VERSION ""

NS_ :

BS_:

BU_: L_DHRR_FD L_UWB_BLE_MST_FD L_UWB_RR_FD L_UWB_BLE_SLV_FD L_UWB_FR_FD L_ROA_FR_FD L_ROA_FD L_DHRL_FD L_UWB_TRNK_FD L_UWB_FRNK_FD L_EDT_FD L_UWB_FL_FD GW_BDC_FD L_UWB_RL_FD L_SAL_FD L_WPC_FD L_TPMS_FD L_DHL_FD L_DHR_FD

BO_ 2348810506 TP_BDC_FD_L_DHRL_FD: 32 GW_BDC_FD
 SG_ TP_BDC_FD_L_DHRL_FD_Byte0 : 0|8@1+ (1,0) [0|0] ""  L_DHRL_FD
 SG_ TP_BDC_FD_L_DHRL_FD_Byte13 : 104|8@1+ (1,0) [0|0] ""  L_DHRL_FD
 SG_ TP_BDC_FD_L_DHRL_FD_Byte14 : 112|8@1+ (1,0) [0|0] ""  L_DHRL_FD
 SG_ TP_BDC_FD_L_DHRL_FD_Byte15 : 120|8@1+ (1,0) [0|0] ""  L_DHRL_FD
 SG_ TP_BDC_FD_L_DHRL_FD_Byte16 : 128|8@1+ (1,0) [0|0] ""  L_DHRL_FD
 SG_ TP_BDC_FD_L_DHRL_FD_Byte17 : 136|8@1+ (1,0) [0|0] ""  L_DHRL_FD
 SG_ TP_BDC_FD_L_DHRL_FD_Byte18 : 144|8@1+ (1,0) [0|0] ""  L_DHRL_FD
 SG_ TP_BDC_FD_L_DHRL_FD_Byte19 : 152|8@1+ (1,0) [0|0] ""  L_DHRL_FD
 SG_ TP_BDC_FD_L_DHRL_FD_Byte2 : 16|8@1+ (1,0) [0|0] ""  L_DHRL_FD
 SG_ TP_BDC_FD_L_DHRL_FD_Byte20 : 160|8@1+ (1,0) [0|0] ""  L_DHRL_FD
 SG_ TP_BDC_FD_L_DHRL_FD_Byte21 : 168|8@1+ (1,0) [0|0] ""  L_DHRL_FD
 SG_ TP_BDC_FD_L_DHRL_FD_Byte22 : 176|8@1+ (1,0) [0|0] ""  L_DHRL_FD
 SG_ TP_BDC_FD_L_DHRL_FD_Byte23 : 184|8@1+ (1,0) [0|0] ""  L_DHRL_FD
 SG_ TP_BDC_FD_L_DHRL_FD_Byte24 : 192|8@1+ (1,0) [0|0] ""  L_DHRL_FD
 SG_ TP_BDC_FD_L_DHRL_FD_Byte25 : 200|8@1+ (1,0) [0|0] ""  L_DHRL_FD
 SG_ TP_BDC_FD_L_DHRL_FD_Byte26 : 208|8@1+ (1,0) [0|0] ""  L_DHRL_FD
 SG_ TP_BDC_FD_L_DHRL_FD_Byte27 : 216|8@1+ (1,0) [0|0] ""  L_DHRL_FD
 SG_ TP_BDC_FD_L_DHRL_FD_Byte28 : 224|8@1+ (1,0) [0|0] ""  L_DHRL_FD
 SG_ TP_BDC_FD_L_DHRL_FD_Byte29 : 232|8@1+ (1,0) [0|0] ""  L_DHRL_FD
 SG_ TP_BDC_FD_L_DHRL_FD_Byte3 : 24|8@1+ (1,0) [0|0] ""  L_DHRL_FD
 SG_ TP_BDC_FD_L_DHRL_FD_Byte30 : 240|8@1+ (1,0) [0|0] ""  L_DHRL_FD
 SG_ TP_BDC_FD_L_DHRL_FD_Byte31 : 248|8@1+ (1,0) [0|0] ""  L_DHRL_FD
 SG_ TP_BDC_FD_L_DHRL_FD_Byte4 : 32|8@1+ (1,0) [0|0] ""  L_DHRL_FD
 SG_ TP_BDC_FD_L_DHRL_FD_Byte5 : 40|8@1+ (1,0) [0|0] ""  L_DHRL_FD
 SG_ TP_BDC_FD_L_DHRL_FD_Byte6 : 48|8@1+ (1,0) [0|0] ""  L_DHRL_FD
 SG_ TP_BDC_FD_L_DHRL_FD_Byte7 : 56|8@1+ (1,0) [0|0] ""  L_DHRL_FD
 SG_ TP_BDC_FD_L_DHRL_FD_Byte8 : 64|8@1+ (1,0) [0|0] ""  L_DHRL_FD
 SG_ TP_BDC_FD_L_DHRL_FD_Byte9 : 72|8@1+ (1,0) [0|0] ""  L_DHRL_FD
 SG_ TP_BDC_FD_L_DHRL_FD_Byte1 : 8|8@1+ (1,0) [0|0] ""  L_DHRL_FD
 SG_ TP_BDC_FD_L_DHRL_FD_Byte10 : 80|8@1+ (1,0) [0|0] ""  L_DHRL_FD
 SG_ TP_BDC_FD_L_DHRL_FD_Byte11 : 88|8@1+ (1,0) [0|0] ""  L_DHRL_FD
 SG_ TP_BDC_FD_L_DHRL_FD_Byte12 : 96|8@1+ (1,0) [0|0] ""  L_DHRL_FD

BO_ 2348810505 L_TP_L_DHR_FD_BDC_FD: 32 L_DHR_FD
 SG_ L_TP_L_DHR_FD_BDC_FD_Byte0 : 0|8@1+ (1,0) [0|0] ""  GW_BDC_FD
 SG_ L_TP_L_DHR_FD_BDC_FD_Byte13 : 104|8@1+ (1,0) [0|0] ""  GW_BDC_FD
 SG_ L_TP_L_DHR_FD_BDC_FD_Byte14 : 112|8@1+ (1,0) [0|0] ""  GW_BDC_FD
 SG_ L_TP_L_DHR_FD_BDC_FD_Byte15 : 120|8@1+ (1,0) [0|0] ""  GW_BDC_FD
 SG_ L_TP_L_DHR_FD_BDC_FD_Byte16 : 128|8@1+ (1,0) [0|0] ""  GW_BDC_FD
 SG_ L_TP_L_DHR_FD_BDC_FD_Byte17 : 136|8@1+ (1,0) [0|0] ""  GW_BDC_FD
 SG_ L_TP_L_DHR_FD_BDC_FD_Byte18 : 144|8@1+ (1,0) [0|0] ""  GW_BDC_FD
 SG_ L_TP_L_DHR_FD_BDC_FD_Byte19 : 152|8@1+ (1,0) [0|0] ""  GW_BDC_FD
 SG_ L_TP_L_DHR_FD_BDC_FD_Byte2 : 16|8@1+ (1,0) [0|0] ""  GW_BDC_FD
 SG_ L_TP_L_DHR_FD_BDC_FD_Byte20 : 160|8@1+ (1,0) [0|0] ""  GW_BDC_FD
 SG_ L_TP_L_DHR_FD_BDC_FD_Byte21 : 168|8@1+ (1,0) [0|0] ""  GW_BDC_FD
 SG_ L_TP_L_DHR_FD_BDC_FD_Byte22 : 176|8@1+ (1,0) [0|0] ""  GW_BDC_FD
 SG_ L_TP_L_DHR_FD_BDC_FD_Byte23 : 184|8@1+ (1,0) [0|0] ""  GW_BDC_FD
 SG_ L_TP_L_DHR_FD_BDC_FD_Byte24 : 192|8@1+ (1,0) [0|0] ""  GW_BDC_FD
 SG_ L_TP_L_DHR_FD_BDC_FD_Byte25 : 200|8@1+ (1,0) [0|0] ""  GW_BDC_FD
 SG_ L_TP_L_DHR_FD_BDC_FD_Byte26 : 208|8@1+ (1,0) [0|0] ""  GW_BDC_FD
 SG_ L_TP_L_DHR_FD_BDC_FD_Byte27 : 216|8@1+ (1,0) [0|0] ""  GW_BDC_FD
 SG_ L_TP_L_DHR_FD_BDC_FD_Byte28 : 224|8@1+ (1,0) [0|0] ""  GW_BDC_FD
 SG_ L_TP_L_DHR_FD_BDC_FD_Byte29 : 232|8@1+ (1,0) [0|0] ""  GW_BDC_FD
 SG_ L_TP_L_DHR_FD_BDC_FD_Byte3 : 24|8@1+ (1,0) [0|0] ""  GW_BDC_FD
 SG_ L_TP_L_DHR_FD_BDC_FD_Byte30 : 240|8@1+ (1,0) [0|0] ""  GW_BDC_FD
 SG_ L_TP_L_DHR_FD_BDC_FD_Byte31 : 248|8@1+ (1,0) [0|0] ""  GW_BDC_FD
 SG_ L_TP_L_DHR_FD_BDC_FD_Byte4 : 32|8@1+ (1,0) [0|0] ""  GW_BDC_FD
 SG_ L_TP_L_DHR_FD_BDC_FD_Byte5 : 40|8@1+ (1,0) [0|0] ""  GW_BDC_FD
 SG_ L_TP_L_DHR_FD_BDC_FD_Byte6 : 48|8@1+ (1,0) [0|0] ""  GW_BDC_FD
 SG_ L_TP_L_DHR_FD_BDC_FD_Byte7 : 56|8@1+ (1,0) [0|0] ""  GW_BDC_FD
 SG_ L_TP_L_DHR_FD_BDC_FD_Byte8 : 64|8@1+ (1,0) [0|0] ""  GW_BDC_FD
 SG_ L_TP_L_DHR_FD_BDC_FD_Byte9 : 72|8@1+ (1,0) [0|0] ""  GW_BDC_FD
 SG_ L_TP_L_DHR_FD_BDC_FD_Byte1 : 8|8@1+ (1,0) [0|0] ""  GW_BDC_FD
 SG_ L_TP_L_DHR_FD_BDC_FD_Byte10 : 80|8@1+ (1,0) [0|0] ""  GW_BDC_FD
 SG_ L_TP_L_DHR_FD_BDC_FD_Byte11 : 88|8@1+ (1,0) [0|0] ""  GW_BDC_FD
 SG_ L_TP_L_DHR_FD_BDC_FD_Byte12 : 96|8@1+ (1,0) [0|0] ""  GW_BDC_FD

BO_ 2348810504 L_TP_BDC_FD_L_DHR_FD: 32 GW_BDC_FD
 SG_ L_TP_BDC_FD_L_DHR_FD_Byte0 : 0|8@1+ (1,0) [0|0] ""  L_DHR_FD
 SG_ L_TP_BDC_FD_L_DHR_FD_Byte13 : 104|8@1+ (1,0) [0|0] ""  L_DHR_FD
 SG_ L_TP_BDC_FD_L_DHR_FD_Byte14 : 112|8@1+ (1,0) [0|0] ""  L_DHR_FD
 SG_ L_TP_BDC_FD_L_DHR_FD_Byte15 : 120|8@1+ (1,0) [0|0] ""  L_DHR_FD
 SG_ L_TP_BDC_FD_L_DHR_FD_Byte16 : 128|8@1+ (1,0) [0|0] ""  L_DHR_FD
 SG_ L_TP_BDC_FD_L_DHR_FD_Byte17 : 136|8@1+ (1,0) [0|0] ""  L_DHR_FD
 SG_ L_TP_BDC_FD_L_DHR_FD_Byte18 : 144|8@1+ (1,0) [0|0] ""  L_DHR_FD
 SG_ L_TP_BDC_FD_L_DHR_FD_Byte19 : 152|8@1+ (1,0) [0|0] ""  L_DHR_FD
 SG_ L_TP_BDC_FD_L_DHR_FD_Byte2 : 16|8@1+ (1,0) [0|0] ""  L_DHR_FD
 SG_ L_TP_BDC_FD_L_DHR_FD_Byte20 : 160|8@1+ (1,0) [0|0] ""  L_DHR_FD
 SG_ L_TP_BDC_FD_L_DHR_FD_Byte21 : 168|8@1+ (1,0) [0|0] ""  L_DHR_FD
 SG_ L_TP_BDC_FD_L_DHR_FD_Byte22 : 176|8@1+ (1,0) [0|0] ""  L_DHR_FD
 SG_ L_TP_BDC_FD_L_DHR_FD_Byte23 : 184|8@1+ (1,0) [0|0] ""  L_DHR_FD
 SG_ L_TP_BDC_FD_L_DHR_FD_Byte24 : 192|8@1+ (1,0) [0|0] ""  L_DHR_FD
 SG_ L_TP_BDC_FD_L_DHR_FD_Byte25 : 200|8@1+ (1,0) [0|0] ""  L_DHR_FD
 SG_ L_TP_BDC_FD_L_DHR_FD_Byte26 : 208|8@1+ (1,0) [0|0] ""  L_DHR_FD
 SG_ L_TP_BDC_FD_L_DHR_FD_Byte27 : 216|8@1+ (1,0) [0|0] ""  L_DHR_FD
 SG_ L_TP_BDC_FD_L_DHR_FD_Byte28 : 224|8@1+ (1,0) [0|0] ""  L_DHR_FD
 SG_ L_TP_BDC_FD_L_DHR_FD_Byte29 : 232|8@1+ (1,0) [0|0] ""  L_DHR_FD
 SG_ L_TP_BDC_FD_L_DHR_FD_Byte3 : 24|8@1+ (1,0) [0|0] ""  L_DHR_FD
 SG_ L_TP_BDC_FD_L_DHR_FD_Byte30 : 240|8@1+ (1,0) [0|0] ""  L_DHR_FD
 SG_ L_TP_BDC_FD_L_DHR_FD_Byte31 : 248|8@1+ (1,0) [0|0] ""  L_DHR_FD
 SG_ L_TP_BDC_FD_L_DHR_FD_Byte4 : 32|8@1+ (1,0) [0|0] ""  L_DHR_FD
 SG_ L_TP_BDC_FD_L_DHR_FD_Byte5 : 40|8@1+ (1,0) [0|0] ""  L_DHR_FD
 SG_ L_TP_BDC_FD_L_DHR_FD_Byte6 : 48|8@1+ (1,0) [0|0] ""  L_DHR_FD
 SG_ L_TP_BDC_FD_L_DHR_FD_Byte7 : 56|8@1+ (1,0) [0|0] ""  L_DHR_FD
 SG_ L_TP_BDC_FD_L_DHR_FD_Byte8 : 64|8@1+ (1,0) [0|0] ""  L_DHR_FD
 SG_ L_TP_BDC_FD_L_DHR_FD_Byte9 : 72|8@1+ (1,0) [0|0] ""  L_DHR_FD
 SG_ L_TP_BDC_FD_L_DHR_FD_Byte1 : 8|8@1+ (1,0) [0|0] ""  L_DHR_FD
 SG_ L_TP_BDC_FD_L_DHR_FD_Byte10 : 80|8@1+ (1,0) [0|0] ""  L_DHR_FD
 SG_ L_TP_BDC_FD_L_DHR_FD_Byte11 : 88|8@1+ (1,0) [0|0] ""  L_DHR_FD
 SG_ L_TP_BDC_FD_L_DHR_FD_Byte12 : 96|8@1+ (1,0) [0|0] ""  L_DHR_FD

BO_ 2348810503 L_TP_L_DHL_FD_BDC_FD: 32 L_DHL_FD
 SG_ L_TP_L_DHL_FD_BDC_FD_Byte0 : 0|8@1+ (1,0) [0|0] ""  GW_BDC_FD
 SG_ L_TP_L_DHL_FD_BDC_FD_Byte13 : 104|8@1+ (1,0) [0|0] ""  GW_BDC_FD
 SG_ L_TP_L_DHL_FD_BDC_FD_Byte14 : 112|8@1+ (1,0) [0|0] ""  GW_BDC_FD
 SG_ L_TP_L_DHL_FD_BDC_FD_Byte15 : 120|8@1+ (1,0) [0|0] ""  GW_BDC_FD
 SG_ L_TP_L_DHL_FD_BDC_FD_Byte16 : 128|8@1+ (1,0) [0|0] ""  GW_BDC_FD
 SG_ L_TP_L_DHL_FD_BDC_FD_Byte17 : 136|8@1+ (1,0) [0|0] ""  GW_BDC_FD
 SG_ L_TP_L_DHL_FD_BDC_FD_Byte18 : 144|8@1+ (1,0) [0|0] ""  GW_BDC_FD
 SG_ L_TP_L_DHL_FD_BDC_FD_Byte19 : 152|8@1+ (1,0) [0|0] ""  GW_BDC_FD
 SG_ L_TP_L_DHL_FD_BDC_FD_Byte2 : 16|8@1+ (1,0) [0|0] ""  GW_BDC_FD
 SG_ L_TP_L_DHL_FD_BDC_FD_Byte20 : 160|8@1+ (1,0) [0|0] ""  GW_BDC_FD
 SG_ L_TP_L_DHL_FD_BDC_FD_Byte21 : 168|8@1+ (1,0) [0|0] ""  GW_BDC_FD
 SG_ L_TP_L_DHL_FD_BDC_FD_Byte22 : 176|8@1+ (1,0) [0|0] ""  GW_BDC_FD
 SG_ L_TP_L_DHL_FD_BDC_FD_Byte23 : 184|8@1+ (1,0) [0|0] ""  GW_BDC_FD
 SG_ L_TP_L_DHL_FD_BDC_FD_Byte24 : 192|8@1+ (1,0) [0|0] ""  GW_BDC_FD
 SG_ L_TP_L_DHL_FD_BDC_FD_Byte25 : 200|8@1+ (1,0) [0|0] ""  GW_BDC_FD
 SG_ L_TP_L_DHL_FD_BDC_FD_Byte26 : 208|8@1+ (1,0) [0|0] ""  GW_BDC_FD
 SG_ L_TP_L_DHL_FD_BDC_FD_Byte27 : 216|8@1+ (1,0) [0|0] ""  GW_BDC_FD
 SG_ L_TP_L_DHL_FD_BDC_FD_Byte28 : 224|8@1+ (1,0) [0|0] ""  GW_BDC_FD
 SG_ L_TP_L_DHL_FD_BDC_FD_Byte29 : 232|8@1+ (1,0) [0|0] ""  GW_BDC_FD
 SG_ L_TP_L_DHL_FD_BDC_FD_Byte3 : 24|8@1+ (1,0) [0|0] ""  GW_BDC_FD
 SG_ L_TP_L_DHL_FD_BDC_FD_Byte30 : 240|8@1+ (1,0) [0|0] ""  GW_BDC_FD
 SG_ L_TP_L_DHL_FD_BDC_FD_Byte31 : 248|8@1+ (1,0) [0|0] ""  GW_BDC_FD
 SG_ L_TP_L_DHL_FD_BDC_FD_Byte4 : 32|8@1+ (1,0) [0|0] ""  GW_BDC_FD
 SG_ L_TP_L_DHL_FD_BDC_FD_Byte5 : 40|8@1+ (1,0) [0|0] ""  GW_BDC_FD
 SG_ L_TP_L_DHL_FD_BDC_FD_Byte6 : 48|8@1+ (1,0) [0|0] ""  GW_BDC_FD
 SG_ L_TP_L_DHL_FD_BDC_FD_Byte7 : 56|8@1+ (1,0) [0|0] ""  GW_BDC_FD
 SG_ L_TP_L_DHL_FD_BDC_FD_Byte8 : 64|8@1+ (1,0) [0|0] ""  GW_BDC_FD
 SG_ L_TP_L_DHL_FD_BDC_FD_Byte9 : 72|8@1+ (1,0) [0|0] ""  GW_BDC_FD
 SG_ L_TP_L_DHL_FD_BDC_FD_Byte1 : 8|8@1+ (1,0) [0|0] ""  GW_BDC_FD
 SG_ L_TP_L_DHL_FD_BDC_FD_Byte10 : 80|8@1+ (1,0) [0|0] ""  GW_BDC_FD
 SG_ L_TP_L_DHL_FD_BDC_FD_Byte11 : 88|8@1+ (1,0) [0|0] ""  GW_BDC_FD
 SG_ L_TP_L_DHL_FD_BDC_FD_Byte12 : 96|8@1+ (1,0) [0|0] ""  GW_BDC_FD

BO_ 2214592660 L_DHR_FD_Dvp_01_00ms: 32 L_DHR_FD
 SG_ DHR_Dvp_Msg : 0|255@1+ (1,0) [0|0] ""  L_EDT_FD

BO_ 2348810502 L_TP_BDC_FD_L_DHL_FD: 32 GW_BDC_FD
 SG_ L_TP_BDC_FD_L_DHL_FD_Byte0 : 0|8@1+ (1,0) [0|0] ""  L_DHL_FD
 SG_ L_TP_BDC_FD_L_DHL_FD_Byte13 : 104|8@1+ (1,0) [0|0] ""  L_DHL_FD
 SG_ L_TP_BDC_FD_L_DHL_FD_Byte14 : 112|8@1+ (1,0) [0|0] ""  L_DHL_FD
 SG_ L_TP_BDC_FD_L_DHL_FD_Byte15 : 120|8@1+ (1,0) [0|0] ""  L_DHL_FD
 SG_ L_TP_BDC_FD_L_DHL_FD_Byte16 : 128|8@1+ (1,0) [0|0] ""  L_DHL_FD
 SG_ L_TP_BDC_FD_L_DHL_FD_Byte17 : 136|8@1+ (1,0) [0|0] ""  L_DHL_FD
 SG_ L_TP_BDC_FD_L_DHL_FD_Byte18 : 144|8@1+ (1,0) [0|0] ""  L_DHL_FD
 SG_ L_TP_BDC_FD_L_DHL_FD_Byte19 : 152|8@1+ (1,0) [0|0] ""  L_DHL_FD
 SG_ L_TP_BDC_FD_L_DHL_FD_Byte2 : 16|8@1+ (1,0) [0|0] ""  L_DHL_FD
 SG_ L_TP_BDC_FD_L_DHL_FD_Byte20 : 160|8@1+ (1,0) [0|0] ""  L_DHL_FD
 SG_ L_TP_BDC_FD_L_DHL_FD_Byte21 : 168|8@1+ (1,0) [0|0] ""  L_DHL_FD
 SG_ L_TP_BDC_FD_L_DHL_FD_Byte22 : 176|8@1+ (1,0) [0|0] ""  L_DHL_FD
 SG_ L_TP_BDC_FD_L_DHL_FD_Byte23 : 184|8@1+ (1,0) [0|0] ""  L_DHL_FD
 SG_ L_TP_BDC_FD_L_DHL_FD_Byte24 : 192|8@1+ (1,0) [0|0] ""  L_DHL_FD
 SG_ L_TP_BDC_FD_L_DHL_FD_Byte25 : 200|8@1+ (1,0) [0|0] ""  L_DHL_FD
 SG_ L_TP_BDC_FD_L_DHL_FD_Byte26 : 208|8@1+ (1,0) [0|0] ""  L_DHL_FD
 SG_ L_TP_BDC_FD_L_DHL_FD_Byte27 : 216|8@1+ (1,0) [0|0] ""  L_DHL_FD
 SG_ L_TP_BDC_FD_L_DHL_FD_Byte28 : 224|8@1+ (1,0) [0|0] ""  L_DHL_FD
 SG_ L_TP_BDC_FD_L_DHL_FD_Byte29 : 232|8@1+ (1,0) [0|0] ""  L_DHL_FD
 SG_ L_TP_BDC_FD_L_DHL_FD_Byte3 : 24|8@1+ (1,0) [0|0] ""  L_DHL_FD
 SG_ L_TP_BDC_FD_L_DHL_FD_Byte30 : 240|8@1+ (1,0) [0|0] ""  L_DHL_FD
 SG_ L_TP_BDC_FD_L_DHL_FD_Byte31 : 248|8@1+ (1,0) [0|0] ""  L_DHL_FD
 SG_ L_TP_BDC_FD_L_DHL_FD_Byte4 : 32|8@1+ (1,0) [0|0] ""  L_DHL_FD
 SG_ L_TP_BDC_FD_L_DHL_FD_Byte5 : 40|8@1+ (1,0) [0|0] ""  L_DHL_FD
 SG_ L_TP_BDC_FD_L_DHL_FD_Byte6 : 48|8@1+ (1,0) [0|0] ""  L_DHL_FD
 SG_ L_TP_BDC_FD_L_DHL_FD_Byte7 : 56|8@1+ (1,0) [0|0] ""  L_DHL_FD
 SG_ L_TP_BDC_FD_L_DHL_FD_Byte8 : 64|8@1+ (1,0) [0|0] ""  L_DHL_FD
 SG_ L_TP_BDC_FD_L_DHL_FD_Byte9 : 72|8@1+ (1,0) [0|0] ""  L_DHL_FD
 SG_ L_TP_BDC_FD_L_DHL_FD_Byte1 : 8|8@1+ (1,0) [0|0] ""  L_DHL_FD
 SG_ L_TP_BDC_FD_L_DHL_FD_Byte10 : 80|8@1+ (1,0) [0|0] ""  L_DHL_FD
 SG_ L_TP_BDC_FD_L_DHL_FD_Byte11 : 88|8@1+ (1,0) [0|0] ""  L_DHL_FD
 SG_ L_TP_BDC_FD_L_DHL_FD_Byte12 : 96|8@1+ (1,0) [0|0] ""  L_DHL_FD

BO_ 2214592661 L_DHRR_FD_Dvp_01_00ms: 32 L_DHRR_FD
 SG_ DHRR_Dvp_Msg : 0|255@1+ (1,0) [0|0] ""  L_EDT_FD

BO_ 2348810501 L_TP_L_WPC_FD_BDC_FD: 32 L_WPC_FD
 SG_ L_TP_L_WPC_FD_BDC_FD_Byte0 : 0|8@1+ (1,0) [0|0] ""  GW_BDC_FD
 SG_ L_TP_L_WPC_FD_BDC_FD_Byte13 : 104|8@1+ (1,0) [0|0] ""  GW_BDC_FD
 SG_ L_TP_L_WPC_FD_BDC_FD_Byte14 : 112|8@1+ (1,0) [0|0] ""  GW_BDC_FD
 SG_ L_TP_L_WPC_FD_BDC_FD_Byte15 : 120|8@1+ (1,0) [0|0] ""  GW_BDC_FD
 SG_ L_TP_L_WPC_FD_BDC_FD_Byte16 : 128|8@1+ (1,0) [0|0] ""  GW_BDC_FD
 SG_ L_TP_L_WPC_FD_BDC_FD_Byte17 : 136|8@1+ (1,0) [0|0] ""  GW_BDC_FD
 SG_ L_TP_L_WPC_FD_BDC_FD_Byte18 : 144|8@1+ (1,0) [0|0] ""  GW_BDC_FD
 SG_ L_TP_L_WPC_FD_BDC_FD_Byte19 : 152|8@1+ (1,0) [0|0] ""  GW_BDC_FD
 SG_ L_TP_L_WPC_FD_BDC_FD_Byte2 : 16|8@1+ (1,0) [0|0] ""  GW_BDC_FD
 SG_ L_TP_L_WPC_FD_BDC_FD_Byte20 : 160|8@1+ (1,0) [0|0] ""  GW_BDC_FD
 SG_ L_TP_L_WPC_FD_BDC_FD_Byte21 : 168|8@1+ (1,0) [0|0] ""  GW_BDC_FD
 SG_ L_TP_L_WPC_FD_BDC_FD_Byte22 : 176|8@1+ (1,0) [0|0] ""  GW_BDC_FD
 SG_ L_TP_L_WPC_FD_BDC_FD_Byte23 : 184|8@1+ (1,0) [0|0] ""  GW_BDC_FD
 SG_ L_TP_L_WPC_FD_BDC_FD_Byte24 : 192|8@1+ (1,0) [0|0] ""  GW_BDC_FD
 SG_ L_TP_L_WPC_FD_BDC_FD_Byte25 : 200|8@1+ (1,0) [0|0] ""  GW_BDC_FD
 SG_ L_TP_L_WPC_FD_BDC_FD_Byte26 : 208|8@1+ (1,0) [0|0] ""  GW_BDC_FD
 SG_ L_TP_L_WPC_FD_BDC_FD_Byte27 : 216|8@1+ (1,0) [0|0] ""  GW_BDC_FD
 SG_ L_TP_L_WPC_FD_BDC_FD_Byte28 : 224|8@1+ (1,0) [0|0] ""  GW_BDC_FD
 SG_ L_TP_L_WPC_FD_BDC_FD_Byte29 : 232|8@1+ (1,0) [0|0] ""  GW_BDC_FD
 SG_ L_TP_L_WPC_FD_BDC_FD_Byte3 : 24|8@1+ (1,0) [0|0] ""  GW_BDC_FD
 SG_ L_TP_L_WPC_FD_BDC_FD_Byte30 : 240|8@1+ (1,0) [0|0] ""  GW_BDC_FD
 SG_ L_TP_L_WPC_FD_BDC_FD_Byte31 : 248|8@1+ (1,0) [0|0] ""  GW_BDC_FD
 SG_ L_TP_L_WPC_FD_BDC_FD_Byte4 : 32|8@1+ (1,0) [0|0] ""  GW_BDC_FD
 SG_ L_TP_L_WPC_FD_BDC_FD_Byte5 : 40|8@1+ (1,0) [0|0] ""  GW_BDC_FD
 SG_ L_TP_L_WPC_FD_BDC_FD_Byte6 : 48|8@1+ (1,0) [0|0] ""  GW_BDC_FD
 SG_ L_TP_L_WPC_FD_BDC_FD_Byte7 : 56|8@1+ (1,0) [0|0] ""  GW_BDC_FD
 SG_ L_TP_L_WPC_FD_BDC_FD_Byte8 : 64|8@1+ (1,0) [0|0] ""  GW_BDC_FD
 SG_ L_TP_L_WPC_FD_BDC_FD_Byte9 : 72|8@1+ (1,0) [0|0] ""  GW_BDC_FD
 SG_ L_TP_L_WPC_FD_BDC_FD_Byte1 : 8|8@1+ (1,0) [0|0] ""  GW_BDC_FD
 SG_ L_TP_L_WPC_FD_BDC_FD_Byte10 : 80|8@1+ (1,0) [0|0] ""  GW_BDC_FD
 SG_ L_TP_L_WPC_FD_BDC_FD_Byte11 : 88|8@1+ (1,0) [0|0] ""  GW_BDC_FD
 SG_ L_TP_L_WPC_FD_BDC_FD_Byte12 : 96|8@1+ (1,0) [0|0] ""  GW_BDC_FD

BO_ 2348810500 L_TP_BDC_FD_L_WPC_FD: 32 GW_BDC_FD
 SG_ L_TP_BDC_FD_L_WPC_FD_Byte0 : 0|8@1+ (1,0) [0|0] ""  L_WPC_FD
 SG_ L_TP_BDC_FD_L_WPC_FD_Byte13 : 104|8@1+ (1,0) [0|0] ""  L_WPC_FD
 SG_ L_TP_BDC_FD_L_WPC_FD_Byte14 : 112|8@1+ (1,0) [0|0] ""  L_WPC_FD
 SG_ L_TP_BDC_FD_L_WPC_FD_Byte15 : 120|8@1+ (1,0) [0|0] ""  L_WPC_FD
 SG_ L_TP_BDC_FD_L_WPC_FD_Byte16 : 128|8@1+ (1,0) [0|0] ""  L_WPC_FD
 SG_ L_TP_BDC_FD_L_WPC_FD_Byte17 : 136|8@1+ (1,0) [0|0] ""  L_WPC_FD
 SG_ L_TP_BDC_FD_L_WPC_FD_Byte18 : 144|8@1+ (1,0) [0|0] ""  L_WPC_FD
 SG_ L_TP_BDC_FD_L_WPC_FD_Byte19 : 152|8@1+ (1,0) [0|0] ""  L_WPC_FD
 SG_ L_TP_BDC_FD_L_WPC_FD_Byte2 : 16|8@1+ (1,0) [0|0] ""  L_WPC_FD
 SG_ L_TP_BDC_FD_L_WPC_FD_Byte20 : 160|8@1+ (1,0) [0|0] ""  L_WPC_FD
 SG_ L_TP_BDC_FD_L_WPC_FD_Byte21 : 168|8@1+ (1,0) [0|0] ""  L_WPC_FD
 SG_ L_TP_BDC_FD_L_WPC_FD_Byte22 : 176|8@1+ (1,0) [0|0] ""  L_WPC_FD
 SG_ L_TP_BDC_FD_L_WPC_FD_Byte23 : 184|8@1+ (1,0) [0|0] ""  L_WPC_FD
 SG_ L_TP_BDC_FD_L_WPC_FD_Byte24 : 192|8@1+ (1,0) [0|0] ""  L_WPC_FD
 SG_ L_TP_BDC_FD_L_WPC_FD_Byte25 : 200|8@1+ (1,0) [0|0] ""  L_WPC_FD
 SG_ L_TP_BDC_FD_L_WPC_FD_Byte26 : 208|8@1+ (1,0) [0|0] ""  L_WPC_FD
 SG_ L_TP_BDC_FD_L_WPC_FD_Byte27 : 216|8@1+ (1,0) [0|0] ""  L_WPC_FD
 SG_ L_TP_BDC_FD_L_WPC_FD_Byte28 : 224|8@1+ (1,0) [0|0] ""  L_WPC_FD
 SG_ L_TP_BDC_FD_L_WPC_FD_Byte29 : 232|8@1+ (1,0) [0|0] ""  L_WPC_FD
 SG_ L_TP_BDC_FD_L_WPC_FD_Byte3 : 24|8@1+ (1,0) [0|0] ""  L_WPC_FD
 SG_ L_TP_BDC_FD_L_WPC_FD_Byte30 : 240|8@1+ (1,0) [0|0] ""  L_WPC_FD
 SG_ L_TP_BDC_FD_L_WPC_FD_Byte31 : 248|8@1+ (1,0) [0|0] ""  L_WPC_FD
 SG_ L_TP_BDC_FD_L_WPC_FD_Byte4 : 32|8@1+ (1,0) [0|0] ""  L_WPC_FD
 SG_ L_TP_BDC_FD_L_WPC_FD_Byte5 : 40|8@1+ (1,0) [0|0] ""  L_WPC_FD
 SG_ L_TP_BDC_FD_L_WPC_FD_Byte6 : 48|8@1+ (1,0) [0|0] ""  L_WPC_FD
 SG_ L_TP_BDC_FD_L_WPC_FD_Byte7 : 56|8@1+ (1,0) [0|0] ""  L_WPC_FD
 SG_ L_TP_BDC_FD_L_WPC_FD_Byte8 : 64|8@1+ (1,0) [0|0] ""  L_WPC_FD
 SG_ L_TP_BDC_FD_L_WPC_FD_Byte9 : 72|8@1+ (1,0) [0|0] ""  L_WPC_FD
 SG_ L_TP_BDC_FD_L_WPC_FD_Byte1 : 8|8@1+ (1,0) [0|0] ""  L_WPC_FD
 SG_ L_TP_BDC_FD_L_WPC_FD_Byte10 : 80|8@1+ (1,0) [0|0] ""  L_WPC_FD
 SG_ L_TP_BDC_FD_L_WPC_FD_Byte11 : 88|8@1+ (1,0) [0|0] ""  L_WPC_FD
 SG_ L_TP_BDC_FD_L_WPC_FD_Byte12 : 96|8@1+ (1,0) [0|0] ""  L_WPC_FD

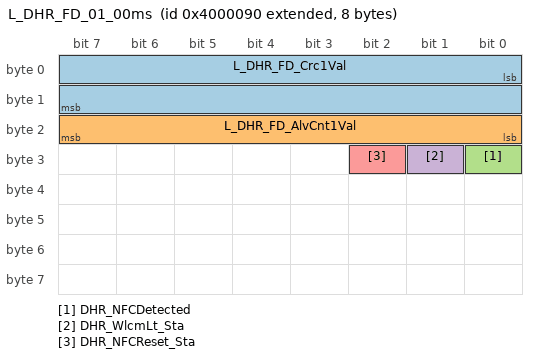
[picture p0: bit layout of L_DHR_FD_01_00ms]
BO_ 2214592656 L_DHR_FD_01_00ms: 8 L_DHR_FD
 SG_ L_DHR_FD_Crc1Val : 0|16@1+ (1,0) [0|0] "0" Vector__XXX
 SG_ L_DHR_FD_AlvCnt1Val : 16|8@1+ (1,0) [0|0] "0" Vector__XXX
 SG_ DHR_NFCDetected : 24|1@1+ (1,0) [0|0] ""  GW_BDC_FD
 SG_ DHR_WlcmLt_Sta : 25|1@1+ (1,0) [0|0] ""  GW_BDC_FD
 SG_ DHR_NFCReset_Sta : 26|1@1+ (1,0) [0|0] ""  GW_BDC_FD

BO_ 2348810499 L_TP_L_UWB_BLE_SLV_FD_BDC_FD: 32 L_UWB_BLE_SLV_FD
 SG_ L_TP_L_UWB_BLE_SLV_FD_BDC_FD_Byt : 0|8@1+ (1,0) [0|0] ""  GW_BDC_FD
 SG_ L_TP_L_UWB_BLE_SLV_FD_BDC_F_0000 : 104|8@1+ (1,0) [0|0] ""  GW_BDC_FD
 SG_ L_TP_L_UWB_BLE_SLV_FD_BDC_F_0001 : 112|8@1+ (1,0) [0|0] ""  GW_BDC_FD
 SG_ L_TP_L_UWB_BLE_SLV_FD_BDC_F_0002 : 120|8@1+ (1,0) [0|0] ""  GW_BDC_FD
 SG_ L_TP_L_UWB_BLE_SLV_FD_BDC_F_0003 : 128|8@1+ (1,0) [0|0] ""  GW_BDC_FD
 SG_ L_TP_L_UWB_BLE_SLV_FD_BDC_F_0004 : 136|8@1+ (1,0) [0|0] ""  GW_BDC_FD
 SG_ L_TP_L_UWB_BLE_SLV_FD_BDC_F_0005 : 144|8@1+ (1,0) [0|0] ""  GW_BDC_FD
 SG_ L_TP_L_UWB_BLE_SLV_FD_BDC_F_0006 : 152|8@1+ (1,0) [0|0] ""  GW_BDC_FD
 SG_ L_TP_L_UWB_BLE_SLV_FD_BDC_F_0007 : 16|8@1+ (1,0) [0|0] ""  GW_BDC_FD
 SG_ L_TP_L_UWB_BLE_SLV_FD_BDC_F_0008 : 160|8@1+ (1,0) [0|0] ""  GW_BDC_FD
 SG_ L_TP_L_UWB_BLE_SLV_FD_BDC_F_0009 : 168|8@1+ (1,0) [0|0] ""  GW_BDC_FD
 SG_ L_TP_L_UWB_BLE_SLV_FD_BDC_F_0010 : 176|8@1+ (1,0) [0|0] ""  GW_BDC_FD
 SG_ L_TP_L_UWB_BLE_SLV_FD_BDC_F_0011 : 184|8@1+ (1,0) [0|0] ""  GW_BDC_FD
 SG_ L_TP_L_UWB_BLE_SLV_FD_BDC_F_0012 : 192|8@1+ (1,0) [0|0] ""  GW_BDC_FD
 SG_ L_TP_L_UWB_BLE_SLV_FD_BDC_F_0013 : 200|8@1+ (1,0) [0|0] ""  GW_BDC_FD
 SG_ L_TP_L_UWB_BLE_SLV_FD_BDC_F_0014 : 208|8@1+ (1,0) [0|0] ""  GW_BDC_FD
 SG_ L_TP_L_UWB_BLE_SLV_FD_BDC_F_0015 : 216|8@1+ (1,0) [0|0] ""  GW_BDC_FD
 SG_ L_TP_L_UWB_BLE_SLV_FD_BDC_F_0016 : 224|8@1+ (1,0) [0|0] ""  GW_BDC_FD
 SG_ L_TP_L_UWB_BLE_SLV_FD_BDC_F_0017 : 232|8@1+ (1,0) [0|0] ""  GW_BDC_FD
 SG_ L_TP_L_UWB_BLE_SLV_FD_BDC_F_0018 : 24|8@1+ (1,0) [0|0] ""  GW_BDC_FD
 SG_ L_TP_L_UWB_BLE_SLV_FD_BDC_F_0019 : 240|8@1+ (1,0) [0|0] ""  GW_BDC_FD
 SG_ L_TP_L_UWB_BLE_SLV_FD_BDC_F_0020 : 248|8@1+ (1,0) [0|0] ""  GW_BDC_FD
 SG_ L_TP_L_UWB_BLE_SLV_FD_BDC_F_0021 : 32|8@1+ (1,0) [0|0] ""  GW_BDC_FD
 SG_ L_TP_L_UWB_BLE_SLV_FD_BDC_F_0022 : 40|8@1+ (1,0) [0|0] ""  GW_BDC_FD
 SG_ L_TP_L_UWB_BLE_SLV_FD_BDC_F_0023 : 48|8@1+ (1,0) [0|0] ""  GW_BDC_FD
 SG_ L_TP_L_UWB_BLE_SLV_FD_BDC_F_0024 : 56|8@1+ (1,0) [0|0] ""  GW_BDC_FD
 SG_ L_TP_L_UWB_BLE_SLV_FD_BDC_F_0025 : 64|8@1+ (1,0) [0|0] ""  GW_BDC_FD
 SG_ L_TP_L_UWB_BLE_SLV_FD_BDC_F_0026 : 72|8@1+ (1,0) [0|0] ""  GW_BDC_FD
 SG_ L_TP_L_UWB_BLE_SLV_FD_BDC_F_0027 : 8|8@1+ (1,0) [0|0] ""  GW_BDC_FD
 SG_ L_TP_L_UWB_BLE_SLV_FD_BDC_F_0028 : 80|8@1+ (1,0) [0|0] ""  GW_BDC_FD
 SG_ L_TP_L_UWB_BLE_SLV_FD_BDC_F_0029 : 88|8@1+ (1,0) [0|0] ""  GW_BDC_FD
 SG_ L_TP_L_UWB_BLE_SLV_FD_BDC_F_0030 : 96|8@1+ (1,0) [0|0] ""  GW_BDC_FD

CM_ BO_ 2348810506 "[TP] Transport Protocol";
CM_ BO_ 2348810505 "[TP] Transport Protocol";
CM_ BO_ 2348810504 "[TP] Transport Protocol";
CM_ BO_ 2348810503 "[TP] Transport Protocol";
CM_ BO_ 2214592660 "[EW] On Event and On Write";
CM_ SG_ 2214592660 DHR_Dvp_Msg "Development Message";
CM_ BO_ 2348810502 "[TP] Transport Protocol";
CM_ BO_ 2214592661 "[EW] On Event and On Write";
CM_ SG_ 2214592661 DHRR_Dvp_Msg "Rear RH Door Development Message";
CM_ BO_ 2348810501 "[TP] Transport Protocol";
CM_ BO_ 2348810500 "[TP] Transport Protocol";
CM_ BO_ 2214592656 "[EC] On Event and On Change";
CM_ SG_ 2214592656 L_DHR_FD_Crc1Val "L_DHR_FD_CyclicRedundancyCheck1Value";
CM_ SG_ 2214592656 L_DHR_FD_AlvCnt1Val "L_DHR_FD_AliveCounter1Value";
CM_ SG_ 2214592656 DHR_NFCDetected "RH Door NFC Sensor Input";
CM_ SG_ 2214592656 DHR_WlcmLt_Sta "RH Door Welcome Light Status";
CM_ SG_ 2214592656 DHR_NFCReset_Sta "RH Door NFC DeSelect Result";
CM_ BO_ 2348810499 "[TP] Transport Protocol";
BA_DEF_ BO_  "CANFD_BRS" ENUM  "0","1";
BA_DEF_ BO_  "GenMsgEVName" STRING ;
BA_DEF_ BO_  "NmAsrMessage" ENUM  "No","Yes";
BA_DEF_ BO_  "DiagState" ENUM  "No","Yes";
BA_DEF_ BO_  "DiagResponse" ENUM  "No","Yes";
BA_DEF_ BO_  "DiagRequest" ENUM  "No","Yes";
BA_DEF_ BO_  "TpMessage" ENUM  "No","Yes";
BA_DEF_ BO_  "UsrMsgIDSforwardDeviation" INT 0 100;
BA_DEF_ BO_  "UsrMsgIDSbackwardDeviation" INT 50 1000;
BA_DEF_ BO_  "GenMsgCycleTime" INT 0 2000;
BA_DEF_ BO_  "GenMsgStartDelayTime" INT 0 2000;
BA_DEF_ BO_  "GenMsgSendType" ENUM  "Cyclic","NoMsgSendType";
BA_DEF_ BO_  "GenMsgCycleTimeFast" INT 0 500;
BA_DEF_ BO_  "GenMsgDelayTime" INT 0 20;
BA_DEF_ BO_  "GenMsgILSupport" ENUM  "No","Yes";
BA_DEF_ BO_  "GenMsgNrOfRepetition" INT 0 3;
BA_DEF_ BO_  "TpTxIndex" INT 0 65535;
BA_DEF_ BO_  "VFrameFormat" ENUM  "StandardCAN","ExtendedCAN","reserved","reserved","reserved","reserved","reserved","reserved","reserved","reserved","reserved","reserved","reserved","reserved","StandardCAN_FD","ExtendedCAN_FD";
BA_DEF_ SG_  "UserSigValidity" ENUM  "B+","ACC","IG","IG1","IG2","IG3","IG1 or IG2","IG1 or IG3","Undef";
BA_DEF_ SG_  "TimeoutValue" STRING ;
BA_DEF_ SG_  "UsrSigPurpose" ENUM  "Undef","FN","DIAG","DIAG(Req)","DIAG(Res)","DIAG(Func)","DEV","CCP","NM","TP";
BA_DEF_ SG_  "GenSigStartValue" INT 0 1215752192;
BA_DEF_ SG_  "NetworkRequest" ENUM  "Yes","No";
BA_DEF_ SG_  "NetworkRequestHoldingTime" INT 0 65535;
BA_DEF_ SG_  "Description" STRING ;
BA_DEF_ SG_  "Version" STRING ;
BA_DEF_ SG_  "GenSigEnvVarType" ENUM  "Int","Float","Undef";
BA_DEF_ SG_  "GenSigSendType" ENUM  "Cyclic","OnWrite","OnWriteWithRepetition","OnChange","OnChangeWithRepetition","IfActive","IfActiveWithRepetition","NoSigSendType","OnChangeAndIfActive","OnChangeAndIfActiveWithRepetition";
BA_DEF_ SG_  "GwSigLatencyTime" INT 0 65536;
BA_DEF_ SG_  "GwSigMissingSourceType" ENUM  "Undef","OldValue","DefaultValue","InitialValue";
BA_DEF_ SG_  "NWM-WakeupAllowed" ENUM  "<n.a.>";
BA_DEF_ SG_  "RoutingFactor" INT 1 1215752192;
BA_DEF_ SG_  "SystemSignalLongSymbol" STRING ;
BA_DEF_REL_ BU_SG_REL_  "GenSigTimeoutTime" INT 0 7000;
BA_DEF_DEF_  "CANFD_BRS" "1";
BA_DEF_DEF_  "GenMsgEVName" "@Signame";
BA_DEF_DEF_  "NmAsrMessage" "No";
BA_DEF_DEF_  "DiagState" "No";
BA_DEF_DEF_  "DiagResponse" "No";
BA_DEF_DEF_  "DiagRequest" "No";
BA_DEF_DEF_  "TpMessage" "No";
BA_DEF_DEF_  "UsrMsgIDSforwardDeviation" 10;
BA_DEF_DEF_  "UsrMsgIDSbackwardDeviation" 100;
BA_DEF_DEF_  "GenMsgCycleTime" 200;
BA_DEF_DEF_  "GenMsgStartDelayTime" 0;
BA_DEF_DEF_  "GenMsgSendType" "NoMsgSendType";
BA_DEF_DEF_  "GenMsgCycleTimeFast" 40;
BA_DEF_DEF_  "GenMsgDelayTime" 20;
BA_DEF_DEF_  "GenMsgILSupport" "Yes";
BA_DEF_DEF_  "GenMsgNrOfRepetition" 3;
BA_DEF_DEF_  "TpTxIndex" 0;
BA_DEF_DEF_  "VFrameFormat" "StandardCAN";
BA_DEF_DEF_  "UserSigValidity" "IG";
BA_DEF_DEF_  "TimeoutValue" "";
BA_DEF_DEF_  "UsrSigPurpose" "FN";
BA_DEF_DEF_  "GenSigStartValue" 0;
BA_DEF_DEF_  "NetworkRequest" "No";
BA_DEF_DEF_  "NetworkRequestHoldingTime" 0;
BA_DEF_DEF_  "Description" "";
BA_DEF_DEF_  "Version" "";
BA_DEF_DEF_  "GenSigEnvVarType" "Undef";
BA_DEF_DEF_  "GenSigSendType" "NoSigSendType";
BA_DEF_DEF_  "GwSigLatencyTime" 40;
BA_DEF_DEF_  "GwSigMissingSourceType" "Undef";
BA_DEF_DEF_  "NWM-WakeupAllowed" "<n.a.>";
BA_DEF_DEF_  "RoutingFactor" 1;
BA_DEF_DEF_REL_ "GenSigTimeoutTime" 500;
BA_DEF_DEF_  "SystemSignalLongSymbol" "";
BA_ "TpTxIndex" BO_ 2348810506 275;
BA_ "TpMessage" BO_ 2348810506 1;
BA_ "GenMsgILSupport" BO_ 2348810506 0;
BA_ "GenMsgNrOfRepetition" BO_ 2348810506 0;
BA_ "GenMsgCycleTimeFast" BO_ 2348810506 0;
BA_ "GenMsgCycleTime" BO_ 2348810506 0;
BA_ "VFrameFormat" BO_ 2348810506 15;
BA_ "TpTxIndex" BO_ 2348810505 274;
BA_ "TpMessage" BO_ 2348810505 1;
BA_ "GenMsgILSupport" BO_ 2348810505 0;
BA_ "GenMsgNrOfRepetition" BO_ 2348810505 0;
BA_ "GenMsgCycleTimeFast" BO_ 2348810505 0;
BA_ "GenMsgCycleTime" BO_ 2348810505 0;
BA_ "VFrameFormat" BO_ 2348810505 15;
BA_ "TpTxIndex" BO_ 2348810504 274;
BA_ "TpMessage" BO_ 2348810504 1;
BA_ "GenMsgILSupport" BO_ 2348810504 0;
BA_ "GenMsgNrOfRepetition" BO_ 2348810504 0;
BA_ "GenMsgCycleTimeFast" BO_ 2348810504 0;
BA_ "GenMsgCycleTime" BO_ 2348810504 0;
BA_ "VFrameFormat" BO_ 2348810504 15;
BA_ "TpTxIndex" BO_ 2348810503 273;
BA_ "TpMessage" BO_ 2348810503 1;
BA_ "GenMsgILSupport" BO_ 2348810503 0;
BA_ "GenMsgNrOfRepetition" BO_ 2348810503 0;
BA_ "GenMsgCycleTimeFast" BO_ 2348810503 0;
BA_ "GenMsgCycleTime" BO_ 2348810503 0;
BA_ "VFrameFormat" BO_ 2348810503 15;
BA_ "GenMsgDelayTime" BO_ 2214592660 10;
BA_ "GenMsgCycleTime" BO_ 2214592660 0;
BA_ "VFrameFormat" BO_ 2214592660 15;
BA_ "TpTxIndex" BO_ 2348810502 273;
BA_ "TpMessage" BO_ 2348810502 1;
BA_ "GenMsgILSupport" BO_ 2348810502 0;
BA_ "GenMsgNrOfRepetition" BO_ 2348810502 0;
BA_ "GenMsgCycleTimeFast" BO_ 2348810502 0;
BA_ "GenMsgCycleTime" BO_ 2348810502 0;
BA_ "VFrameFormat" BO_ 2348810502 15;
BA_ "GenMsgDelayTime" BO_ 2214592661 10;
BA_ "GenMsgCycleTime" BO_ 2214592661 0;
BA_ "VFrameFormat" BO_ 2214592661 15;
BA_ "TpTxIndex" BO_ 2348810501 272;
BA_ "TpMessage" BO_ 2348810501 1;
BA_ "GenMsgILSupport" BO_ 2348810501 0;
BA_ "GenMsgNrOfRepetition" BO_ 2348810501 0;
BA_ "GenMsgCycleTimeFast" BO_ 2348810501 0;
BA_ "GenMsgCycleTime" BO_ 2348810501 0;
BA_ "VFrameFormat" BO_ 2348810501 15;
BA_ "TpTxIndex" BO_ 2348810500 272;
BA_ "TpMessage" BO_ 2348810500 1;
BA_ "GenMsgILSupport" BO_ 2348810500 0;
BA_ "GenMsgNrOfRepetition" BO_ 2348810500 0;
BA_ "GenMsgCycleTimeFast" BO_ 2348810500 0;
BA_ "GenMsgCycleTime" BO_ 2348810500 0;
BA_ "VFrameFormat" BO_ 2348810500 15;
BA_ "GenMsgCycleTime" BO_ 2214592656 0;
BA_ "VFrameFormat" BO_ 2214592656 15;
BA_ "TpTxIndex" BO_ 2348810499 271;
BA_ "TpMessage" BO_ 2348810499 1;
BA_ "GenMsgILSupport" BO_ 2348810499 0;
BA_ "GenMsgNrOfRepetition" BO_ 2348810499 0;
BA_ "GenMsgCycleTimeFast" BO_ 2348810499 0;
BA_ "GenMsgCycleTime" BO_ 2348810499 0;
BA_ "VFrameFormat" BO_ 2348810499 15;
BA_ "Version" SG_ 2348810506 TP_BDC_FD_L_DHRL_FD_Byte0 "23.06.01";
BA_ "NetworkRequestHoldingTime" SG_ 2348810506 TP_BDC_FD_L_DHRL_FD_Byte0 5000;
BA_ "NetworkRequest" SG_ 2348810506 TP_BDC_FD_L_DHRL_FD_Byte0 0;
BA_ "UserSigValidity" SG_ 2348810506 TP_BDC_FD_L_DHRL_FD_Byte0 0;
BA_ "UsrSigPurpose" SG_ 2348810506 TP_BDC_FD_L_DHRL_FD_Byte0 9;
BA_ "Description" SG_ 2348810506 TP_BDC_FD_L_DHRL_FD_Byte0 "TP Index : 275";
BA_ "Version" SG_ 2348810506 TP_BDC_FD_L_DHRL_FD_Byte13 "23.06.01";
BA_ "NetworkRequestHoldingTime" SG_ 2348810506 TP_BDC_FD_L_DHRL_FD_Byte13 5000;
BA_ "NetworkRequest" SG_ 2348810506 TP_BDC_FD_L_DHRL_FD_Byte13 0;
BA_ "UserSigValidity" SG_ 2348810506 TP_BDC_FD_L_DHRL_FD_Byte13 0;
BA_ "UsrSigPurpose" SG_ 2348810506 TP_BDC_FD_L_DHRL_FD_Byte13 9;
BA_ "Description" SG_ 2348810506 TP_BDC_FD_L_DHRL_FD_Byte13 "TP Index : 275";
BA_ "Version" SG_ 2348810506 TP_BDC_FD_L_DHRL_FD_Byte14 "23.06.01";
BA_ "NetworkRequestHoldingTime" SG_ 2348810506 TP_BDC_FD_L_DHRL_FD_Byte14 5000;
BA_ "NetworkRequest" SG_ 2348810506 TP_BDC_FD_L_DHRL_FD_Byte14 0;
BA_ "UserSigValidity" SG_ 2348810506 TP_BDC_FD_L_DHRL_FD_Byte14 0;
BA_ "UsrSigPurpose" SG_ 2348810506 TP_BDC_FD_L_DHRL_FD_Byte14 9;
BA_ "Description" SG_ 2348810506 TP_BDC_FD_L_DHRL_FD_Byte14 "TP Index : 275";
BA_ "Version" SG_ 2348810506 TP_BDC_FD_L_DHRL_FD_Byte15 "23.06.01";
BA_ "NetworkRequestHoldingTime" SG_ 2348810506 TP_BDC_FD_L_DHRL_FD_Byte15 5000;
BA_ "NetworkRequest" SG_ 2348810506 TP_BDC_FD_L_DHRL_FD_Byte15 0;
BA_ "UserSigValidity" SG_ 2348810506 TP_BDC_FD_L_DHRL_FD_Byte15 0;
BA_ "UsrSigPurpose" SG_ 2348810506 TP_BDC_FD_L_DHRL_FD_Byte15 9;
BA_ "Description" SG_ 2348810506 TP_BDC_FD_L_DHRL_FD_Byte15 "TP Index : 275";
BA_ "Version" SG_ 2348810506 TP_BDC_FD_L_DHRL_FD_Byte16 "23.06.01";
BA_ "NetworkRequestHoldingTime" SG_ 2348810506 TP_BDC_FD_L_DHRL_FD_Byte16 5000;
BA_ "NetworkRequest" SG_ 2348810506 TP_BDC_FD_L_DHRL_FD_Byte16 0;
BA_ "UserSigValidity" SG_ 2348810506 TP_BDC_FD_L_DHRL_FD_Byte16 0;
BA_ "UsrSigPurpose" SG_ 2348810506 TP_BDC_FD_L_DHRL_FD_Byte16 9;
BA_ "Description" SG_ 2348810506 TP_BDC_FD_L_DHRL_FD_Byte16 "TP Index : 275";
BA_ "Version" SG_ 2348810506 TP_BDC_FD_L_DHRL_FD_Byte17 "23.06.01";
BA_ "NetworkRequestHoldingTime" SG_ 2348810506 TP_BDC_FD_L_DHRL_FD_Byte17 5000;
BA_ "NetworkRequest" SG_ 2348810506 TP_BDC_FD_L_DHRL_FD_Byte17 0;
BA_ "UserSigValidity" SG_ 2348810506 TP_BDC_FD_L_DHRL_FD_Byte17 0;
BA_ "UsrSigPurpose" SG_ 2348810506 TP_BDC_FD_L_DHRL_FD_Byte17 9;
BA_ "Description" SG_ 2348810506 TP_BDC_FD_L_DHRL_FD_Byte17 "TP Index : 275";
BA_ "Version" SG_ 2348810506 TP_BDC_FD_L_DHRL_FD_Byte18 "23.06.01";
BA_ "NetworkRequestHoldingTime" SG_ 2348810506 TP_BDC_FD_L_DHRL_FD_Byte18 5000;
BA_ "NetworkRequest" SG_ 2348810506 TP_BDC_FD_L_DHRL_FD_Byte18 0;
BA_ "UserSigValidity" SG_ 2348810506 TP_BDC_FD_L_DHRL_FD_Byte18 0;
BA_ "UsrSigPurpose" SG_ 2348810506 TP_BDC_FD_L_DHRL_FD_Byte18 9;
BA_ "Description" SG_ 2348810506 TP_BDC_FD_L_DHRL_FD_Byte18 "TP Index : 275";
BA_ "Version" SG_ 2348810506 TP_BDC_FD_L_DHRL_FD_Byte19 "23.06.01";
BA_ "NetworkRequestHoldingTime" SG_ 2348810506 TP_BDC_FD_L_DHRL_FD_Byte19 5000;
BA_ "NetworkRequest" SG_ 2348810506 TP_BDC_FD_L_DHRL_FD_Byte19 0;
BA_ "UserSigValidity" SG_ 2348810506 TP_BDC_FD_L_DHRL_FD_Byte19 0;
BA_ "UsrSigPurpose" SG_ 2348810506 TP_BDC_FD_L_DHRL_FD_Byte19 9;
BA_ "Description" SG_ 2348810506 TP_BDC_FD_L_DHRL_FD_Byte19 "TP Index : 275";
BA_ "Version" SG_ 2348810506 TP_BDC_FD_L_DHRL_FD_Byte2 "23.06.01";
BA_ "NetworkRequestHoldingTime" SG_ 2348810506 TP_BDC_FD_L_DHRL_FD_Byte2 5000;
BA_ "NetworkRequest" SG_ 2348810506 TP_BDC_FD_L_DHRL_FD_Byte2 0;
BA_ "UserSigValidity" SG_ 2348810506 TP_BDC_FD_L_DHRL_FD_Byte2 0;
BA_ "UsrSigPurpose" SG_ 2348810506 TP_BDC_FD_L_DHRL_FD_Byte2 9;
BA_ "Description" SG_ 2348810506 TP_BDC_FD_L_DHRL_FD_Byte2 "TP Index : 275";
BA_ "Version" SG_ 2348810506 TP_BDC_FD_L_DHRL_FD_Byte20 "23.06.01";
BA_ "NetworkRequestHoldingTime" SG_ 2348810506 TP_BDC_FD_L_DHRL_FD_Byte20 5000;
BA_ "NetworkRequest" SG_ 2348810506 TP_BDC_FD_L_DHRL_FD_Byte20 0;
BA_ "UserSigValidity" SG_ 2348810506 TP_BDC_FD_L_DHRL_FD_Byte20 0;
BA_ "UsrSigPurpose" SG_ 2348810506 TP_BDC_FD_L_DHRL_FD_Byte20 9;
BA_ "Description" SG_ 2348810506 TP_BDC_FD_L_DHRL_FD_Byte20 "TP Index : 275";
BA_ "Version" SG_ 2348810506 TP_BDC_FD_L_DHRL_FD_Byte21 "23.06.01";
BA_ "NetworkRequestHoldingTime" SG_ 2348810506 TP_BDC_FD_L_DHRL_FD_Byte21 5000;
BA_ "NetworkRequest" SG_ 2348810506 TP_BDC_FD_L_DHRL_FD_Byte21 0;
BA_ "UserSigValidity" SG_ 2348810506 TP_BDC_FD_L_DHRL_FD_Byte21 0;
BA_ "UsrSigPurpose" SG_ 2348810506 TP_BDC_FD_L_DHRL_FD_Byte21 9;
BA_ "Description" SG_ 2348810506 TP_BDC_FD_L_DHRL_FD_Byte21 "TP Index : 275";
BA_ "Version" SG_ 2348810506 TP_BDC_FD_L_DHRL_FD_Byte22 "23.06.01";
BA_ "NetworkRequestHoldingTime" SG_ 2348810506 TP_BDC_FD_L_DHRL_FD_Byte22 5000;
BA_ "NetworkRequest" SG_ 2348810506 TP_BDC_FD_L_DHRL_FD_Byte22 0;
BA_ "UserSigValidity" SG_ 2348810506 TP_BDC_FD_L_DHRL_FD_Byte22 0;
BA_ "UsrSigPurpose" SG_ 2348810506 TP_BDC_FD_L_DHRL_FD_Byte22 9;
BA_ "Description" SG_ 2348810506 TP_BDC_FD_L_DHRL_FD_Byte22 "TP Index : 275";
BA_ "Version" SG_ 2348810506 TP_BDC_FD_L_DHRL_FD_Byte23 "23.06.01";
BA_ "NetworkRequestHoldingTime" SG_ 2348810506 TP_BDC_FD_L_DHRL_FD_Byte23 5000;
BA_ "NetworkRequest" SG_ 2348810506 TP_BDC_FD_L_DHRL_FD_Byte23 0;
BA_ "UserSigValidity" SG_ 2348810506 TP_BDC_FD_L_DHRL_FD_Byte23 0;
BA_ "UsrSigPurpose" SG_ 2348810506 TP_BDC_FD_L_DHRL_FD_Byte23 9;
BA_ "Description" SG_ 2348810506 TP_BDC_FD_L_DHRL_FD_Byte23 "TP Index : 275";
BA_ "Version" SG_ 2348810506 TP_BDC_FD_L_DHRL_FD_Byte24 "23.06.01";
BA_ "NetworkRequestHoldingTime" SG_ 2348810506 TP_BDC_FD_L_DHRL_FD_Byte24 5000;
BA_ "NetworkRequest" SG_ 2348810506 TP_BDC_FD_L_DHRL_FD_Byte24 0;
BA_ "UserSigValidity" SG_ 2348810506 TP_BDC_FD_L_DHRL_FD_Byte24 0;
BA_ "UsrSigPurpose" SG_ 2348810506 TP_BDC_FD_L_DHRL_FD_Byte24 9;
BA_ "Description" SG_ 2348810506 TP_BDC_FD_L_DHRL_FD_Byte24 "TP Index : 275";
BA_ "Version" SG_ 2348810506 TP_BDC_FD_L_DHRL_FD_Byte25 "23.06.01";
BA_ "NetworkRequestHoldingTime" SG_ 2348810506 TP_BDC_FD_L_DHRL_FD_Byte25 5000;
BA_ "NetworkRequest" SG_ 2348810506 TP_BDC_FD_L_DHRL_FD_Byte25 0;
BA_ "UserSigValidity" SG_ 2348810506 TP_BDC_FD_L_DHRL_FD_Byte25 0;
BA_ "UsrSigPurpose" SG_ 2348810506 TP_BDC_FD_L_DHRL_FD_Byte25 9;
BA_ "Description" SG_ 2348810506 TP_BDC_FD_L_DHRL_FD_Byte25 "TP Index : 275";
BA_ "Version" SG_ 2348810506 TP_BDC_FD_L_DHRL_FD_Byte26 "23.06.01";
BA_ "NetworkRequestHoldingTime" SG_ 2348810506 TP_BDC_FD_L_DHRL_FD_Byte26 5000;
BA_ "NetworkRequest" SG_ 2348810506 TP_BDC_FD_L_DHRL_FD_Byte26 0;
BA_ "UserSigValidity" SG_ 2348810506 TP_BDC_FD_L_DHRL_FD_Byte26 0;
BA_ "UsrSigPurpose" SG_ 2348810506 TP_BDC_FD_L_DHRL_FD_Byte26 9;
BA_ "Description" SG_ 2348810506 TP_BDC_FD_L_DHRL_FD_Byte26 "TP Index : 275";
BA_ "Version" SG_ 2348810506 TP_BDC_FD_L_DHRL_FD_Byte27 "23.06.01";
BA_ "NetworkRequestHoldingTime" SG_ 2348810506 TP_BDC_FD_L_DHRL_FD_Byte27 5000;
BA_ "NetworkRequest" SG_ 2348810506 TP_BDC_FD_L_DHRL_FD_Byte27 0;
BA_ "UserSigValidity" SG_ 2348810506 TP_BDC_FD_L_DHRL_FD_Byte27 0;
BA_ "UsrSigPurpose" SG_ 2348810506 TP_BDC_FD_L_DHRL_FD_Byte27 9;
BA_ "Description" SG_ 2348810506 TP_BDC_FD_L_DHRL_FD_Byte27 "TP Index : 275";
BA_ "Version" SG_ 2348810506 TP_BDC_FD_L_DHRL_FD_Byte28 "23.06.01";
BA_ "NetworkRequestHoldingTime" SG_ 2348810506 TP_BDC_FD_L_DHRL_FD_Byte28 5000;
BA_ "NetworkRequest" SG_ 2348810506 TP_BDC_FD_L_DHRL_FD_Byte28 0;
BA_ "UserSigValidity" SG_ 2348810506 TP_BDC_FD_L_DHRL_FD_Byte28 0;
BA_ "UsrSigPurpose" SG_ 2348810506 TP_BDC_FD_L_DHRL_FD_Byte28 9;
BA_ "Description" SG_ 2348810506 TP_BDC_FD_L_DHRL_FD_Byte28 "TP Index : 275";
BA_ "Version" SG_ 2348810506 TP_BDC_FD_L_DHRL_FD_Byte29 "23.06.01";
BA_ "NetworkRequestHoldingTime" SG_ 2348810506 TP_BDC_FD_L_DHRL_FD_Byte29 5000;
BA_ "NetworkRequest" SG_ 2348810506 TP_BDC_FD_L_DHRL_FD_Byte29 0;
BA_ "UserSigValidity" SG_ 2348810506 TP_BDC_FD_L_DHRL_FD_Byte29 0;
BA_ "UsrSigPurpose" SG_ 2348810506 TP_BDC_FD_L_DHRL_FD_Byte29 9;
BA_ "Description" SG_ 2348810506 TP_BDC_FD_L_DHRL_FD_Byte29 "TP Index : 275";
BA_ "Version" SG_ 2348810506 TP_BDC_FD_L_DHRL_FD_Byte3 "23.06.01";
BA_ "NetworkRequestHoldingTime" SG_ 2348810506 TP_BDC_FD_L_DHRL_FD_Byte3 5000;
BA_ "NetworkRequest" SG_ 2348810506 TP_BDC_FD_L_DHRL_FD_Byte3 0;
BA_ "UserSigValidity" SG_ 2348810506 TP_BDC_FD_L_DHRL_FD_Byte3 0;
BA_ "UsrSigPurpose" SG_ 2348810506 TP_BDC_FD_L_DHRL_FD_Byte3 9;
BA_ "Description" SG_ 2348810506 TP_BDC_FD_L_DHRL_FD_Byte3 "TP Index : 275";
BA_ "Version" SG_ 2348810506 TP_BDC_FD_L_DHRL_FD_Byte30 "23.06.01";
BA_ "NetworkRequestHoldingTime" SG_ 2348810506 TP_BDC_FD_L_DHRL_FD_Byte30 5000;
BA_ "NetworkRequest" SG_ 2348810506 TP_BDC_FD_L_DHRL_FD_Byte30 0;
BA_ "UserSigValidity" SG_ 2348810506 TP_BDC_FD_L_DHRL_FD_Byte30 0;
BA_ "UsrSigPurpose" SG_ 2348810506 TP_BDC_FD_L_DHRL_FD_Byte30 9;
BA_ "Description" SG_ 2348810506 TP_BDC_FD_L_DHRL_FD_Byte30 "TP Index : 275";
BA_ "Version" SG_ 2348810506 TP_BDC_FD_L_DHRL_FD_Byte31 "23.06.01";
BA_ "NetworkRequestHoldingTime" SG_ 2348810506 TP_BDC_FD_L_DHRL_FD_Byte31 5000;
BA_ "NetworkRequest" SG_ 2348810506 TP_BDC_FD_L_DHRL_FD_Byte31 0;
BA_ "UserSigValidity" SG_ 2348810506 TP_BDC_FD_L_DHRL_FD_Byte31 0;
BA_ "UsrSigPurpose" SG_ 2348810506 TP_BDC_FD_L_DHRL_FD_Byte31 9;
BA_ "Description" SG_ 2348810506 TP_BDC_FD_L_DHRL_FD_Byte31 "TP Index : 275";
BA_ "Version" SG_ 2348810506 TP_BDC_FD_L_DHRL_FD_Byte4 "23.06.01";
BA_ "NetworkRequestHoldingTime" SG_ 2348810506 TP_BDC_FD_L_DHRL_FD_Byte4 5000;
BA_ "NetworkRequest" SG_ 2348810506 TP_BDC_FD_L_DHRL_FD_Byte4 0;
BA_ "UserSigValidity" SG_ 2348810506 TP_BDC_FD_L_DHRL_FD_Byte4 0;
BA_ "UsrSigPurpose" SG_ 2348810506 TP_BDC_FD_L_DHRL_FD_Byte4 9;
BA_ "Description" SG_ 2348810506 TP_BDC_FD_L_DHRL_FD_Byte4 "TP Index : 275";
BA_ "Version" SG_ 2348810506 TP_BDC_FD_L_DHRL_FD_Byte5 "23.06.01";
BA_ "NetworkRequestHoldingTime" SG_ 2348810506 TP_BDC_FD_L_DHRL_FD_Byte5 5000;
BA_ "NetworkRequest" SG_ 2348810506 TP_BDC_FD_L_DHRL_FD_Byte5 0;
BA_ "UserSigValidity" SG_ 2348810506 TP_BDC_FD_L_DHRL_FD_Byte5 0;
BA_ "UsrSigPurpose" SG_ 2348810506 TP_BDC_FD_L_DHRL_FD_Byte5 9;
BA_ "Description" SG_ 2348810506 TP_BDC_FD_L_DHRL_FD_Byte5 "TP Index : 275";
BA_ "Version" SG_ 2348810506 TP_BDC_FD_L_DHRL_FD_Byte6 "23.06.01";
BA_ "NetworkRequestHoldingTime" SG_ 2348810506 TP_BDC_FD_L_DHRL_FD_Byte6 5000;
BA_ "NetworkRequest" SG_ 2348810506 TP_BDC_FD_L_DHRL_FD_Byte6 0;
BA_ "UserSigValidity" SG_ 2348810506 TP_BDC_FD_L_DHRL_FD_Byte6 0;
BA_ "UsrSigPurpose" SG_ 2348810506 TP_BDC_FD_L_DHRL_FD_Byte6 9;
BA_ "Description" SG_ 2348810506 TP_BDC_FD_L_DHRL_FD_Byte6 "TP Index : 275";
BA_ "Version" SG_ 2348810506 TP_BDC_FD_L_DHRL_FD_Byte7 "23.06.01";
BA_ "NetworkRequestHoldingTime" SG_ 2348810506 TP_BDC_FD_L_DHRL_FD_Byte7 5000;
BA_ "NetworkRequest" SG_ 2348810506 TP_BDC_FD_L_DHRL_FD_Byte7 0;
BA_ "UserSigValidity" SG_ 2348810506 TP_BDC_FD_L_DHRL_FD_Byte7 0;
BA_ "UsrSigPurpose" SG_ 2348810506 TP_BDC_FD_L_DHRL_FD_Byte7 9;
BA_ "Description" SG_ 2348810506 TP_BDC_FD_L_DHRL_FD_Byte7 "TP Index : 275";
BA_ "Version" SG_ 2348810506 TP_BDC_FD_L_DHRL_FD_Byte8 "23.06.01";
BA_ "NetworkRequestHoldingTime" SG_ 2348810506 TP_BDC_FD_L_DHRL_FD_Byte8 5000;
BA_ "NetworkRequest" SG_ 2348810506 TP_BDC_FD_L_DHRL_FD_Byte8 0;
BA_ "UserSigValidity" SG_ 2348810506 TP_BDC_FD_L_DHRL_FD_Byte8 0;
BA_ "UsrSigPurpose" SG_ 2348810506 TP_BDC_FD_L_DHRL_FD_Byte8 9;
BA_ "Description" SG_ 2348810506 TP_BDC_FD_L_DHRL_FD_Byte8 "TP Index : 275";
BA_ "Version" SG_ 2348810506 TP_BDC_FD_L_DHRL_FD_Byte9 "23.06.01";
BA_ "NetworkRequestHoldingTime" SG_ 2348810506 TP_BDC_FD_L_DHRL_FD_Byte9 5000;
BA_ "NetworkRequest" SG_ 2348810506 TP_BDC_FD_L_DHRL_FD_Byte9 0;
BA_ "UserSigValidity" SG_ 2348810506 TP_BDC_FD_L_DHRL_FD_Byte9 0;
BA_ "UsrSigPurpose" SG_ 2348810506 TP_BDC_FD_L_DHRL_FD_Byte9 9;
BA_ "Description" SG_ 2348810506 TP_BDC_FD_L_DHRL_FD_Byte9 "TP Index : 275";
BA_ "Version" SG_ 2348810506 TP_BDC_FD_L_DHRL_FD_Byte1 "23.06.01";
BA_ "NetworkRequestHoldingTime" SG_ 2348810506 TP_BDC_FD_L_DHRL_FD_Byte1 5000;
BA_ "NetworkRequest" SG_ 2348810506 TP_BDC_FD_L_DHRL_FD_Byte1 0;
BA_ "UserSigValidity" SG_ 2348810506 TP_BDC_FD_L_DHRL_FD_Byte1 0;
BA_ "UsrSigPurpose" SG_ 2348810506 TP_BDC_FD_L_DHRL_FD_Byte1 9;
BA_ "Description" SG_ 2348810506 TP_BDC_FD_L_DHRL_FD_Byte1 "TP Index : 275";
BA_ "Version" SG_ 2348810506 TP_BDC_FD_L_DHRL_FD_Byte10 "23.06.01";
BA_ "NetworkRequestHoldingTime" SG_ 2348810506 TP_BDC_FD_L_DHRL_FD_Byte10 5000;
BA_ "NetworkRequest" SG_ 2348810506 TP_BDC_FD_L_DHRL_FD_Byte10 0;
BA_ "UserSigValidity" SG_ 2348810506 TP_BDC_FD_L_DHRL_FD_Byte10 0;
BA_ "UsrSigPurpose" SG_ 2348810506 TP_BDC_FD_L_DHRL_FD_Byte10 9;
BA_ "Description" SG_ 2348810506 TP_BDC_FD_L_DHRL_FD_Byte10 "TP Index : 275";
BA_ "Version" SG_ 2348810506 TP_BDC_FD_L_DHRL_FD_Byte11 "23.06.01";
BA_ "NetworkRequestHoldingTime" SG_ 2348810506 TP_BDC_FD_L_DHRL_FD_Byte11 5000;
BA_ "NetworkRequest" SG_ 2348810506 TP_BDC_FD_L_DHRL_FD_Byte11 0;
BA_ "UserSigValidity" SG_ 2348810506 TP_BDC_FD_L_DHRL_FD_Byte11 0;
BA_ "UsrSigPurpose" SG_ 2348810506 TP_BDC_FD_L_DHRL_FD_Byte11 9;
BA_ "Description" SG_ 2348810506 TP_BDC_FD_L_DHRL_FD_Byte11 "TP Index : 275";
BA_ "Version" SG_ 2348810506 TP_BDC_FD_L_DHRL_FD_Byte12 "23.06.01";
BA_ "NetworkRequestHoldingTime" SG_ 2348810506 TP_BDC_FD_L_DHRL_FD_Byte12 5000;
BA_ "NetworkRequest" SG_ 2348810506 TP_BDC_FD_L_DHRL_FD_Byte12 0;
BA_ "UserSigValidity" SG_ 2348810506 TP_BDC_FD_L_DHRL_FD_Byte12 0;
BA_ "UsrSigPurpose" SG_ 2348810506 TP_BDC_FD_L_DHRL_FD_Byte12 9;
BA_ "Description" SG_ 2348810506 TP_BDC_FD_L_DHRL_FD_Byte12 "TP Index : 275";
BA_ "Version" SG_ 2348810505 L_TP_L_DHR_FD_BDC_FD_Byte0 "23.01.02";
BA_ "NetworkRequestHoldingTime" SG_ 2348810505 L_TP_L_DHR_FD_BDC_FD_Byte0 5000;
BA_ "NetworkRequest" SG_ 2348810505 L_TP_L_DHR_FD_BDC_FD_Byte0 0;
BA_ "UserSigValidity" SG_ 2348810505 L_TP_L_DHR_FD_BDC_FD_Byte0 0;
BA_ "UsrSigPurpose" SG_ 2348810505 L_TP_L_DHR_FD_BDC_FD_Byte0 9;
BA_ "Description" SG_ 2348810505 L_TP_L_DHR_FD_BDC_FD_Byte0 "TP Index : 274";
BA_ "Version" SG_ 2348810505 L_TP_L_DHR_FD_BDC_FD_Byte13 "23.01.02";
BA_ "NetworkRequestHoldingTime" SG_ 2348810505 L_TP_L_DHR_FD_BDC_FD_Byte13 5000;
BA_ "NetworkRequest" SG_ 2348810505 L_TP_L_DHR_FD_BDC_FD_Byte13 0;
BA_ "UserSigValidity" SG_ 2348810505 L_TP_L_DHR_FD_BDC_FD_Byte13 0;
BA_ "UsrSigPurpose" SG_ 2348810505 L_TP_L_DHR_FD_BDC_FD_Byte13 9;
BA_ "Description" SG_ 2348810505 L_TP_L_DHR_FD_BDC_FD_Byte13 "TP Index : 274";
BA_ "Version" SG_ 2348810505 L_TP_L_DHR_FD_BDC_FD_Byte14 "23.01.02";
BA_ "NetworkRequestHoldingTime" SG_ 2348810505 L_TP_L_DHR_FD_BDC_FD_Byte14 5000;
BA_ "NetworkRequest" SG_ 2348810505 L_TP_L_DHR_FD_BDC_FD_Byte14 0;
BA_ "UserSigValidity" SG_ 2348810505 L_TP_L_DHR_FD_BDC_FD_Byte14 0;
BA_ "UsrSigPurpose" SG_ 2348810505 L_TP_L_DHR_FD_BDC_FD_Byte14 9;
BA_ "Description" SG_ 2348810505 L_TP_L_DHR_FD_BDC_FD_Byte14 "TP Index : 274";
BA_ "Version" SG_ 2348810505 L_TP_L_DHR_FD_BDC_FD_Byte15 "23.01.02";
BA_ "NetworkRequestHoldingTime" SG_ 2348810505 L_TP_L_DHR_FD_BDC_FD_Byte15 5000;
BA_ "NetworkRequest" SG_ 2348810505 L_TP_L_DHR_FD_BDC_FD_Byte15 0;
BA_ "UserSigValidity" SG_ 2348810505 L_TP_L_DHR_FD_BDC_FD_Byte15 0;
BA_ "UsrSigPurpose" SG_ 2348810505 L_TP_L_DHR_FD_BDC_FD_Byte15 9;
BA_ "Description" SG_ 2348810505 L_TP_L_DHR_FD_BDC_FD_Byte15 "TP Index : 274";
BA_ "Version" SG_ 2348810505 L_TP_L_DHR_FD_BDC_FD_Byte16 "23.01.02";
BA_ "NetworkRequestHoldingTime" SG_ 2348810505 L_TP_L_DHR_FD_BDC_FD_Byte16 5000;
BA_ "NetworkRequest" SG_ 2348810505 L_TP_L_DHR_FD_BDC_FD_Byte16 0;
BA_ "UserSigValidity" SG_ 2348810505 L_TP_L_DHR_FD_BDC_FD_Byte16 0;
BA_ "UsrSigPurpose" SG_ 2348810505 L_TP_L_DHR_FD_BDC_FD_Byte16 9;
BA_ "Description" SG_ 2348810505 L_TP_L_DHR_FD_BDC_FD_Byte16 "TP Index : 274";
BA_ "Version" SG_ 2348810505 L_TP_L_DHR_FD_BDC_FD_Byte17 "23.01.02";
BA_ "NetworkRequestHoldingTime" SG_ 2348810505 L_TP_L_DHR_FD_BDC_FD_Byte17 5000;
BA_ "NetworkRequest" SG_ 2348810505 L_TP_L_DHR_FD_BDC_FD_Byte17 0;
BA_ "UserSigValidity" SG_ 2348810505 L_TP_L_DHR_FD_BDC_FD_Byte17 0;
BA_ "UsrSigPurpose" SG_ 2348810505 L_TP_L_DHR_FD_BDC_FD_Byte17 9;
BA_ "Description" SG_ 2348810505 L_TP_L_DHR_FD_BDC_FD_Byte17 "TP Index : 274";
BA_ "Version" SG_ 2348810505 L_TP_L_DHR_FD_BDC_FD_Byte18 "23.01.02";
BA_ "NetworkRequestHoldingTime" SG_ 2348810505 L_TP_L_DHR_FD_BDC_FD_Byte18 5000;
BA_ "NetworkRequest" SG_ 2348810505 L_TP_L_DHR_FD_BDC_FD_Byte18 0;
BA_ "UserSigValidity" SG_ 2348810505 L_TP_L_DHR_FD_BDC_FD_Byte18 0;
BA_ "UsrSigPurpose" SG_ 2348810505 L_TP_L_DHR_FD_BDC_FD_Byte18 9;
BA_ "Description" SG_ 2348810505 L_TP_L_DHR_FD_BDC_FD_Byte18 "TP Index : 274";
BA_ "Version" SG_ 2348810505 L_TP_L_DHR_FD_BDC_FD_Byte19 "23.01.02";
BA_ "NetworkRequestHoldingTime" SG_ 2348810505 L_TP_L_DHR_FD_BDC_FD_Byte19 5000;
BA_ "NetworkRequest" SG_ 2348810505 L_TP_L_DHR_FD_BDC_FD_Byte19 0;
BA_ "UserSigValidity" SG_ 2348810505 L_TP_L_DHR_FD_BDC_FD_Byte19 0;
BA_ "UsrSigPurpose" SG_ 2348810505 L_TP_L_DHR_FD_BDC_FD_Byte19 9;
BA_ "Description" SG_ 2348810505 L_TP_L_DHR_FD_BDC_FD_Byte19 "TP Index : 274";
BA_ "Version" SG_ 2348810505 L_TP_L_DHR_FD_BDC_FD_Byte2 "23.01.02";
BA_ "NetworkRequestHoldingTime" SG_ 2348810505 L_TP_L_DHR_FD_BDC_FD_Byte2 5000;
BA_ "NetworkRequest" SG_ 2348810505 L_TP_L_DHR_FD_BDC_FD_Byte2 0;
BA_ "UserSigValidity" SG_ 2348810505 L_TP_L_DHR_FD_BDC_FD_Byte2 0;
BA_ "UsrSigPurpose" SG_ 2348810505 L_TP_L_DHR_FD_BDC_FD_Byte2 9;
BA_ "Description" SG_ 2348810505 L_TP_L_DHR_FD_BDC_FD_Byte2 "TP Index : 274";
BA_ "Version" SG_ 2348810505 L_TP_L_DHR_FD_BDC_FD_Byte20 "23.01.02";
BA_ "NetworkRequestHoldingTime" SG_ 2348810505 L_TP_L_DHR_FD_BDC_FD_Byte20 5000;
BA_ "NetworkRequest" SG_ 2348810505 L_TP_L_DHR_FD_BDC_FD_Byte20 0;
BA_ "UserSigValidity" SG_ 2348810505 L_TP_L_DHR_FD_BDC_FD_Byte20 0;
BA_ "UsrSigPurpose" SG_ 2348810505 L_TP_L_DHR_FD_BDC_FD_Byte20 9;
BA_ "Description" SG_ 2348810505 L_TP_L_DHR_FD_BDC_FD_Byte20 "TP Index : 274";
BA_ "Version" SG_ 2348810505 L_TP_L_DHR_FD_BDC_FD_Byte21 "23.01.02";
BA_ "NetworkRequestHoldingTime" SG_ 2348810505 L_TP_L_DHR_FD_BDC_FD_Byte21 5000;
BA_ "NetworkRequest" SG_ 2348810505 L_TP_L_DHR_FD_BDC_FD_Byte21 0;
BA_ "UserSigValidity" SG_ 2348810505 L_TP_L_DHR_FD_BDC_FD_Byte21 0;
BA_ "UsrSigPurpose" SG_ 2348810505 L_TP_L_DHR_FD_BDC_FD_Byte21 9;
BA_ "Description" SG_ 2348810505 L_TP_L_DHR_FD_BDC_FD_Byte21 "TP Index : 274";
BA_ "Version" SG_ 2348810505 L_TP_L_DHR_FD_BDC_FD_Byte22 "23.01.02";
BA_ "NetworkRequestHoldingTime" SG_ 2348810505 L_TP_L_DHR_FD_BDC_FD_Byte22 5000;
BA_ "NetworkRequest" SG_ 2348810505 L_TP_L_DHR_FD_BDC_FD_Byte22 0;
BA_ "UserSigValidity" SG_ 2348810505 L_TP_L_DHR_FD_BDC_FD_Byte22 0;
BA_ "UsrSigPurpose" SG_ 2348810505 L_TP_L_DHR_FD_BDC_FD_Byte22 9;
BA_ "Description" SG_ 2348810505 L_TP_L_DHR_FD_BDC_FD_Byte22 "TP Index : 274";
BA_ "Version" SG_ 2348810505 L_TP_L_DHR_FD_BDC_FD_Byte23 "23.01.02";
BA_ "NetworkRequestHoldingTime" SG_ 2348810505 L_TP_L_DHR_FD_BDC_FD_Byte23 5000;
BA_ "NetworkRequest" SG_ 2348810505 L_TP_L_DHR_FD_BDC_FD_Byte23 0;
BA_ "UserSigValidity" SG_ 2348810505 L_TP_L_DHR_FD_BDC_FD_Byte23 0;
BA_ "UsrSigPurpose" SG_ 2348810505 L_TP_L_DHR_FD_BDC_FD_Byte23 9;
BA_ "Description" SG_ 2348810505 L_TP_L_DHR_FD_BDC_FD_Byte23 "TP Index : 274";
BA_ "Version" SG_ 2348810505 L_TP_L_DHR_FD_BDC_FD_Byte24 "23.01.02";
BA_ "NetworkRequestHoldingTime" SG_ 2348810505 L_TP_L_DHR_FD_BDC_FD_Byte24 5000;
BA_ "NetworkRequest" SG_ 2348810505 L_TP_L_DHR_FD_BDC_FD_Byte24 0;
BA_ "UserSigValidity" SG_ 2348810505 L_TP_L_DHR_FD_BDC_FD_Byte24 0;
BA_ "UsrSigPurpose" SG_ 2348810505 L_TP_L_DHR_FD_BDC_FD_Byte24 9;
BA_ "Description" SG_ 2348810505 L_TP_L_DHR_FD_BDC_FD_Byte24 "TP Index : 274";
BA_ "Version" SG_ 2348810505 L_TP_L_DHR_FD_BDC_FD_Byte25 "23.01.02";
BA_ "NetworkRequestHoldingTime" SG_ 2348810505 L_TP_L_DHR_FD_BDC_FD_Byte25 5000;
BA_ "NetworkRequest" SG_ 2348810505 L_TP_L_DHR_FD_BDC_FD_Byte25 0;
BA_ "UserSigValidity" SG_ 2348810505 L_TP_L_DHR_FD_BDC_FD_Byte25 0;
BA_ "UsrSigPurpose" SG_ 2348810505 L_TP_L_DHR_FD_BDC_FD_Byte25 9;
BA_ "Description" SG_ 2348810505 L_TP_L_DHR_FD_BDC_FD_Byte25 "TP Index : 274";
BA_ "Version" SG_ 2348810505 L_TP_L_DHR_FD_BDC_FD_Byte26 "23.01.02";
BA_ "NetworkRequestHoldingTime" SG_ 2348810505 L_TP_L_DHR_FD_BDC_FD_Byte26 5000;
BA_ "NetworkRequest" SG_ 2348810505 L_TP_L_DHR_FD_BDC_FD_Byte26 0;
BA_ "UserSigValidity" SG_ 2348810505 L_TP_L_DHR_FD_BDC_FD_Byte26 0;
BA_ "UsrSigPurpose" SG_ 2348810505 L_TP_L_DHR_FD_BDC_FD_Byte26 9;
BA_ "Description" SG_ 2348810505 L_TP_L_DHR_FD_BDC_FD_Byte26 "TP Index : 274";
BA_ "Version" SG_ 2348810505 L_TP_L_DHR_FD_BDC_FD_Byte27 "23.01.02";
BA_ "NetworkRequestHoldingTime" SG_ 2348810505 L_TP_L_DHR_FD_BDC_FD_Byte27 5000;
BA_ "NetworkRequest" SG_ 2348810505 L_TP_L_DHR_FD_BDC_FD_Byte27 0;
BA_ "UserSigValidity" SG_ 2348810505 L_TP_L_DHR_FD_BDC_FD_Byte27 0;
BA_ "UsrSigPurpose" SG_ 2348810505 L_TP_L_DHR_FD_BDC_FD_Byte27 9;
BA_ "Description" SG_ 2348810505 L_TP_L_DHR_FD_BDC_FD_Byte27 "TP Index : 274";
BA_ "Version" SG_ 2348810505 L_TP_L_DHR_FD_BDC_FD_Byte28 "23.01.02";
BA_ "NetworkRequestHoldingTime" SG_ 2348810505 L_TP_L_DHR_FD_BDC_FD_Byte28 5000;
BA_ "NetworkRequest" SG_ 2348810505 L_TP_L_DHR_FD_BDC_FD_Byte28 0;
BA_ "UserSigValidity" SG_ 2348810505 L_TP_L_DHR_FD_BDC_FD_Byte28 0;
BA_ "UsrSigPurpose" SG_ 2348810505 L_TP_L_DHR_FD_BDC_FD_Byte28 9;
BA_ "Description" SG_ 2348810505 L_TP_L_DHR_FD_BDC_FD_Byte28 "TP Index : 274";
BA_ "Version" SG_ 2348810505 L_TP_L_DHR_FD_BDC_FD_Byte29 "23.01.02";
BA_ "NetworkRequestHoldingTime" SG_ 2348810505 L_TP_L_DHR_FD_BDC_FD_Byte29 5000;
BA_ "NetworkRequest" SG_ 2348810505 L_TP_L_DHR_FD_BDC_FD_Byte29 0;
BA_ "UserSigValidity" SG_ 2348810505 L_TP_L_DHR_FD_BDC_FD_Byte29 0;
BA_ "UsrSigPurpose" SG_ 2348810505 L_TP_L_DHR_FD_BDC_FD_Byte29 9;
BA_ "Description" SG_ 2348810505 L_TP_L_DHR_FD_BDC_FD_Byte29 "TP Index : 274";
BA_ "Version" SG_ 2348810505 L_TP_L_DHR_FD_BDC_FD_Byte3 "23.01.02";
BA_ "NetworkRequestHoldingTime" SG_ 2348810505 L_TP_L_DHR_FD_BDC_FD_Byte3 5000;
BA_ "NetworkRequest" SG_ 2348810505 L_TP_L_DHR_FD_BDC_FD_Byte3 0;
BA_ "UserSigValidity" SG_ 2348810505 L_TP_L_DHR_FD_BDC_FD_Byte3 0;
BA_ "UsrSigPurpose" SG_ 2348810505 L_TP_L_DHR_FD_BDC_FD_Byte3 9;
BA_ "Description" SG_ 2348810505 L_TP_L_DHR_FD_BDC_FD_Byte3 "TP Index : 274";
BA_ "Version" SG_ 2348810505 L_TP_L_DHR_FD_BDC_FD_Byte30 "23.01.02";
BA_ "NetworkRequestHoldingTime" SG_ 2348810505 L_TP_L_DHR_FD_BDC_FD_Byte30 5000;
BA_ "NetworkRequest" SG_ 2348810505 L_TP_L_DHR_FD_BDC_FD_Byte30 0;
BA_ "UserSigValidity" SG_ 2348810505 L_TP_L_DHR_FD_BDC_FD_Byte30 0;
BA_ "UsrSigPurpose" SG_ 2348810505 L_TP_L_DHR_FD_BDC_FD_Byte30 9;
BA_ "Description" SG_ 2348810505 L_TP_L_DHR_FD_BDC_FD_Byte30 "TP Index : 274";
BA_ "Version" SG_ 2348810505 L_TP_L_DHR_FD_BDC_FD_Byte31 "23.01.02";
BA_ "NetworkRequestHoldingTime" SG_ 2348810505 L_TP_L_DHR_FD_BDC_FD_Byte31 5000;
BA_ "NetworkRequest" SG_ 2348810505 L_TP_L_DHR_FD_BDC_FD_Byte31 0;
BA_ "UserSigValidity" SG_ 2348810505 L_TP_L_DHR_FD_BDC_FD_Byte31 0;
BA_ "UsrSigPurpose" SG_ 2348810505 L_TP_L_DHR_FD_BDC_FD_Byte31 9;
BA_ "Description" SG_ 2348810505 L_TP_L_DHR_FD_BDC_FD_Byte31 "TP Index : 274";
BA_ "Version" SG_ 2348810505 L_TP_L_DHR_FD_BDC_FD_Byte4 "23.01.02";
BA_ "NetworkRequestHoldingTime" SG_ 2348810505 L_TP_L_DHR_FD_BDC_FD_Byte4 5000;
BA_ "NetworkRequest" SG_ 2348810505 L_TP_L_DHR_FD_BDC_FD_Byte4 0;
BA_ "UserSigValidity" SG_ 2348810505 L_TP_L_DHR_FD_BDC_FD_Byte4 0;
BA_ "UsrSigPurpose" SG_ 2348810505 L_TP_L_DHR_FD_BDC_FD_Byte4 9;
BA_ "Description" SG_ 2348810505 L_TP_L_DHR_FD_BDC_FD_Byte4 "TP Index : 274";
BA_ "Version" SG_ 2348810505 L_TP_L_DHR_FD_BDC_FD_Byte5 "23.01.02";
BA_ "NetworkRequestHoldingTime" SG_ 2348810505 L_TP_L_DHR_FD_BDC_FD_Byte5 5000;
BA_ "NetworkRequest" SG_ 2348810505 L_TP_L_DHR_FD_BDC_FD_Byte5 0;
BA_ "UserSigValidity" SG_ 2348810505 L_TP_L_DHR_FD_BDC_FD_Byte5 0;
BA_ "UsrSigPurpose" SG_ 2348810505 L_TP_L_DHR_FD_BDC_FD_Byte5 9;
BA_ "Description" SG_ 2348810505 L_TP_L_DHR_FD_BDC_FD_Byte5 "TP Index : 274";
BA_ "Version" SG_ 2348810505 L_TP_L_DHR_FD_BDC_FD_Byte6 "23.01.02";
BA_ "NetworkRequestHoldingTime" SG_ 2348810505 L_TP_L_DHR_FD_BDC_FD_Byte6 5000;
BA_ "NetworkRequest" SG_ 2348810505 L_TP_L_DHR_FD_BDC_FD_Byte6 0;
BA_ "UserSigValidity" SG_ 2348810505 L_TP_L_DHR_FD_BDC_FD_Byte6 0;
BA_ "UsrSigPurpose" SG_ 2348810505 L_TP_L_DHR_FD_BDC_FD_Byte6 9;
BA_ "Description" SG_ 2348810505 L_TP_L_DHR_FD_BDC_FD_Byte6 "TP Index : 274";
BA_ "Version" SG_ 2348810505 L_TP_L_DHR_FD_BDC_FD_Byte7 "23.01.02";
BA_ "NetworkRequestHoldingTime" SG_ 2348810505 L_TP_L_DHR_FD_BDC_FD_Byte7 5000;
BA_ "NetworkRequest" SG_ 2348810505 L_TP_L_DHR_FD_BDC_FD_Byte7 0;
BA_ "UserSigValidity" SG_ 2348810505 L_TP_L_DHR_FD_BDC_FD_Byte7 0;
BA_ "UsrSigPurpose" SG_ 2348810505 L_TP_L_DHR_FD_BDC_FD_Byte7 9;
BA_ "Description" SG_ 2348810505 L_TP_L_DHR_FD_BDC_FD_Byte7 "TP Index : 274";
BA_ "Version" SG_ 2348810505 L_TP_L_DHR_FD_BDC_FD_Byte8 "23.01.02";
BA_ "NetworkRequestHoldingTime" SG_ 2348810505 L_TP_L_DHR_FD_BDC_FD_Byte8 5000;
BA_ "NetworkRequest" SG_ 2348810505 L_TP_L_DHR_FD_BDC_FD_Byte8 0;
BA_ "UserSigValidity" SG_ 2348810505 L_TP_L_DHR_FD_BDC_FD_Byte8 0;
BA_ "UsrSigPurpose" SG_ 2348810505 L_TP_L_DHR_FD_BDC_FD_Byte8 9;
BA_ "Description" SG_ 2348810505 L_TP_L_DHR_FD_BDC_FD_Byte8 "TP Index : 274";
BA_ "Version" SG_ 2348810505 L_TP_L_DHR_FD_BDC_FD_Byte9 "23.01.02";
BA_ "NetworkRequestHoldingTime" SG_ 2348810505 L_TP_L_DHR_FD_BDC_FD_Byte9 5000;
BA_ "NetworkRequest" SG_ 2348810505 L_TP_L_DHR_FD_BDC_FD_Byte9 0;
BA_ "UserSigValidity" SG_ 2348810505 L_TP_L_DHR_FD_BDC_FD_Byte9 0;
BA_ "UsrSigPurpose" SG_ 2348810505 L_TP_L_DHR_FD_BDC_FD_Byte9 9;
BA_ "Description" SG_ 2348810505 L_TP_L_DHR_FD_BDC_FD_Byte9 "TP Index : 274";
BA_ "Version" SG_ 2348810505 L_TP_L_DHR_FD_BDC_FD_Byte1 "23.01.02";
BA_ "NetworkRequestHoldingTime" SG_ 2348810505 L_TP_L_DHR_FD_BDC_FD_Byte1 5000;
BA_ "NetworkRequest" SG_ 2348810505 L_TP_L_DHR_FD_BDC_FD_Byte1 0;
BA_ "UserSigValidity" SG_ 2348810505 L_TP_L_DHR_FD_BDC_FD_Byte1 0;
BA_ "UsrSigPurpose" SG_ 2348810505 L_TP_L_DHR_FD_BDC_FD_Byte1 9;
BA_ "Description" SG_ 2348810505 L_TP_L_DHR_FD_BDC_FD_Byte1 "TP Index : 274";
BA_ "Version" SG_ 2348810505 L_TP_L_DHR_FD_BDC_FD_Byte10 "23.01.02";
BA_ "NetworkRequestHoldingTime" SG_ 2348810505 L_TP_L_DHR_FD_BDC_FD_Byte10 5000;
BA_ "NetworkRequest" SG_ 2348810505 L_TP_L_DHR_FD_BDC_FD_Byte10 0;
BA_ "UserSigValidity" SG_ 2348810505 L_TP_L_DHR_FD_BDC_FD_Byte10 0;
BA_ "UsrSigPurpose" SG_ 2348810505 L_TP_L_DHR_FD_BDC_FD_Byte10 9;
BA_ "Description" SG_ 2348810505 L_TP_L_DHR_FD_BDC_FD_Byte10 "TP Index : 274";
BA_ "Version" SG_ 2348810505 L_TP_L_DHR_FD_BDC_FD_Byte11 "23.01.02";
BA_ "NetworkRequestHoldingTime" SG_ 2348810505 L_TP_L_DHR_FD_BDC_FD_Byte11 5000;
BA_ "NetworkRequest" SG_ 2348810505 L_TP_L_DHR_FD_BDC_FD_Byte11 0;
BA_ "UserSigValidity" SG_ 2348810505 L_TP_L_DHR_FD_BDC_FD_Byte11 0;
BA_ "UsrSigPurpose" SG_ 2348810505 L_TP_L_DHR_FD_BDC_FD_Byte11 9;
BA_ "Description" SG_ 2348810505 L_TP_L_DHR_FD_BDC_FD_Byte11 "TP Index : 274";
BA_ "Version" SG_ 2348810505 L_TP_L_DHR_FD_BDC_FD_Byte12 "23.01.02";
BA_ "NetworkRequestHoldingTime" SG_ 2348810505 L_TP_L_DHR_FD_BDC_FD_Byte12 5000;
BA_ "NetworkRequest" SG_ 2348810505 L_TP_L_DHR_FD_BDC_FD_Byte12 0;
BA_ "UserSigValidity" SG_ 2348810505 L_TP_L_DHR_FD_BDC_FD_Byte12 0;
BA_ "UsrSigPurpose" SG_ 2348810505 L_TP_L_DHR_FD_BDC_FD_Byte12 9;
BA_ "Description" SG_ 2348810505 L_TP_L_DHR_FD_BDC_FD_Byte12 "TP Index : 274";
BA_ "Version" SG_ 2348810504 L_TP_BDC_FD_L_DHR_FD_Byte0 "23.01.02";
BA_ "NetworkRequestHoldingTime" SG_ 2348810504 L_TP_BDC_FD_L_DHR_FD_Byte0 5000;
BA_ "NetworkRequest" SG_ 2348810504 L_TP_BDC_FD_L_DHR_FD_Byte0 0;
BA_ "UserSigValidity" SG_ 2348810504 L_TP_BDC_FD_L_DHR_FD_Byte0 0;
BA_ "UsrSigPurpose" SG_ 2348810504 L_TP_BDC_FD_L_DHR_FD_Byte0 9;
BA_ "Description" SG_ 2348810504 L_TP_BDC_FD_L_DHR_FD_Byte0 "TP Index : 274";
BA_ "Version" SG_ 2348810504 L_TP_BDC_FD_L_DHR_FD_Byte13 "23.01.02";
BA_ "NetworkRequestHoldingTime" SG_ 2348810504 L_TP_BDC_FD_L_DHR_FD_Byte13 5000;
BA_ "NetworkRequest" SG_ 2348810504 L_TP_BDC_FD_L_DHR_FD_Byte13 0;
BA_ "UserSigValidity" SG_ 2348810504 L_TP_BDC_FD_L_DHR_FD_Byte13 0;
BA_ "UsrSigPurpose" SG_ 2348810504 L_TP_BDC_FD_L_DHR_FD_Byte13 9;
BA_ "Description" SG_ 2348810504 L_TP_BDC_FD_L_DHR_FD_Byte13 "TP Index : 274";
BA_ "Version" SG_ 2348810504 L_TP_BDC_FD_L_DHR_FD_Byte14 "23.01.02";
BA_ "NetworkRequestHoldingTime" SG_ 2348810504 L_TP_BDC_FD_L_DHR_FD_Byte14 5000;
BA_ "NetworkRequest" SG_ 2348810504 L_TP_BDC_FD_L_DHR_FD_Byte14 0;
BA_ "UserSigValidity" SG_ 2348810504 L_TP_BDC_FD_L_DHR_FD_Byte14 0;
BA_ "UsrSigPurpose" SG_ 2348810504 L_TP_BDC_FD_L_DHR_FD_Byte14 9;
BA_ "Description" SG_ 2348810504 L_TP_BDC_FD_L_DHR_FD_Byte14 "TP Index : 274";
BA_ "Version" SG_ 2348810504 L_TP_BDC_FD_L_DHR_FD_Byte15 "23.01.02";
BA_ "NetworkRequestHoldingTime" SG_ 2348810504 L_TP_BDC_FD_L_DHR_FD_Byte15 5000;
BA_ "NetworkRequest" SG_ 2348810504 L_TP_BDC_FD_L_DHR_FD_Byte15 0;
BA_ "UserSigValidity" SG_ 2348810504 L_TP_BDC_FD_L_DHR_FD_Byte15 0;
BA_ "UsrSigPurpose" SG_ 2348810504 L_TP_BDC_FD_L_DHR_FD_Byte15 9;
BA_ "Description" SG_ 2348810504 L_TP_BDC_FD_L_DHR_FD_Byte15 "TP Index : 274";
BA_ "Version" SG_ 2348810504 L_TP_BDC_FD_L_DHR_FD_Byte16 "23.01.02";
BA_ "NetworkRequestHoldingTime" SG_ 2348810504 L_TP_BDC_FD_L_DHR_FD_Byte16 5000;
BA_ "NetworkRequest" SG_ 2348810504 L_TP_BDC_FD_L_DHR_FD_Byte16 0;
BA_ "UserSigValidity" SG_ 2348810504 L_TP_BDC_FD_L_DHR_FD_Byte16 0;
BA_ "UsrSigPurpose" SG_ 2348810504 L_TP_BDC_FD_L_DHR_FD_Byte16 9;
BA_ "Description" SG_ 2348810504 L_TP_BDC_FD_L_DHR_FD_Byte16 "TP Index : 274";
BA_ "Version" SG_ 2348810504 L_TP_BDC_FD_L_DHR_FD_Byte17 "23.01.02";
BA_ "NetworkRequestHoldingTime" SG_ 2348810504 L_TP_BDC_FD_L_DHR_FD_Byte17 5000;
BA_ "NetworkRequest" SG_ 2348810504 L_TP_BDC_FD_L_DHR_FD_Byte17 0;
BA_ "UserSigValidity" SG_ 2348810504 L_TP_BDC_FD_L_DHR_FD_Byte17 0;
BA_ "UsrSigPurpose" SG_ 2348810504 L_TP_BDC_FD_L_DHR_FD_Byte17 9;
BA_ "Description" SG_ 2348810504 L_TP_BDC_FD_L_DHR_FD_Byte17 "TP Index : 274";
BA_ "Version" SG_ 2348810504 L_TP_BDC_FD_L_DHR_FD_Byte18 "23.01.02";
BA_ "NetworkRequestHoldingTime" SG_ 2348810504 L_TP_BDC_FD_L_DHR_FD_Byte18 5000;
BA_ "NetworkRequest" SG_ 2348810504 L_TP_BDC_FD_L_DHR_FD_Byte18 0;
BA_ "UserSigValidity" SG_ 2348810504 L_TP_BDC_FD_L_DHR_FD_Byte18 0;
BA_ "UsrSigPurpose" SG_ 2348810504 L_TP_BDC_FD_L_DHR_FD_Byte18 9;
BA_ "Description" SG_ 2348810504 L_TP_BDC_FD_L_DHR_FD_Byte18 "TP Index : 274";
BA_ "Version" SG_ 2348810504 L_TP_BDC_FD_L_DHR_FD_Byte19 "23.01.02";
BA_ "NetworkRequestHoldingTime" SG_ 2348810504 L_TP_BDC_FD_L_DHR_FD_Byte19 5000;
BA_ "NetworkRequest" SG_ 2348810504 L_TP_BDC_FD_L_DHR_FD_Byte19 0;
BA_ "UserSigValidity" SG_ 2348810504 L_TP_BDC_FD_L_DHR_FD_Byte19 0;
BA_ "UsrSigPurpose" SG_ 2348810504 L_TP_BDC_FD_L_DHR_FD_Byte19 9;
BA_ "Description" SG_ 2348810504 L_TP_BDC_FD_L_DHR_FD_Byte19 "TP Index : 274";
BA_ "Version" SG_ 2348810504 L_TP_BDC_FD_L_DHR_FD_Byte2 "23.01.02";
BA_ "NetworkRequestHoldingTime" SG_ 2348810504 L_TP_BDC_FD_L_DHR_FD_Byte2 5000;
BA_ "NetworkRequest" SG_ 2348810504 L_TP_BDC_FD_L_DHR_FD_Byte2 0;
BA_ "UserSigValidity" SG_ 2348810504 L_TP_BDC_FD_L_DHR_FD_Byte2 0;
BA_ "UsrSigPurpose" SG_ 2348810504 L_TP_BDC_FD_L_DHR_FD_Byte2 9;
BA_ "Description" SG_ 2348810504 L_TP_BDC_FD_L_DHR_FD_Byte2 "TP Index : 274";
BA_ "Version" SG_ 2348810504 L_TP_BDC_FD_L_DHR_FD_Byte20 "23.01.02";
BA_ "NetworkRequestHoldingTime" SG_ 2348810504 L_TP_BDC_FD_L_DHR_FD_Byte20 5000;
BA_ "NetworkRequest" SG_ 2348810504 L_TP_BDC_FD_L_DHR_FD_Byte20 0;
BA_ "UserSigValidity" SG_ 2348810504 L_TP_BDC_FD_L_DHR_FD_Byte20 0;
BA_ "UsrSigPurpose" SG_ 2348810504 L_TP_BDC_FD_L_DHR_FD_Byte20 9;
BA_ "Description" SG_ 2348810504 L_TP_BDC_FD_L_DHR_FD_Byte20 "TP Index : 274";
BA_ "Version" SG_ 2348810504 L_TP_BDC_FD_L_DHR_FD_Byte21 "23.01.02";
BA_ "NetworkRequestHoldingTime" SG_ 2348810504 L_TP_BDC_FD_L_DHR_FD_Byte21 5000;
BA_ "NetworkRequest" SG_ 2348810504 L_TP_BDC_FD_L_DHR_FD_Byte21 0;
BA_ "UserSigValidity" SG_ 2348810504 L_TP_BDC_FD_L_DHR_FD_Byte21 0;
BA_ "UsrSigPurpose" SG_ 2348810504 L_TP_BDC_FD_L_DHR_FD_Byte21 9;
BA_ "Description" SG_ 2348810504 L_TP_BDC_FD_L_DHR_FD_Byte21 "TP Index : 274";
BA_ "Version" SG_ 2348810504 L_TP_BDC_FD_L_DHR_FD_Byte22 "23.01.02";
BA_ "NetworkRequestHoldingTime" SG_ 2348810504 L_TP_BDC_FD_L_DHR_FD_Byte22 5000;
BA_ "NetworkRequest" SG_ 2348810504 L_TP_BDC_FD_L_DHR_FD_Byte22 0;
BA_ "UserSigValidity" SG_ 2348810504 L_TP_BDC_FD_L_DHR_FD_Byte22 0;
BA_ "UsrSigPurpose" SG_ 2348810504 L_TP_BDC_FD_L_DHR_FD_Byte22 9;
BA_ "Description" SG_ 2348810504 L_TP_BDC_FD_L_DHR_FD_Byte22 "TP Index : 274";
BA_ "Version" SG_ 2348810504 L_TP_BDC_FD_L_DHR_FD_Byte23 "23.01.02";
BA_ "NetworkRequestHoldingTime" SG_ 2348810504 L_TP_BDC_FD_L_DHR_FD_Byte23 5000;
BA_ "NetworkRequest" SG_ 2348810504 L_TP_BDC_FD_L_DHR_FD_Byte23 0;
BA_ "UserSigValidity" SG_ 2348810504 L_TP_BDC_FD_L_DHR_FD_Byte23 0;
BA_ "UsrSigPurpose" SG_ 2348810504 L_TP_BDC_FD_L_DHR_FD_Byte23 9;
BA_ "Description" SG_ 2348810504 L_TP_BDC_FD_L_DHR_FD_Byte23 "TP Index : 274";
BA_ "Version" SG_ 2348810504 L_TP_BDC_FD_L_DHR_FD_Byte24 "23.01.02";
BA_ "NetworkRequestHoldingTime" SG_ 2348810504 L_TP_BDC_FD_L_DHR_FD_Byte24 5000;
BA_ "NetworkRequest" SG_ 2348810504 L_TP_BDC_FD_L_DHR_FD_Byte24 0;
BA_ "UserSigValidity" SG_ 2348810504 L_TP_BDC_FD_L_DHR_FD_Byte24 0;
BA_ "UsrSigPurpose" SG_ 2348810504 L_TP_BDC_FD_L_DHR_FD_Byte24 9;
BA_ "Description" SG_ 2348810504 L_TP_BDC_FD_L_DHR_FD_Byte24 "TP Index : 274";
BA_ "Version" SG_ 2348810504 L_TP_BDC_FD_L_DHR_FD_Byte25 "23.01.02";
BA_ "NetworkRequestHoldingTime" SG_ 2348810504 L_TP_BDC_FD_L_DHR_FD_Byte25 5000;
BA_ "NetworkRequest" SG_ 2348810504 L_TP_BDC_FD_L_DHR_FD_Byte25 0;
BA_ "UserSigValidity" SG_ 2348810504 L_TP_BDC_FD_L_DHR_FD_Byte25 0;
BA_ "UsrSigPurpose" SG_ 2348810504 L_TP_BDC_FD_L_DHR_FD_Byte25 9;
BA_ "Description" SG_ 2348810504 L_TP_BDC_FD_L_DHR_FD_Byte25 "TP Index : 274";
BA_ "Version" SG_ 2348810504 L_TP_BDC_FD_L_DHR_FD_Byte26 "23.01.02";
BA_ "NetworkRequestHoldingTime" SG_ 2348810504 L_TP_BDC_FD_L_DHR_FD_Byte26 5000;
BA_ "NetworkRequest" SG_ 2348810504 L_TP_BDC_FD_L_DHR_FD_Byte26 0;
BA_ "UserSigValidity" SG_ 2348810504 L_TP_BDC_FD_L_DHR_FD_Byte26 0;
BA_ "UsrSigPurpose" SG_ 2348810504 L_TP_BDC_FD_L_DHR_FD_Byte26 9;
BA_ "Description" SG_ 2348810504 L_TP_BDC_FD_L_DHR_FD_Byte26 "TP Index : 274";
BA_ "Version" SG_ 2348810504 L_TP_BDC_FD_L_DHR_FD_Byte27 "23.01.02";
BA_ "NetworkRequestHoldingTime" SG_ 2348810504 L_TP_BDC_FD_L_DHR_FD_Byte27 5000;
BA_ "NetworkRequest" SG_ 2348810504 L_TP_BDC_FD_L_DHR_FD_Byte27 0;
BA_ "UserSigValidity" SG_ 2348810504 L_TP_BDC_FD_L_DHR_FD_Byte27 0;
BA_ "UsrSigPurpose" SG_ 2348810504 L_TP_BDC_FD_L_DHR_FD_Byte27 9;
BA_ "Description" SG_ 2348810504 L_TP_BDC_FD_L_DHR_FD_Byte27 "TP Index : 274";
BA_ "Version" SG_ 2348810504 L_TP_BDC_FD_L_DHR_FD_Byte28 "23.01.02";
BA_ "NetworkRequestHoldingTime" SG_ 2348810504 L_TP_BDC_FD_L_DHR_FD_Byte28 5000;
BA_ "NetworkRequest" SG_ 2348810504 L_TP_BDC_FD_L_DHR_FD_Byte28 0;
BA_ "UserSigValidity" SG_ 2348810504 L_TP_BDC_FD_L_DHR_FD_Byte28 0;
BA_ "UsrSigPurpose" SG_ 2348810504 L_TP_BDC_FD_L_DHR_FD_Byte28 9;
BA_ "Description" SG_ 2348810504 L_TP_BDC_FD_L_DHR_FD_Byte28 "TP Index : 274";
BA_ "Version" SG_ 2348810504 L_TP_BDC_FD_L_DHR_FD_Byte29 "23.01.02";
BA_ "NetworkRequestHoldingTime" SG_ 2348810504 L_TP_BDC_FD_L_DHR_FD_Byte29 5000;
BA_ "NetworkRequest" SG_ 2348810504 L_TP_BDC_FD_L_DHR_FD_Byte29 0;
BA_ "UserSigValidity" SG_ 2348810504 L_TP_BDC_FD_L_DHR_FD_Byte29 0;
BA_ "UsrSigPurpose" SG_ 2348810504 L_TP_BDC_FD_L_DHR_FD_Byte29 9;
BA_ "Description" SG_ 2348810504 L_TP_BDC_FD_L_DHR_FD_Byte29 "TP Index : 274";
BA_ "Version" SG_ 2348810504 L_TP_BDC_FD_L_DHR_FD_Byte3 "23.01.02";
BA_ "NetworkRequestHoldingTime" SG_ 2348810504 L_TP_BDC_FD_L_DHR_FD_Byte3 5000;
BA_ "NetworkRequest" SG_ 2348810504 L_TP_BDC_FD_L_DHR_FD_Byte3 0;
BA_ "UserSigValidity" SG_ 2348810504 L_TP_BDC_FD_L_DHR_FD_Byte3 0;
BA_ "UsrSigPurpose" SG_ 2348810504 L_TP_BDC_FD_L_DHR_FD_Byte3 9;
BA_ "Description" SG_ 2348810504 L_TP_BDC_FD_L_DHR_FD_Byte3 "TP Index : 274";
BA_ "Version" SG_ 2348810504 L_TP_BDC_FD_L_DHR_FD_Byte30 "23.01.02";
BA_ "NetworkRequestHoldingTime" SG_ 2348810504 L_TP_BDC_FD_L_DHR_FD_Byte30 5000;
BA_ "NetworkRequest" SG_ 2348810504 L_TP_BDC_FD_L_DHR_FD_Byte30 0;
BA_ "UserSigValidity" SG_ 2348810504 L_TP_BDC_FD_L_DHR_FD_Byte30 0;
BA_ "UsrSigPurpose" SG_ 2348810504 L_TP_BDC_FD_L_DHR_FD_Byte30 9;
BA_ "Description" SG_ 2348810504 L_TP_BDC_FD_L_DHR_FD_Byte30 "TP Index : 274";
BA_ "Version" SG_ 2348810504 L_TP_BDC_FD_L_DHR_FD_Byte31 "23.01.02";
BA_ "NetworkRequestHoldingTime" SG_ 2348810504 L_TP_BDC_FD_L_DHR_FD_Byte31 5000;
BA_ "NetworkRequest" SG_ 2348810504 L_TP_BDC_FD_L_DHR_FD_Byte31 0;
BA_ "UserSigValidity" SG_ 2348810504 L_TP_BDC_FD_L_DHR_FD_Byte31 0;
BA_ "UsrSigPurpose" SG_ 2348810504 L_TP_BDC_FD_L_DHR_FD_Byte31 9;
BA_ "Description" SG_ 2348810504 L_TP_BDC_FD_L_DHR_FD_Byte31 "TP Index : 274";
BA_ "Version" SG_ 2348810504 L_TP_BDC_FD_L_DHR_FD_Byte4 "23.01.02";
BA_ "NetworkRequestHoldingTime" SG_ 2348810504 L_TP_BDC_FD_L_DHR_FD_Byte4 5000;
BA_ "NetworkRequest" SG_ 2348810504 L_TP_BDC_FD_L_DHR_FD_Byte4 0;
BA_ "UserSigValidity" SG_ 2348810504 L_TP_BDC_FD_L_DHR_FD_Byte4 0;
BA_ "UsrSigPurpose" SG_ 2348810504 L_TP_BDC_FD_L_DHR_FD_Byte4 9;
BA_ "Description" SG_ 2348810504 L_TP_BDC_FD_L_DHR_FD_Byte4 "TP Index : 274";
BA_ "Version" SG_ 2348810504 L_TP_BDC_FD_L_DHR_FD_Byte5 "23.01.02";
BA_ "NetworkRequestHoldingTime" SG_ 2348810504 L_TP_BDC_FD_L_DHR_FD_Byte5 5000;
BA_ "NetworkRequest" SG_ 2348810504 L_TP_BDC_FD_L_DHR_FD_Byte5 0;
BA_ "UserSigValidity" SG_ 2348810504 L_TP_BDC_FD_L_DHR_FD_Byte5 0;
BA_ "UsrSigPurpose" SG_ 2348810504 L_TP_BDC_FD_L_DHR_FD_Byte5 9;
BA_ "Description" SG_ 2348810504 L_TP_BDC_FD_L_DHR_FD_Byte5 "TP Index : 274";
BA_ "Version" SG_ 2348810504 L_TP_BDC_FD_L_DHR_FD_Byte6 "23.01.02";
BA_ "NetworkRequestHoldingTime" SG_ 2348810504 L_TP_BDC_FD_L_DHR_FD_Byte6 5000;
BA_ "NetworkRequest" SG_ 2348810504 L_TP_BDC_FD_L_DHR_FD_Byte6 0;
BA_ "UserSigValidity" SG_ 2348810504 L_TP_BDC_FD_L_DHR_FD_Byte6 0;
BA_ "UsrSigPurpose" SG_ 2348810504 L_TP_BDC_FD_L_DHR_FD_Byte6 9;
BA_ "Description" SG_ 2348810504 L_TP_BDC_FD_L_DHR_FD_Byte6 "TP Index : 274";
BA_ "Version" SG_ 2348810504 L_TP_BDC_FD_L_DHR_FD_Byte7 "23.01.02";
BA_ "NetworkRequestHoldingTime" SG_ 2348810504 L_TP_BDC_FD_L_DHR_FD_Byte7 5000;
BA_ "NetworkRequest" SG_ 2348810504 L_TP_BDC_FD_L_DHR_FD_Byte7 0;
BA_ "UserSigValidity" SG_ 2348810504 L_TP_BDC_FD_L_DHR_FD_Byte7 0;
BA_ "UsrSigPurpose" SG_ 2348810504 L_TP_BDC_FD_L_DHR_FD_Byte7 9;
BA_ "Description" SG_ 2348810504 L_TP_BDC_FD_L_DHR_FD_Byte7 "TP Index : 274";
BA_ "Version" SG_ 2348810504 L_TP_BDC_FD_L_DHR_FD_Byte8 "23.01.02";
BA_ "NetworkRequestHoldingTime" SG_ 2348810504 L_TP_BDC_FD_L_DHR_FD_Byte8 5000;
BA_ "NetworkRequest" SG_ 2348810504 L_TP_BDC_FD_L_DHR_FD_Byte8 0;
BA_ "UserSigValidity" SG_ 2348810504 L_TP_BDC_FD_L_DHR_FD_Byte8 0;
BA_ "UsrSigPurpose" SG_ 2348810504 L_TP_BDC_FD_L_DHR_FD_Byte8 9;
BA_ "Description" SG_ 2348810504 L_TP_BDC_FD_L_DHR_FD_Byte8 "TP Index : 274";
BA_ "Version" SG_ 2348810504 L_TP_BDC_FD_L_DHR_FD_Byte9 "23.01.02";
BA_ "NetworkRequestHoldingTime" SG_ 2348810504 L_TP_BDC_FD_L_DHR_FD_Byte9 5000;
BA_ "NetworkRequest" SG_ 2348810504 L_TP_BDC_FD_L_DHR_FD_Byte9 0;
BA_ "UserSigValidity" SG_ 2348810504 L_TP_BDC_FD_L_DHR_FD_Byte9 0;
BA_ "UsrSigPurpose" SG_ 2348810504 L_TP_BDC_FD_L_DHR_FD_Byte9 9;
BA_ "Description" SG_ 2348810504 L_TP_BDC_FD_L_DHR_FD_Byte9 "TP Index : 274";
BA_ "Version" SG_ 2348810504 L_TP_BDC_FD_L_DHR_FD_Byte1 "23.01.02";
BA_ "NetworkRequestHoldingTime" SG_ 2348810504 L_TP_BDC_FD_L_DHR_FD_Byte1 5000;
BA_ "NetworkRequest" SG_ 2348810504 L_TP_BDC_FD_L_DHR_FD_Byte1 0;
BA_ "UserSigValidity" SG_ 2348810504 L_TP_BDC_FD_L_DHR_FD_Byte1 0;
BA_ "UsrSigPurpose" SG_ 2348810504 L_TP_BDC_FD_L_DHR_FD_Byte1 9;
BA_ "Description" SG_ 2348810504 L_TP_BDC_FD_L_DHR_FD_Byte1 "TP Index : 274";
BA_ "Version" SG_ 2348810504 L_TP_BDC_FD_L_DHR_FD_Byte10 "23.01.02";
BA_ "NetworkRequestHoldingTime" SG_ 2348810504 L_TP_BDC_FD_L_DHR_FD_Byte10 5000;
BA_ "NetworkRequest" SG_ 2348810504 L_TP_BDC_FD_L_DHR_FD_Byte10 0;
BA_ "UserSigValidity" SG_ 2348810504 L_TP_BDC_FD_L_DHR_FD_Byte10 0;
BA_ "UsrSigPurpose" SG_ 2348810504 L_TP_BDC_FD_L_DHR_FD_Byte10 9;
BA_ "Description" SG_ 2348810504 L_TP_BDC_FD_L_DHR_FD_Byte10 "TP Index : 274";
BA_ "Version" SG_ 2348810504 L_TP_BDC_FD_L_DHR_FD_Byte11 "23.01.02";
BA_ "NetworkRequestHoldingTime" SG_ 2348810504 L_TP_BDC_FD_L_DHR_FD_Byte11 5000;
BA_ "NetworkRequest" SG_ 2348810504 L_TP_BDC_FD_L_DHR_FD_Byte11 0;
BA_ "UserSigValidity" SG_ 2348810504 L_TP_BDC_FD_L_DHR_FD_Byte11 0;
BA_ "UsrSigPurpose" SG_ 2348810504 L_TP_BDC_FD_L_DHR_FD_Byte11 9;
BA_ "Description" SG_ 2348810504 L_TP_BDC_FD_L_DHR_FD_Byte11 "TP Index : 274";
BA_ "Version" SG_ 2348810504 L_TP_BDC_FD_L_DHR_FD_Byte12 "23.01.02";
BA_ "NetworkRequestHoldingTime" SG_ 2348810504 L_TP_BDC_FD_L_DHR_FD_Byte12 5000;
BA_ "NetworkRequest" SG_ 2348810504 L_TP_BDC_FD_L_DHR_FD_Byte12 0;
BA_ "UserSigValidity" SG_ 2348810504 L_TP_BDC_FD_L_DHR_FD_Byte12 0;
BA_ "UsrSigPurpose" SG_ 2348810504 L_TP_BDC_FD_L_DHR_FD_Byte12 9;
BA_ "Description" SG_ 2348810504 L_TP_BDC_FD_L_DHR_FD_Byte12 "TP Index : 274";
BA_ "Version" SG_ 2348810503 L_TP_L_DHL_FD_BDC_FD_Byte0 "23.01.02";
BA_ "NetworkRequestHoldingTime" SG_ 2348810503 L_TP_L_DHL_FD_BDC_FD_Byte0 5000;
BA_ "NetworkRequest" SG_ 2348810503 L_TP_L_DHL_FD_BDC_FD_Byte0 0;
BA_ "UserSigValidity" SG_ 2348810503 L_TP_L_DHL_FD_BDC_FD_Byte0 0;
BA_ "UsrSigPurpose" SG_ 2348810503 L_TP_L_DHL_FD_BDC_FD_Byte0 9;
BA_ "Description" SG_ 2348810503 L_TP_L_DHL_FD_BDC_FD_Byte0 "TP Index : 273";
BA_ "Version" SG_ 2348810503 L_TP_L_DHL_FD_BDC_FD_Byte13 "23.01.02";
BA_ "NetworkRequestHoldingTime" SG_ 2348810503 L_TP_L_DHL_FD_BDC_FD_Byte13 5000;
BA_ "NetworkRequest" SG_ 2348810503 L_TP_L_DHL_FD_BDC_FD_Byte13 0;
BA_ "UserSigValidity" SG_ 2348810503 L_TP_L_DHL_FD_BDC_FD_Byte13 0;
BA_ "UsrSigPurpose" SG_ 2348810503 L_TP_L_DHL_FD_BDC_FD_Byte13 9;
BA_ "Description" SG_ 2348810503 L_TP_L_DHL_FD_BDC_FD_Byte13 "TP Index : 273";
BA_ "Version" SG_ 2348810503 L_TP_L_DHL_FD_BDC_FD_Byte14 "23.01.02";
BA_ "NetworkRequestHoldingTime" SG_ 2348810503 L_TP_L_DHL_FD_BDC_FD_Byte14 5000;
BA_ "NetworkRequest" SG_ 2348810503 L_TP_L_DHL_FD_BDC_FD_Byte14 0;
BA_ "UserSigValidity" SG_ 2348810503 L_TP_L_DHL_FD_BDC_FD_Byte14 0;
BA_ "UsrSigPurpose" SG_ 2348810503 L_TP_L_DHL_FD_BDC_FD_Byte14 9;
BA_ "Description" SG_ 2348810503 L_TP_L_DHL_FD_BDC_FD_Byte14 "TP Index : 273";
BA_ "Version" SG_ 2348810503 L_TP_L_DHL_FD_BDC_FD_Byte15 "23.01.02";
BA_ "NetworkRequestHoldingTime" SG_ 2348810503 L_TP_L_DHL_FD_BDC_FD_Byte15 5000;
BA_ "NetworkRequest" SG_ 2348810503 L_TP_L_DHL_FD_BDC_FD_Byte15 0;
BA_ "UserSigValidity" SG_ 2348810503 L_TP_L_DHL_FD_BDC_FD_Byte15 0;
BA_ "UsrSigPurpose" SG_ 2348810503 L_TP_L_DHL_FD_BDC_FD_Byte15 9;
BA_ "Description" SG_ 2348810503 L_TP_L_DHL_FD_BDC_FD_Byte15 "TP Index : 273";
BA_ "Version" SG_ 2348810503 L_TP_L_DHL_FD_BDC_FD_Byte16 "23.01.02";
BA_ "NetworkRequestHoldingTime" SG_ 2348810503 L_TP_L_DHL_FD_BDC_FD_Byte16 5000;
BA_ "NetworkRequest" SG_ 2348810503 L_TP_L_DHL_FD_BDC_FD_Byte16 0;
BA_ "UserSigValidity" SG_ 2348810503 L_TP_L_DHL_FD_BDC_FD_Byte16 0;
BA_ "UsrSigPurpose" SG_ 2348810503 L_TP_L_DHL_FD_BDC_FD_Byte16 9;
BA_ "Description" SG_ 2348810503 L_TP_L_DHL_FD_BDC_FD_Byte16 "TP Index : 273";
BA_ "Version" SG_ 2348810503 L_TP_L_DHL_FD_BDC_FD_Byte17 "23.01.02";
BA_ "NetworkRequestHoldingTime" SG_ 2348810503 L_TP_L_DHL_FD_BDC_FD_Byte17 5000;
BA_ "NetworkRequest" SG_ 2348810503 L_TP_L_DHL_FD_BDC_FD_Byte17 0;
BA_ "UserSigValidity" SG_ 2348810503 L_TP_L_DHL_FD_BDC_FD_Byte17 0;
BA_ "UsrSigPurpose" SG_ 2348810503 L_TP_L_DHL_FD_BDC_FD_Byte17 9;
BA_ "Description" SG_ 2348810503 L_TP_L_DHL_FD_BDC_FD_Byte17 "TP Index : 273";
BA_ "Version" SG_ 2348810503 L_TP_L_DHL_FD_BDC_FD_Byte18 "23.01.02";
BA_ "NetworkRequestHoldingTime" SG_ 2348810503 L_TP_L_DHL_FD_BDC_FD_Byte18 5000;
BA_ "NetworkRequest" SG_ 2348810503 L_TP_L_DHL_FD_BDC_FD_Byte18 0;
BA_ "UserSigValidity" SG_ 2348810503 L_TP_L_DHL_FD_BDC_FD_Byte18 0;
BA_ "UsrSigPurpose" SG_ 2348810503 L_TP_L_DHL_FD_BDC_FD_Byte18 9;
BA_ "Description" SG_ 2348810503 L_TP_L_DHL_FD_BDC_FD_Byte18 "TP Index : 273";
BA_ "Version" SG_ 2348810503 L_TP_L_DHL_FD_BDC_FD_Byte19 "23.01.02";
BA_ "NetworkRequestHoldingTime" SG_ 2348810503 L_TP_L_DHL_FD_BDC_FD_Byte19 5000;
BA_ "NetworkRequest" SG_ 2348810503 L_TP_L_DHL_FD_BDC_FD_Byte19 0;
BA_ "UserSigValidity" SG_ 2348810503 L_TP_L_DHL_FD_BDC_FD_Byte19 0;
BA_ "UsrSigPurpose" SG_ 2348810503 L_TP_L_DHL_FD_BDC_FD_Byte19 9;
BA_ "Description" SG_ 2348810503 L_TP_L_DHL_FD_BDC_FD_Byte19 "TP Index : 273";
BA_ "Version" SG_ 2348810503 L_TP_L_DHL_FD_BDC_FD_Byte2 "23.01.02";
BA_ "NetworkRequestHoldingTime" SG_ 2348810503 L_TP_L_DHL_FD_BDC_FD_Byte2 5000;
BA_ "NetworkRequest" SG_ 2348810503 L_TP_L_DHL_FD_BDC_FD_Byte2 0;
BA_ "UserSigValidity" SG_ 2348810503 L_TP_L_DHL_FD_BDC_FD_Byte2 0;
BA_ "UsrSigPurpose" SG_ 2348810503 L_TP_L_DHL_FD_BDC_FD_Byte2 9;
BA_ "Description" SG_ 2348810503 L_TP_L_DHL_FD_BDC_FD_Byte2 "TP Index : 273";
BA_ "Version" SG_ 2348810503 L_TP_L_DHL_FD_BDC_FD_Byte20 "23.01.02";
BA_ "NetworkRequestHoldingTime" SG_ 2348810503 L_TP_L_DHL_FD_BDC_FD_Byte20 5000;
BA_ "NetworkRequest" SG_ 2348810503 L_TP_L_DHL_FD_BDC_FD_Byte20 0;
BA_ "UserSigValidity" SG_ 2348810503 L_TP_L_DHL_FD_BDC_FD_Byte20 0;
BA_ "UsrSigPurpose" SG_ 2348810503 L_TP_L_DHL_FD_BDC_FD_Byte20 9;
BA_ "Description" SG_ 2348810503 L_TP_L_DHL_FD_BDC_FD_Byte20 "TP Index : 273";
BA_ "Version" SG_ 2348810503 L_TP_L_DHL_FD_BDC_FD_Byte21 "23.01.02";
BA_ "NetworkRequestHoldingTime" SG_ 2348810503 L_TP_L_DHL_FD_BDC_FD_Byte21 5000;
BA_ "NetworkRequest" SG_ 2348810503 L_TP_L_DHL_FD_BDC_FD_Byte21 0;
BA_ "UserSigValidity" SG_ 2348810503 L_TP_L_DHL_FD_BDC_FD_Byte21 0;
BA_ "UsrSigPurpose" SG_ 2348810503 L_TP_L_DHL_FD_BDC_FD_Byte21 9;
BA_ "Description" SG_ 2348810503 L_TP_L_DHL_FD_BDC_FD_Byte21 "TP Index : 273";
BA_ "Version" SG_ 2348810503 L_TP_L_DHL_FD_BDC_FD_Byte22 "23.01.02";
BA_ "NetworkRequestHoldingTime" SG_ 2348810503 L_TP_L_DHL_FD_BDC_FD_Byte22 5000;
BA_ "NetworkRequest" SG_ 2348810503 L_TP_L_DHL_FD_BDC_FD_Byte22 0;
BA_ "UserSigValidity" SG_ 2348810503 L_TP_L_DHL_FD_BDC_FD_Byte22 0;
BA_ "UsrSigPurpose" SG_ 2348810503 L_TP_L_DHL_FD_BDC_FD_Byte22 9;
BA_ "Description" SG_ 2348810503 L_TP_L_DHL_FD_BDC_FD_Byte22 "TP Index : 273";
BA_ "Version" SG_ 2348810503 L_TP_L_DHL_FD_BDC_FD_Byte23 "23.01.02";
BA_ "NetworkRequestHoldingTime" SG_ 2348810503 L_TP_L_DHL_FD_BDC_FD_Byte23 5000;
BA_ "NetworkRequest" SG_ 2348810503 L_TP_L_DHL_FD_BDC_FD_Byte23 0;
BA_ "UserSigValidity" SG_ 2348810503 L_TP_L_DHL_FD_BDC_FD_Byte23 0;
BA_ "UsrSigPurpose" SG_ 2348810503 L_TP_L_DHL_FD_BDC_FD_Byte23 9;
BA_ "Description" SG_ 2348810503 L_TP_L_DHL_FD_BDC_FD_Byte23 "TP Index : 273";
BA_ "Version" SG_ 2348810503 L_TP_L_DHL_FD_BDC_FD_Byte24 "23.01.02";
BA_ "NetworkRequestHoldingTime" SG_ 2348810503 L_TP_L_DHL_FD_BDC_FD_Byte24 5000;
BA_ "NetworkRequest" SG_ 2348810503 L_TP_L_DHL_FD_BDC_FD_Byte24 0;
BA_ "UserSigValidity" SG_ 2348810503 L_TP_L_DHL_FD_BDC_FD_Byte24 0;
BA_ "UsrSigPurpose" SG_ 2348810503 L_TP_L_DHL_FD_BDC_FD_Byte24 9;
BA_ "Description" SG_ 2348810503 L_TP_L_DHL_FD_BDC_FD_Byte24 "TP Index : 273";
BA_ "Version" SG_ 2348810503 L_TP_L_DHL_FD_BDC_FD_Byte25 "23.01.02";
BA_ "NetworkRequestHoldingTime" SG_ 2348810503 L_TP_L_DHL_FD_BDC_FD_Byte25 5000;
BA_ "NetworkRequest" SG_ 2348810503 L_TP_L_DHL_FD_BDC_FD_Byte25 0;
BA_ "UserSigValidity" SG_ 2348810503 L_TP_L_DHL_FD_BDC_FD_Byte25 0;
BA_ "UsrSigPurpose" SG_ 2348810503 L_TP_L_DHL_FD_BDC_FD_Byte25 9;
BA_ "Description" SG_ 2348810503 L_TP_L_DHL_FD_BDC_FD_Byte25 "TP Index : 273";
BA_ "Version" SG_ 2348810503 L_TP_L_DHL_FD_BDC_FD_Byte26 "23.01.02";
BA_ "NetworkRequestHoldingTime" SG_ 2348810503 L_TP_L_DHL_FD_BDC_FD_Byte26 5000;
BA_ "NetworkRequest" SG_ 2348810503 L_TP_L_DHL_FD_BDC_FD_Byte26 0;
BA_ "UserSigValidity" SG_ 2348810503 L_TP_L_DHL_FD_BDC_FD_Byte26 0;
BA_ "UsrSigPurpose" SG_ 2348810503 L_TP_L_DHL_FD_BDC_FD_Byte26 9;
BA_ "Description" SG_ 2348810503 L_TP_L_DHL_FD_BDC_FD_Byte26 "TP Index : 273";
BA_ "Version" SG_ 2348810503 L_TP_L_DHL_FD_BDC_FD_Byte27 "23.01.02";
BA_ "NetworkRequestHoldingTime" SG_ 2348810503 L_TP_L_DHL_FD_BDC_FD_Byte27 5000;
BA_ "NetworkRequest" SG_ 2348810503 L_TP_L_DHL_FD_BDC_FD_Byte27 0;
BA_ "UserSigValidity" SG_ 2348810503 L_TP_L_DHL_FD_BDC_FD_Byte27 0;
BA_ "UsrSigPurpose" SG_ 2348810503 L_TP_L_DHL_FD_BDC_FD_Byte27 9;
BA_ "Description" SG_ 2348810503 L_TP_L_DHL_FD_BDC_FD_Byte27 "TP Index : 273";
BA_ "Version" SG_ 2348810503 L_TP_L_DHL_FD_BDC_FD_Byte28 "23.01.02";
BA_ "NetworkRequestHoldingTime" SG_ 2348810503 L_TP_L_DHL_FD_BDC_FD_Byte28 5000;
BA_ "NetworkRequest" SG_ 2348810503 L_TP_L_DHL_FD_BDC_FD_Byte28 0;
BA_ "UserSigValidity" SG_ 2348810503 L_TP_L_DHL_FD_BDC_FD_Byte28 0;
BA_ "UsrSigPurpose" SG_ 2348810503 L_TP_L_DHL_FD_BDC_FD_Byte28 9;
BA_ "Description" SG_ 2348810503 L_TP_L_DHL_FD_BDC_FD_Byte28 "TP Index : 273";
BA_ "Version" SG_ 2348810503 L_TP_L_DHL_FD_BDC_FD_Byte29 "23.01.02";
BA_ "NetworkRequestHoldingTime" SG_ 2348810503 L_TP_L_DHL_FD_BDC_FD_Byte29 5000;
BA_ "NetworkRequest" SG_ 2348810503 L_TP_L_DHL_FD_BDC_FD_Byte29 0;
BA_ "UserSigValidity" SG_ 2348810503 L_TP_L_DHL_FD_BDC_FD_Byte29 0;
BA_ "UsrSigPurpose" SG_ 2348810503 L_TP_L_DHL_FD_BDC_FD_Byte29 9;
BA_ "Description" SG_ 2348810503 L_TP_L_DHL_FD_BDC_FD_Byte29 "TP Index : 273";
BA_ "Version" SG_ 2348810503 L_TP_L_DHL_FD_BDC_FD_Byte3 "23.01.02";
BA_ "NetworkRequestHoldingTime" SG_ 2348810503 L_TP_L_DHL_FD_BDC_FD_Byte3 5000;
BA_ "NetworkRequest" SG_ 2348810503 L_TP_L_DHL_FD_BDC_FD_Byte3 0;
BA_ "UserSigValidity" SG_ 2348810503 L_TP_L_DHL_FD_BDC_FD_Byte3 0;
BA_ "UsrSigPurpose" SG_ 2348810503 L_TP_L_DHL_FD_BDC_FD_Byte3 9;
BA_ "Description" SG_ 2348810503 L_TP_L_DHL_FD_BDC_FD_Byte3 "TP Index : 273";
BA_ "Version" SG_ 2348810503 L_TP_L_DHL_FD_BDC_FD_Byte30 "23.01.02";
BA_ "NetworkRequestHoldingTime" SG_ 2348810503 L_TP_L_DHL_FD_BDC_FD_Byte30 5000;
BA_ "NetworkRequest" SG_ 2348810503 L_TP_L_DHL_FD_BDC_FD_Byte30 0;
BA_ "UserSigValidity" SG_ 2348810503 L_TP_L_DHL_FD_BDC_FD_Byte30 0;
BA_ "UsrSigPurpose" SG_ 2348810503 L_TP_L_DHL_FD_BDC_FD_Byte30 9;
BA_ "Description" SG_ 2348810503 L_TP_L_DHL_FD_BDC_FD_Byte30 "TP Index : 273";
BA_ "Version" SG_ 2348810503 L_TP_L_DHL_FD_BDC_FD_Byte31 "23.01.02";
BA_ "NetworkRequestHoldingTime" SG_ 2348810503 L_TP_L_DHL_FD_BDC_FD_Byte31 5000;
BA_ "NetworkRequest" SG_ 2348810503 L_TP_L_DHL_FD_BDC_FD_Byte31 0;
BA_ "UserSigValidity" SG_ 2348810503 L_TP_L_DHL_FD_BDC_FD_Byte31 0;
BA_ "UsrSigPurpose" SG_ 2348810503 L_TP_L_DHL_FD_BDC_FD_Byte31 9;
BA_ "Description" SG_ 2348810503 L_TP_L_DHL_FD_BDC_FD_Byte31 "TP Index : 273";
BA_ "Version" SG_ 2348810503 L_TP_L_DHL_FD_BDC_FD_Byte4 "23.01.02";
BA_ "NetworkRequestHoldingTime" SG_ 2348810503 L_TP_L_DHL_FD_BDC_FD_Byte4 5000;
BA_ "NetworkRequest" SG_ 2348810503 L_TP_L_DHL_FD_BDC_FD_Byte4 0;
BA_ "UserSigValidity" SG_ 2348810503 L_TP_L_DHL_FD_BDC_FD_Byte4 0;
BA_ "UsrSigPurpose" SG_ 2348810503 L_TP_L_DHL_FD_BDC_FD_Byte4 9;
BA_ "Description" SG_ 2348810503 L_TP_L_DHL_FD_BDC_FD_Byte4 "TP Index : 273";
BA_ "Version" SG_ 2348810503 L_TP_L_DHL_FD_BDC_FD_Byte5 "23.01.02";
BA_ "NetworkRequestHoldingTime" SG_ 2348810503 L_TP_L_DHL_FD_BDC_FD_Byte5 5000;
BA_ "NetworkRequest" SG_ 2348810503 L_TP_L_DHL_FD_BDC_FD_Byte5 0;
BA_ "UserSigValidity" SG_ 2348810503 L_TP_L_DHL_FD_BDC_FD_Byte5 0;
BA_ "UsrSigPurpose" SG_ 2348810503 L_TP_L_DHL_FD_BDC_FD_Byte5 9;
BA_ "Description" SG_ 2348810503 L_TP_L_DHL_FD_BDC_FD_Byte5 "TP Index : 273";
BA_ "Version" SG_ 2348810503 L_TP_L_DHL_FD_BDC_FD_Byte6 "23.01.02";
BA_ "NetworkRequestHoldingTime" SG_ 2348810503 L_TP_L_DHL_FD_BDC_FD_Byte6 5000;
BA_ "NetworkRequest" SG_ 2348810503 L_TP_L_DHL_FD_BDC_FD_Byte6 0;
BA_ "UserSigValidity" SG_ 2348810503 L_TP_L_DHL_FD_BDC_FD_Byte6 0;
BA_ "UsrSigPurpose" SG_ 2348810503 L_TP_L_DHL_FD_BDC_FD_Byte6 9;
BA_ "Description" SG_ 2348810503 L_TP_L_DHL_FD_BDC_FD_Byte6 "TP Index : 273";
BA_ "Version" SG_ 2348810503 L_TP_L_DHL_FD_BDC_FD_Byte7 "23.01.02";
BA_ "NetworkRequestHoldingTime" SG_ 2348810503 L_TP_L_DHL_FD_BDC_FD_Byte7 5000;
BA_ "NetworkRequest" SG_ 2348810503 L_TP_L_DHL_FD_BDC_FD_Byte7 0;
BA_ "UserSigValidity" SG_ 2348810503 L_TP_L_DHL_FD_BDC_FD_Byte7 0;
BA_ "UsrSigPurpose" SG_ 2348810503 L_TP_L_DHL_FD_BDC_FD_Byte7 9;
BA_ "Description" SG_ 2348810503 L_TP_L_DHL_FD_BDC_FD_Byte7 "TP Index : 273";
BA_ "Version" SG_ 2348810503 L_TP_L_DHL_FD_BDC_FD_Byte8 "23.01.02";
BA_ "NetworkRequestHoldingTime" SG_ 2348810503 L_TP_L_DHL_FD_BDC_FD_Byte8 5000;
BA_ "NetworkRequest" SG_ 2348810503 L_TP_L_DHL_FD_BDC_FD_Byte8 0;
BA_ "UserSigValidity" SG_ 2348810503 L_TP_L_DHL_FD_BDC_FD_Byte8 0;
BA_ "UsrSigPurpose" SG_ 2348810503 L_TP_L_DHL_FD_BDC_FD_Byte8 9;
BA_ "Description" SG_ 2348810503 L_TP_L_DHL_FD_BDC_FD_Byte8 "TP Index : 273";
BA_ "Version" SG_ 2348810503 L_TP_L_DHL_FD_BDC_FD_Byte9 "23.01.02";
BA_ "NetworkRequestHoldingTime" SG_ 2348810503 L_TP_L_DHL_FD_BDC_FD_Byte9 5000;
BA_ "NetworkRequest" SG_ 2348810503 L_TP_L_DHL_FD_BDC_FD_Byte9 0;
BA_ "UserSigValidity" SG_ 2348810503 L_TP_L_DHL_FD_BDC_FD_Byte9 0;
BA_ "UsrSigPurpose" SG_ 2348810503 L_TP_L_DHL_FD_BDC_FD_Byte9 9;
BA_ "Description" SG_ 2348810503 L_TP_L_DHL_FD_BDC_FD_Byte9 "TP Index : 273";
BA_ "Version" SG_ 2348810503 L_TP_L_DHL_FD_BDC_FD_Byte1 "23.01.02";
BA_ "NetworkRequestHoldingTime" SG_ 2348810503 L_TP_L_DHL_FD_BDC_FD_Byte1 5000;
BA_ "NetworkRequest" SG_ 2348810503 L_TP_L_DHL_FD_BDC_FD_Byte1 0;
BA_ "UserSigValidity" SG_ 2348810503 L_TP_L_DHL_FD_BDC_FD_Byte1 0;
BA_ "UsrSigPurpose" SG_ 2348810503 L_TP_L_DHL_FD_BDC_FD_Byte1 9;
BA_ "Description" SG_ 2348810503 L_TP_L_DHL_FD_BDC_FD_Byte1 "TP Index : 273";
BA_ "Version" SG_ 2348810503 L_TP_L_DHL_FD_BDC_FD_Byte10 "23.01.02";
BA_ "NetworkRequestHoldingTime" SG_ 2348810503 L_TP_L_DHL_FD_BDC_FD_Byte10 5000;
BA_ "NetworkRequest" SG_ 2348810503 L_TP_L_DHL_FD_BDC_FD_Byte10 0;
BA_ "UserSigValidity" SG_ 2348810503 L_TP_L_DHL_FD_BDC_FD_Byte10 0;
BA_ "UsrSigPurpose" SG_ 2348810503 L_TP_L_DHL_FD_BDC_FD_Byte10 9;
BA_ "Description" SG_ 2348810503 L_TP_L_DHL_FD_BDC_FD_Byte10 "TP Index : 273";
BA_ "Version" SG_ 2348810503 L_TP_L_DHL_FD_BDC_FD_Byte11 "23.01.02";
BA_ "NetworkRequestHoldingTime" SG_ 2348810503 L_TP_L_DHL_FD_BDC_FD_Byte11 5000;
BA_ "NetworkRequest" SG_ 2348810503 L_TP_L_DHL_FD_BDC_FD_Byte11 0;
BA_ "UserSigValidity" SG_ 2348810503 L_TP_L_DHL_FD_BDC_FD_Byte11 0;
BA_ "UsrSigPurpose" SG_ 2348810503 L_TP_L_DHL_FD_BDC_FD_Byte11 9;
BA_ "Description" SG_ 2348810503 L_TP_L_DHL_FD_BDC_FD_Byte11 "TP Index : 273";
BA_ "Version" SG_ 2348810503 L_TP_L_DHL_FD_BDC_FD_Byte12 "23.01.02";
BA_ "NetworkRequestHoldingTime" SG_ 2348810503 L_TP_L_DHL_FD_BDC_FD_Byte12 5000;
BA_ "NetworkRequest" SG_ 2348810503 L_TP_L_DHL_FD_BDC_FD_Byte12 0;
BA_ "UserSigValidity" SG_ 2348810503 L_TP_L_DHL_FD_BDC_FD_Byte12 0;
BA_ "UsrSigPurpose" SG_ 2348810503 L_TP_L_DHL_FD_BDC_FD_Byte12 9;
BA_ "Description" SG_ 2348810503 L_TP_L_DHL_FD_BDC_FD_Byte12 "TP Index : 273";
BA_ "Version" SG_ 2214592660 DHR_Dvp_Msg "23.01.02";
BA_ "UserSigValidity" SG_ 2214592660 DHR_Dvp_Msg 0;
BA_ "GenSigSendType" SG_ 2214592660 DHR_Dvp_Msg 2;
BA_ "Version" SG_ 2348810502 L_TP_BDC_FD_L_DHL_FD_Byte0 "23.01.02";
BA_ "NetworkRequestHoldingTime" SG_ 2348810502 L_TP_BDC_FD_L_DHL_FD_Byte0 5000;
BA_ "NetworkRequest" SG_ 2348810502 L_TP_BDC_FD_L_DHL_FD_Byte0 0;
BA_ "UserSigValidity" SG_ 2348810502 L_TP_BDC_FD_L_DHL_FD_Byte0 0;
BA_ "UsrSigPurpose" SG_ 2348810502 L_TP_BDC_FD_L_DHL_FD_Byte0 9;
BA_ "Description" SG_ 2348810502 L_TP_BDC_FD_L_DHL_FD_Byte0 "TP Index : 273";
BA_ "Version" SG_ 2348810502 L_TP_BDC_FD_L_DHL_FD_Byte13 "23.01.02";
BA_ "NetworkRequestHoldingTime" SG_ 2348810502 L_TP_BDC_FD_L_DHL_FD_Byte13 5000;
BA_ "NetworkRequest" SG_ 2348810502 L_TP_BDC_FD_L_DHL_FD_Byte13 0;
BA_ "UserSigValidity" SG_ 2348810502 L_TP_BDC_FD_L_DHL_FD_Byte13 0;
BA_ "UsrSigPurpose" SG_ 2348810502 L_TP_BDC_FD_L_DHL_FD_Byte13 9;
BA_ "Description" SG_ 2348810502 L_TP_BDC_FD_L_DHL_FD_Byte13 "TP Index : 273";
BA_ "Version" SG_ 2348810502 L_TP_BDC_FD_L_DHL_FD_Byte14 "23.01.02";
BA_ "NetworkRequestHoldingTime" SG_ 2348810502 L_TP_BDC_FD_L_DHL_FD_Byte14 5000;
BA_ "NetworkRequest" SG_ 2348810502 L_TP_BDC_FD_L_DHL_FD_Byte14 0;
BA_ "UserSigValidity" SG_ 2348810502 L_TP_BDC_FD_L_DHL_FD_Byte14 0;
BA_ "UsrSigPurpose" SG_ 2348810502 L_TP_BDC_FD_L_DHL_FD_Byte14 9;
BA_ "Description" SG_ 2348810502 L_TP_BDC_FD_L_DHL_FD_Byte14 "TP Index : 273";
BA_ "Version" SG_ 2348810502 L_TP_BDC_FD_L_DHL_FD_Byte15 "23.01.02";
BA_ "NetworkRequestHoldingTime" SG_ 2348810502 L_TP_BDC_FD_L_DHL_FD_Byte15 5000;
BA_ "NetworkRequest" SG_ 2348810502 L_TP_BDC_FD_L_DHL_FD_Byte15 0;
BA_ "UserSigValidity" SG_ 2348810502 L_TP_BDC_FD_L_DHL_FD_Byte15 0;
BA_ "UsrSigPurpose" SG_ 2348810502 L_TP_BDC_FD_L_DHL_FD_Byte15 9;
BA_ "Description" SG_ 2348810502 L_TP_BDC_FD_L_DHL_FD_Byte15 "TP Index : 273";
BA_ "Version" SG_ 2348810502 L_TP_BDC_FD_L_DHL_FD_Byte16 "23.01.02";
BA_ "NetworkRequestHoldingTime" SG_ 2348810502 L_TP_BDC_FD_L_DHL_FD_Byte16 5000;
BA_ "NetworkRequest" SG_ 2348810502 L_TP_BDC_FD_L_DHL_FD_Byte16 0;
BA_ "UserSigValidity" SG_ 2348810502 L_TP_BDC_FD_L_DHL_FD_Byte16 0;
BA_ "UsrSigPurpose" SG_ 2348810502 L_TP_BDC_FD_L_DHL_FD_Byte16 9;
BA_ "Description" SG_ 2348810502 L_TP_BDC_FD_L_DHL_FD_Byte16 "TP Index : 273";
BA_ "Version" SG_ 2348810502 L_TP_BDC_FD_L_DHL_FD_Byte17 "23.01.02";
BA_ "NetworkRequestHoldingTime" SG_ 2348810502 L_TP_BDC_FD_L_DHL_FD_Byte17 5000;
BA_ "NetworkRequest" SG_ 2348810502 L_TP_BDC_FD_L_DHL_FD_Byte17 0;
BA_ "UserSigValidity" SG_ 2348810502 L_TP_BDC_FD_L_DHL_FD_Byte17 0;
BA_ "UsrSigPurpose" SG_ 2348810502 L_TP_BDC_FD_L_DHL_FD_Byte17 9;
BA_ "Description" SG_ 2348810502 L_TP_BDC_FD_L_DHL_FD_Byte17 "TP Index : 273";
BA_ "Version" SG_ 2348810502 L_TP_BDC_FD_L_DHL_FD_Byte18 "23.01.02";
BA_ "NetworkRequestHoldingTime" SG_ 2348810502 L_TP_BDC_FD_L_DHL_FD_Byte18 5000;
BA_ "NetworkRequest" SG_ 2348810502 L_TP_BDC_FD_L_DHL_FD_Byte18 0;
BA_ "UserSigValidity" SG_ 2348810502 L_TP_BDC_FD_L_DHL_FD_Byte18 0;
BA_ "UsrSigPurpose" SG_ 2348810502 L_TP_BDC_FD_L_DHL_FD_Byte18 9;
BA_ "Description" SG_ 2348810502 L_TP_BDC_FD_L_DHL_FD_Byte18 "TP Index : 273";
BA_ "Version" SG_ 2348810502 L_TP_BDC_FD_L_DHL_FD_Byte19 "23.01.02";
BA_ "NetworkRequestHoldingTime" SG_ 2348810502 L_TP_BDC_FD_L_DHL_FD_Byte19 5000;
BA_ "NetworkRequest" SG_ 2348810502 L_TP_BDC_FD_L_DHL_FD_Byte19 0;
BA_ "UserSigValidity" SG_ 2348810502 L_TP_BDC_FD_L_DHL_FD_Byte19 0;
BA_ "UsrSigPurpose" SG_ 2348810502 L_TP_BDC_FD_L_DHL_FD_Byte19 9;
BA_ "Description" SG_ 2348810502 L_TP_BDC_FD_L_DHL_FD_Byte19 "TP Index : 273";
BA_ "Version" SG_ 2348810502 L_TP_BDC_FD_L_DHL_FD_Byte2 "23.01.02";
BA_ "NetworkRequestHoldingTime" SG_ 2348810502 L_TP_BDC_FD_L_DHL_FD_Byte2 5000;
BA_ "NetworkRequest" SG_ 2348810502 L_TP_BDC_FD_L_DHL_FD_Byte2 0;
BA_ "UserSigValidity" SG_ 2348810502 L_TP_BDC_FD_L_DHL_FD_Byte2 0;
BA_ "UsrSigPurpose" SG_ 2348810502 L_TP_BDC_FD_L_DHL_FD_Byte2 9;
BA_ "Description" SG_ 2348810502 L_TP_BDC_FD_L_DHL_FD_Byte2 "TP Index : 273";
BA_ "Version" SG_ 2348810502 L_TP_BDC_FD_L_DHL_FD_Byte20 "23.01.02";
BA_ "NetworkRequestHoldingTime" SG_ 2348810502 L_TP_BDC_FD_L_DHL_FD_Byte20 5000;
BA_ "NetworkRequest" SG_ 2348810502 L_TP_BDC_FD_L_DHL_FD_Byte20 0;
BA_ "UserSigValidity" SG_ 2348810502 L_TP_BDC_FD_L_DHL_FD_Byte20 0;
BA_ "UsrSigPurpose" SG_ 2348810502 L_TP_BDC_FD_L_DHL_FD_Byte20 9;
BA_ "Description" SG_ 2348810502 L_TP_BDC_FD_L_DHL_FD_Byte20 "TP Index : 273";
BA_ "Version" SG_ 2348810502 L_TP_BDC_FD_L_DHL_FD_Byte21 "23.01.02";
BA_ "NetworkRequestHoldingTime" SG_ 2348810502 L_TP_BDC_FD_L_DHL_FD_Byte21 5000;
BA_ "NetworkRequest" SG_ 2348810502 L_TP_BDC_FD_L_DHL_FD_Byte21 0;
BA_ "UserSigValidity" SG_ 2348810502 L_TP_BDC_FD_L_DHL_FD_Byte21 0;
BA_ "UsrSigPurpose" SG_ 2348810502 L_TP_BDC_FD_L_DHL_FD_Byte21 9;
BA_ "Description" SG_ 2348810502 L_TP_BDC_FD_L_DHL_FD_Byte21 "TP Index : 273";
BA_ "Version" SG_ 2348810502 L_TP_BDC_FD_L_DHL_FD_Byte22 "23.01.02";
BA_ "NetworkRequestHoldingTime" SG_ 2348810502 L_TP_BDC_FD_L_DHL_FD_Byte22 5000;
BA_ "NetworkRequest" SG_ 2348810502 L_TP_BDC_FD_L_DHL_FD_Byte22 0;
BA_ "UserSigValidity" SG_ 2348810502 L_TP_BDC_FD_L_DHL_FD_Byte22 0;
BA_ "UsrSigPurpose" SG_ 2348810502 L_TP_BDC_FD_L_DHL_FD_Byte22 9;
BA_ "Description" SG_ 2348810502 L_TP_BDC_FD_L_DHL_FD_Byte22 "TP Index : 273";
BA_ "Version" SG_ 2348810502 L_TP_BDC_FD_L_DHL_FD_Byte23 "23.01.02";
BA_ "NetworkRequestHoldingTime" SG_ 2348810502 L_TP_BDC_FD_L_DHL_FD_Byte23 5000;
BA_ "NetworkRequest" SG_ 2348810502 L_TP_BDC_FD_L_DHL_FD_Byte23 0;
BA_ "UserSigValidity" SG_ 2348810502 L_TP_BDC_FD_L_DHL_FD_Byte23 0;
BA_ "UsrSigPurpose" SG_ 2348810502 L_TP_BDC_FD_L_DHL_FD_Byte23 9;
BA_ "Description" SG_ 2348810502 L_TP_BDC_FD_L_DHL_FD_Byte23 "TP Index : 273";
BA_ "Version" SG_ 2348810502 L_TP_BDC_FD_L_DHL_FD_Byte24 "23.01.02";
BA_ "NetworkRequestHoldingTime" SG_ 2348810502 L_TP_BDC_FD_L_DHL_FD_Byte24 5000;
BA_ "NetworkRequest" SG_ 2348810502 L_TP_BDC_FD_L_DHL_FD_Byte24 0;
BA_ "UserSigValidity" SG_ 2348810502 L_TP_BDC_FD_L_DHL_FD_Byte24 0;
BA_ "UsrSigPurpose" SG_ 2348810502 L_TP_BDC_FD_L_DHL_FD_Byte24 9;
BA_ "Description" SG_ 2348810502 L_TP_BDC_FD_L_DHL_FD_Byte24 "TP Index : 273";
BA_ "Version" SG_ 2348810502 L_TP_BDC_FD_L_DHL_FD_Byte25 "23.01.02";
BA_ "NetworkRequestHoldingTime" SG_ 2348810502 L_TP_BDC_FD_L_DHL_FD_Byte25 5000;
BA_ "NetworkRequest" SG_ 2348810502 L_TP_BDC_FD_L_DHL_FD_Byte25 0;
BA_ "UserSigValidity" SG_ 2348810502 L_TP_BDC_FD_L_DHL_FD_Byte25 0;
BA_ "UsrSigPurpose" SG_ 2348810502 L_TP_BDC_FD_L_DHL_FD_Byte25 9;
BA_ "Description" SG_ 2348810502 L_TP_BDC_FD_L_DHL_FD_Byte25 "TP Index : 273";
BA_ "Version" SG_ 2348810502 L_TP_BDC_FD_L_DHL_FD_Byte26 "23.01.02";
BA_ "NetworkRequestHoldingTime" SG_ 2348810502 L_TP_BDC_FD_L_DHL_FD_Byte26 5000;
BA_ "NetworkRequest" SG_ 2348810502 L_TP_BDC_FD_L_DHL_FD_Byte26 0;
BA_ "UserSigValidity" SG_ 2348810502 L_TP_BDC_FD_L_DHL_FD_Byte26 0;
BA_ "UsrSigPurpose" SG_ 2348810502 L_TP_BDC_FD_L_DHL_FD_Byte26 9;
BA_ "Description" SG_ 2348810502 L_TP_BDC_FD_L_DHL_FD_Byte26 "TP Index : 273";
BA_ "Version" SG_ 2348810502 L_TP_BDC_FD_L_DHL_FD_Byte27 "23.01.02";
BA_ "NetworkRequestHoldingTime" SG_ 2348810502 L_TP_BDC_FD_L_DHL_FD_Byte27 5000;
BA_ "NetworkRequest" SG_ 2348810502 L_TP_BDC_FD_L_DHL_FD_Byte27 0;
BA_ "UserSigValidity" SG_ 2348810502 L_TP_BDC_FD_L_DHL_FD_Byte27 0;
BA_ "UsrSigPurpose" SG_ 2348810502 L_TP_BDC_FD_L_DHL_FD_Byte27 9;
BA_ "Description" SG_ 2348810502 L_TP_BDC_FD_L_DHL_FD_Byte27 "TP Index : 273";
BA_ "Version" SG_ 2348810502 L_TP_BDC_FD_L_DHL_FD_Byte28 "23.01.02";
BA_ "NetworkRequestHoldingTime" SG_ 2348810502 L_TP_BDC_FD_L_DHL_FD_Byte28 5000;
BA_ "NetworkRequest" SG_ 2348810502 L_TP_BDC_FD_L_DHL_FD_Byte28 0;
BA_ "UserSigValidity" SG_ 2348810502 L_TP_BDC_FD_L_DHL_FD_Byte28 0;
BA_ "UsrSigPurpose" SG_ 2348810502 L_TP_BDC_FD_L_DHL_FD_Byte28 9;
BA_ "Description" SG_ 2348810502 L_TP_BDC_FD_L_DHL_FD_Byte28 "TP Index : 273";
BA_ "Version" SG_ 2348810502 L_TP_BDC_FD_L_DHL_FD_Byte29 "23.01.02";
BA_ "NetworkRequestHoldingTime" SG_ 2348810502 L_TP_BDC_FD_L_DHL_FD_Byte29 5000;
BA_ "NetworkRequest" SG_ 2348810502 L_TP_BDC_FD_L_DHL_FD_Byte29 0;
BA_ "UserSigValidity" SG_ 2348810502 L_TP_BDC_FD_L_DHL_FD_Byte29 0;
BA_ "UsrSigPurpose" SG_ 2348810502 L_TP_BDC_FD_L_DHL_FD_Byte29 9;
BA_ "Description" SG_ 2348810502 L_TP_BDC_FD_L_DHL_FD_Byte29 "TP Index : 273";
BA_ "Version" SG_ 2348810502 L_TP_BDC_FD_L_DHL_FD_Byte3 "23.01.02";
BA_ "NetworkRequestHoldingTime" SG_ 2348810502 L_TP_BDC_FD_L_DHL_FD_Byte3 5000;
BA_ "NetworkRequest" SG_ 2348810502 L_TP_BDC_FD_L_DHL_FD_Byte3 0;
BA_ "UserSigValidity" SG_ 2348810502 L_TP_BDC_FD_L_DHL_FD_Byte3 0;
BA_ "UsrSigPurpose" SG_ 2348810502 L_TP_BDC_FD_L_DHL_FD_Byte3 9;
BA_ "Description" SG_ 2348810502 L_TP_BDC_FD_L_DHL_FD_Byte3 "TP Index : 273";
BA_ "Version" SG_ 2348810502 L_TP_BDC_FD_L_DHL_FD_Byte30 "23.01.02";
BA_ "NetworkRequestHoldingTime" SG_ 2348810502 L_TP_BDC_FD_L_DHL_FD_Byte30 5000;
BA_ "NetworkRequest" SG_ 2348810502 L_TP_BDC_FD_L_DHL_FD_Byte30 0;
BA_ "UserSigValidity" SG_ 2348810502 L_TP_BDC_FD_L_DHL_FD_Byte30 0;
BA_ "UsrSigPurpose" SG_ 2348810502 L_TP_BDC_FD_L_DHL_FD_Byte30 9;
BA_ "Description" SG_ 2348810502 L_TP_BDC_FD_L_DHL_FD_Byte30 "TP Index : 273";
BA_ "Version" SG_ 2348810502 L_TP_BDC_FD_L_DHL_FD_Byte31 "23.01.02";
BA_ "NetworkRequestHoldingTime" SG_ 2348810502 L_TP_BDC_FD_L_DHL_FD_Byte31 5000;
BA_ "NetworkRequest" SG_ 2348810502 L_TP_BDC_FD_L_DHL_FD_Byte31 0;
BA_ "UserSigValidity" SG_ 2348810502 L_TP_BDC_FD_L_DHL_FD_Byte31 0;
BA_ "UsrSigPurpose" SG_ 2348810502 L_TP_BDC_FD_L_DHL_FD_Byte31 9;
BA_ "Description" SG_ 2348810502 L_TP_BDC_FD_L_DHL_FD_Byte31 "TP Index : 273";
BA_ "Version" SG_ 2348810502 L_TP_BDC_FD_L_DHL_FD_Byte4 "23.01.02";
BA_ "NetworkRequestHoldingTime" SG_ 2348810502 L_TP_BDC_FD_L_DHL_FD_Byte4 5000;
BA_ "NetworkRequest" SG_ 2348810502 L_TP_BDC_FD_L_DHL_FD_Byte4 0;
BA_ "UserSigValidity" SG_ 2348810502 L_TP_BDC_FD_L_DHL_FD_Byte4 0;
BA_ "UsrSigPurpose" SG_ 2348810502 L_TP_BDC_FD_L_DHL_FD_Byte4 9;
BA_ "Description" SG_ 2348810502 L_TP_BDC_FD_L_DHL_FD_Byte4 "TP Index : 273";
BA_ "Version" SG_ 2348810502 L_TP_BDC_FD_L_DHL_FD_Byte5 "23.01.02";
BA_ "NetworkRequestHoldingTime" SG_ 2348810502 L_TP_BDC_FD_L_DHL_FD_Byte5 5000;
BA_ "NetworkRequest" SG_ 2348810502 L_TP_BDC_FD_L_DHL_FD_Byte5 0;
BA_ "UserSigValidity" SG_ 2348810502 L_TP_BDC_FD_L_DHL_FD_Byte5 0;
BA_ "UsrSigPurpose" SG_ 2348810502 L_TP_BDC_FD_L_DHL_FD_Byte5 9;
BA_ "Description" SG_ 2348810502 L_TP_BDC_FD_L_DHL_FD_Byte5 "TP Index : 273";
BA_ "Version" SG_ 2348810502 L_TP_BDC_FD_L_DHL_FD_Byte6 "23.01.02";
BA_ "NetworkRequestHoldingTime" SG_ 2348810502 L_TP_BDC_FD_L_DHL_FD_Byte6 5000;
BA_ "NetworkRequest" SG_ 2348810502 L_TP_BDC_FD_L_DHL_FD_Byte6 0;
BA_ "UserSigValidity" SG_ 2348810502 L_TP_BDC_FD_L_DHL_FD_Byte6 0;
BA_ "UsrSigPurpose" SG_ 2348810502 L_TP_BDC_FD_L_DHL_FD_Byte6 9;
BA_ "Description" SG_ 2348810502 L_TP_BDC_FD_L_DHL_FD_Byte6 "TP Index : 273";
BA_ "Version" SG_ 2348810502 L_TP_BDC_FD_L_DHL_FD_Byte7 "23.01.02";
BA_ "NetworkRequestHoldingTime" SG_ 2348810502 L_TP_BDC_FD_L_DHL_FD_Byte7 5000;
BA_ "NetworkRequest" SG_ 2348810502 L_TP_BDC_FD_L_DHL_FD_Byte7 0;
BA_ "UserSigValidity" SG_ 2348810502 L_TP_BDC_FD_L_DHL_FD_Byte7 0;
BA_ "UsrSigPurpose" SG_ 2348810502 L_TP_BDC_FD_L_DHL_FD_Byte7 9;
BA_ "Description" SG_ 2348810502 L_TP_BDC_FD_L_DHL_FD_Byte7 "TP Index : 273";
BA_ "Version" SG_ 2348810502 L_TP_BDC_FD_L_DHL_FD_Byte8 "23.01.02";
BA_ "NetworkRequestHoldingTime" SG_ 2348810502 L_TP_BDC_FD_L_DHL_FD_Byte8 5000;
BA_ "NetworkRequest" SG_ 2348810502 L_TP_BDC_FD_L_DHL_FD_Byte8 0;
BA_ "UserSigValidity" SG_ 2348810502 L_TP_BDC_FD_L_DHL_FD_Byte8 0;
BA_ "UsrSigPurpose" SG_ 2348810502 L_TP_BDC_FD_L_DHL_FD_Byte8 9;
BA_ "Description" SG_ 2348810502 L_TP_BDC_FD_L_DHL_FD_Byte8 "TP Index : 273";
BA_ "Version" SG_ 2348810502 L_TP_BDC_FD_L_DHL_FD_Byte9 "23.01.02";
BA_ "NetworkRequestHoldingTime" SG_ 2348810502 L_TP_BDC_FD_L_DHL_FD_Byte9 5000;
BA_ "NetworkRequest" SG_ 2348810502 L_TP_BDC_FD_L_DHL_FD_Byte9 0;
BA_ "UserSigValidity" SG_ 2348810502 L_TP_BDC_FD_L_DHL_FD_Byte9 0;
BA_ "UsrSigPurpose" SG_ 2348810502 L_TP_BDC_FD_L_DHL_FD_Byte9 9;
BA_ "Description" SG_ 2348810502 L_TP_BDC_FD_L_DHL_FD_Byte9 "TP Index : 273";
BA_ "Version" SG_ 2348810502 L_TP_BDC_FD_L_DHL_FD_Byte1 "23.01.02";
BA_ "NetworkRequestHoldingTime" SG_ 2348810502 L_TP_BDC_FD_L_DHL_FD_Byte1 5000;
BA_ "NetworkRequest" SG_ 2348810502 L_TP_BDC_FD_L_DHL_FD_Byte1 0;
BA_ "UserSigValidity" SG_ 2348810502 L_TP_BDC_FD_L_DHL_FD_Byte1 0;
BA_ "UsrSigPurpose" SG_ 2348810502 L_TP_BDC_FD_L_DHL_FD_Byte1 9;
BA_ "Description" SG_ 2348810502 L_TP_BDC_FD_L_DHL_FD_Byte1 "TP Index : 273";
BA_ "Version" SG_ 2348810502 L_TP_BDC_FD_L_DHL_FD_Byte10 "23.01.02";
BA_ "NetworkRequestHoldingTime" SG_ 2348810502 L_TP_BDC_FD_L_DHL_FD_Byte10 5000;
BA_ "NetworkRequest" SG_ 2348810502 L_TP_BDC_FD_L_DHL_FD_Byte10 0;
BA_ "UserSigValidity" SG_ 2348810502 L_TP_BDC_FD_L_DHL_FD_Byte10 0;
BA_ "UsrSigPurpose" SG_ 2348810502 L_TP_BDC_FD_L_DHL_FD_Byte10 9;
BA_ "Description" SG_ 2348810502 L_TP_BDC_FD_L_DHL_FD_Byte10 "TP Index : 273";
BA_ "Version" SG_ 2348810502 L_TP_BDC_FD_L_DHL_FD_Byte11 "23.01.02";
BA_ "NetworkRequestHoldingTime" SG_ 2348810502 L_TP_BDC_FD_L_DHL_FD_Byte11 5000;
BA_ "NetworkRequest" SG_ 2348810502 L_TP_BDC_FD_L_DHL_FD_Byte11 0;
BA_ "UserSigValidity" SG_ 2348810502 L_TP_BDC_FD_L_DHL_FD_Byte11 0;
BA_ "UsrSigPurpose" SG_ 2348810502 L_TP_BDC_FD_L_DHL_FD_Byte11 9;
BA_ "Description" SG_ 2348810502 L_TP_BDC_FD_L_DHL_FD_Byte11 "TP Index : 273";
BA_ "Version" SG_ 2348810502 L_TP_BDC_FD_L_DHL_FD_Byte12 "23.01.02";
BA_ "NetworkRequestHoldingTime" SG_ 2348810502 L_TP_BDC_FD_L_DHL_FD_Byte12 5000;
BA_ "NetworkRequest" SG_ 2348810502 L_TP_BDC_FD_L_DHL_FD_Byte12 0;
BA_ "UserSigValidity" SG_ 2348810502 L_TP_BDC_FD_L_DHL_FD_Byte12 0;
BA_ "UsrSigPurpose" SG_ 2348810502 L_TP_BDC_FD_L_DHL_FD_Byte12 9;
BA_ "Description" SG_ 2348810502 L_TP_BDC_FD_L_DHL_FD_Byte12 "TP Index : 273";
BA_ "Version" SG_ 2214592661 DHRR_Dvp_Msg "23.06.01";
BA_ "UserSigValidity" SG_ 2214592661 DHRR_Dvp_Msg 0;
BA_ "GenSigSendType" SG_ 2214592661 DHRR_Dvp_Msg 2;
BA_ "GenSigSendType" SG_ 2348810501 L_TP_L_WPC_FD_BDC_FD_Byte0 2;
BA_ "Version" SG_ 2348810501 L_TP_L_WPC_FD_BDC_FD_Byte0 "23.01.02";
BA_ "NetworkRequestHoldingTime" SG_ 2348810501 L_TP_L_WPC_FD_BDC_FD_Byte0 5000;
BA_ "NetworkRequest" SG_ 2348810501 L_TP_L_WPC_FD_BDC_FD_Byte0 0;
BA_ "UserSigValidity" SG_ 2348810501 L_TP_L_WPC_FD_BDC_FD_Byte0 0;
BA_ "UsrSigPurpose" SG_ 2348810501 L_TP_L_WPC_FD_BDC_FD_Byte0 9;
BA_ "Description" SG_ 2348810501 L_TP_L_WPC_FD_BDC_FD_Byte0 "TP Index : 272";
BA_ "GenSigSendType" SG_ 2348810501 L_TP_L_WPC_FD_BDC_FD_Byte13 2;
BA_ "Version" SG_ 2348810501 L_TP_L_WPC_FD_BDC_FD_Byte13 "23.01.02";
BA_ "NetworkRequestHoldingTime" SG_ 2348810501 L_TP_L_WPC_FD_BDC_FD_Byte13 5000;
BA_ "NetworkRequest" SG_ 2348810501 L_TP_L_WPC_FD_BDC_FD_Byte13 0;
BA_ "UserSigValidity" SG_ 2348810501 L_TP_L_WPC_FD_BDC_FD_Byte13 0;
BA_ "UsrSigPurpose" SG_ 2348810501 L_TP_L_WPC_FD_BDC_FD_Byte13 9;
BA_ "Description" SG_ 2348810501 L_TP_L_WPC_FD_BDC_FD_Byte13 "TP Index : 272";
BA_ "GenSigSendType" SG_ 2348810501 L_TP_L_WPC_FD_BDC_FD_Byte14 2;
BA_ "Version" SG_ 2348810501 L_TP_L_WPC_FD_BDC_FD_Byte14 "23.01.02";
BA_ "NetworkRequestHoldingTime" SG_ 2348810501 L_TP_L_WPC_FD_BDC_FD_Byte14 5000;
BA_ "NetworkRequest" SG_ 2348810501 L_TP_L_WPC_FD_BDC_FD_Byte14 0;
BA_ "UserSigValidity" SG_ 2348810501 L_TP_L_WPC_FD_BDC_FD_Byte14 0;
BA_ "UsrSigPurpose" SG_ 2348810501 L_TP_L_WPC_FD_BDC_FD_Byte14 9;
BA_ "Description" SG_ 2348810501 L_TP_L_WPC_FD_BDC_FD_Byte14 "TP Index : 272";
BA_ "GenSigSendType" SG_ 2348810501 L_TP_L_WPC_FD_BDC_FD_Byte15 2;
BA_ "Version" SG_ 2348810501 L_TP_L_WPC_FD_BDC_FD_Byte15 "23.01.02";
BA_ "NetworkRequestHoldingTime" SG_ 2348810501 L_TP_L_WPC_FD_BDC_FD_Byte15 5000;
BA_ "NetworkRequest" SG_ 2348810501 L_TP_L_WPC_FD_BDC_FD_Byte15 0;
BA_ "UserSigValidity" SG_ 2348810501 L_TP_L_WPC_FD_BDC_FD_Byte15 0;
BA_ "UsrSigPurpose" SG_ 2348810501 L_TP_L_WPC_FD_BDC_FD_Byte15 9;
BA_ "Description" SG_ 2348810501 L_TP_L_WPC_FD_BDC_FD_Byte15 "TP Index : 272";
BA_ "GenSigSendType" SG_ 2348810501 L_TP_L_WPC_FD_BDC_FD_Byte16 2;
BA_ "Version" SG_ 2348810501 L_TP_L_WPC_FD_BDC_FD_Byte16 "23.01.02";
BA_ "NetworkRequestHoldingTime" SG_ 2348810501 L_TP_L_WPC_FD_BDC_FD_Byte16 5000;
BA_ "NetworkRequest" SG_ 2348810501 L_TP_L_WPC_FD_BDC_FD_Byte16 0;
BA_ "UserSigValidity" SG_ 2348810501 L_TP_L_WPC_FD_BDC_FD_Byte16 0;
BA_ "UsrSigPurpose" SG_ 2348810501 L_TP_L_WPC_FD_BDC_FD_Byte16 9;
BA_ "Description" SG_ 2348810501 L_TP_L_WPC_FD_BDC_FD_Byte16 "TP Index : 272";
BA_ "GenSigSendType" SG_ 2348810501 L_TP_L_WPC_FD_BDC_FD_Byte17 2;
BA_ "Version" SG_ 2348810501 L_TP_L_WPC_FD_BDC_FD_Byte17 "23.01.02";
BA_ "NetworkRequestHoldingTime" SG_ 2348810501 L_TP_L_WPC_FD_BDC_FD_Byte17 5000;
BA_ "NetworkRequest" SG_ 2348810501 L_TP_L_WPC_FD_BDC_FD_Byte17 0;
BA_ "UserSigValidity" SG_ 2348810501 L_TP_L_WPC_FD_BDC_FD_Byte17 0;
BA_ "UsrSigPurpose" SG_ 2348810501 L_TP_L_WPC_FD_BDC_FD_Byte17 9;
BA_ "Description" SG_ 2348810501 L_TP_L_WPC_FD_BDC_FD_Byte17 "TP Index : 272";
BA_ "GenSigSendType" SG_ 2348810501 L_TP_L_WPC_FD_BDC_FD_Byte18 2;
BA_ "Version" SG_ 2348810501 L_TP_L_WPC_FD_BDC_FD_Byte18 "23.01.02";
BA_ "NetworkRequestHoldingTime" SG_ 2348810501 L_TP_L_WPC_FD_BDC_FD_Byte18 5000;
BA_ "NetworkRequest" SG_ 2348810501 L_TP_L_WPC_FD_BDC_FD_Byte18 0;
BA_ "UserSigValidity" SG_ 2348810501 L_TP_L_WPC_FD_BDC_FD_Byte18 0;
BA_ "UsrSigPurpose" SG_ 2348810501 L_TP_L_WPC_FD_BDC_FD_Byte18 9;
BA_ "Description" SG_ 2348810501 L_TP_L_WPC_FD_BDC_FD_Byte18 "TP Index : 272";
BA_ "GenSigSendType" SG_ 2348810501 L_TP_L_WPC_FD_BDC_FD_Byte19 2;
BA_ "Version" SG_ 2348810501 L_TP_L_WPC_FD_BDC_FD_Byte19 "23.01.02";
BA_ "NetworkRequestHoldingTime" SG_ 2348810501 L_TP_L_WPC_FD_BDC_FD_Byte19 5000;
BA_ "NetworkRequest" SG_ 2348810501 L_TP_L_WPC_FD_BDC_FD_Byte19 0;
BA_ "UserSigValidity" SG_ 2348810501 L_TP_L_WPC_FD_BDC_FD_Byte19 0;
BA_ "UsrSigPurpose" SG_ 2348810501 L_TP_L_WPC_FD_BDC_FD_Byte19 9;
BA_ "Description" SG_ 2348810501 L_TP_L_WPC_FD_BDC_FD_Byte19 "TP Index : 272";
BA_ "GenSigSendType" SG_ 2348810501 L_TP_L_WPC_FD_BDC_FD_Byte2 2;
BA_ "Version" SG_ 2348810501 L_TP_L_WPC_FD_BDC_FD_Byte2 "23.01.02";
BA_ "NetworkRequestHoldingTime" SG_ 2348810501 L_TP_L_WPC_FD_BDC_FD_Byte2 5000;
BA_ "NetworkRequest" SG_ 2348810501 L_TP_L_WPC_FD_BDC_FD_Byte2 0;
BA_ "UserSigValidity" SG_ 2348810501 L_TP_L_WPC_FD_BDC_FD_Byte2 0;
BA_ "UsrSigPurpose" SG_ 2348810501 L_TP_L_WPC_FD_BDC_FD_Byte2 9;
BA_ "Description" SG_ 2348810501 L_TP_L_WPC_FD_BDC_FD_Byte2 "TP Index : 272";
BA_ "GenSigSendType" SG_ 2348810501 L_TP_L_WPC_FD_BDC_FD_Byte20 2;
BA_ "Version" SG_ 2348810501 L_TP_L_WPC_FD_BDC_FD_Byte20 "23.01.02";
BA_ "NetworkRequestHoldingTime" SG_ 2348810501 L_TP_L_WPC_FD_BDC_FD_Byte20 5000;
BA_ "NetworkRequest" SG_ 2348810501 L_TP_L_WPC_FD_BDC_FD_Byte20 0;
BA_ "UserSigValidity" SG_ 2348810501 L_TP_L_WPC_FD_BDC_FD_Byte20 0;
BA_ "UsrSigPurpose" SG_ 2348810501 L_TP_L_WPC_FD_BDC_FD_Byte20 9;
BA_ "Description" SG_ 2348810501 L_TP_L_WPC_FD_BDC_FD_Byte20 "TP Index : 272";
BA_ "GenSigSendType" SG_ 2348810501 L_TP_L_WPC_FD_BDC_FD_Byte21 2;
BA_ "Version" SG_ 2348810501 L_TP_L_WPC_FD_BDC_FD_Byte21 "23.01.02";
BA_ "NetworkRequestHoldingTime" SG_ 2348810501 L_TP_L_WPC_FD_BDC_FD_Byte21 5000;
BA_ "NetworkRequest" SG_ 2348810501 L_TP_L_WPC_FD_BDC_FD_Byte21 0;
BA_ "UserSigValidity" SG_ 2348810501 L_TP_L_WPC_FD_BDC_FD_Byte21 0;
BA_ "UsrSigPurpose" SG_ 2348810501 L_TP_L_WPC_FD_BDC_FD_Byte21 9;
BA_ "Description" SG_ 2348810501 L_TP_L_WPC_FD_BDC_FD_Byte21 "TP Index : 272";
BA_ "GenSigSendType" SG_ 2348810501 L_TP_L_WPC_FD_BDC_FD_Byte22 2;
BA_ "Version" SG_ 2348810501 L_TP_L_WPC_FD_BDC_FD_Byte22 "23.01.02";
BA_ "NetworkRequestHoldingTime" SG_ 2348810501 L_TP_L_WPC_FD_BDC_FD_Byte22 5000;
BA_ "NetworkRequest" SG_ 2348810501 L_TP_L_WPC_FD_BDC_FD_Byte22 0;
BA_ "UserSigValidity" SG_ 2348810501 L_TP_L_WPC_FD_BDC_FD_Byte22 0;
BA_ "UsrSigPurpose" SG_ 2348810501 L_TP_L_WPC_FD_BDC_FD_Byte22 9;
BA_ "Description" SG_ 2348810501 L_TP_L_WPC_FD_BDC_FD_Byte22 "TP Index : 272";
BA_ "GenSigSendType" SG_ 2348810501 L_TP_L_WPC_FD_BDC_FD_Byte23 2;
BA_ "Version" SG_ 2348810501 L_TP_L_WPC_FD_BDC_FD_Byte23 "23.01.02";
BA_ "NetworkRequestHoldingTime" SG_ 2348810501 L_TP_L_WPC_FD_BDC_FD_Byte23 5000;
BA_ "NetworkRequest" SG_ 2348810501 L_TP_L_WPC_FD_BDC_FD_Byte23 0;
BA_ "UserSigValidity" SG_ 2348810501 L_TP_L_WPC_FD_BDC_FD_Byte23 0;
BA_ "UsrSigPurpose" SG_ 2348810501 L_TP_L_WPC_FD_BDC_FD_Byte23 9;
BA_ "Description" SG_ 2348810501 L_TP_L_WPC_FD_BDC_FD_Byte23 "TP Index : 272";
BA_ "GenSigSendType" SG_ 2348810501 L_TP_L_WPC_FD_BDC_FD_Byte24 2;
BA_ "Version" SG_ 2348810501 L_TP_L_WPC_FD_BDC_FD_Byte24 "23.01.02";
BA_ "NetworkRequestHoldingTime" SG_ 2348810501 L_TP_L_WPC_FD_BDC_FD_Byte24 5000;
BA_ "NetworkRequest" SG_ 2348810501 L_TP_L_WPC_FD_BDC_FD_Byte24 0;
BA_ "UserSigValidity" SG_ 2348810501 L_TP_L_WPC_FD_BDC_FD_Byte24 0;
BA_ "UsrSigPurpose" SG_ 2348810501 L_TP_L_WPC_FD_BDC_FD_Byte24 9;
BA_ "Description" SG_ 2348810501 L_TP_L_WPC_FD_BDC_FD_Byte24 "TP Index : 272";
BA_ "GenSigSendType" SG_ 2348810501 L_TP_L_WPC_FD_BDC_FD_Byte25 2;
BA_ "Version" SG_ 2348810501 L_TP_L_WPC_FD_BDC_FD_Byte25 "23.01.02";
BA_ "NetworkRequestHoldingTime" SG_ 2348810501 L_TP_L_WPC_FD_BDC_FD_Byte25 5000;
BA_ "NetworkRequest" SG_ 2348810501 L_TP_L_WPC_FD_BDC_FD_Byte25 0;
BA_ "UserSigValidity" SG_ 2348810501 L_TP_L_WPC_FD_BDC_FD_Byte25 0;
BA_ "UsrSigPurpose" SG_ 2348810501 L_TP_L_WPC_FD_BDC_FD_Byte25 9;
BA_ "Description" SG_ 2348810501 L_TP_L_WPC_FD_BDC_FD_Byte25 "TP Index : 272";
BA_ "GenSigSendType" SG_ 2348810501 L_TP_L_WPC_FD_BDC_FD_Byte26 2;
BA_ "Version" SG_ 2348810501 L_TP_L_WPC_FD_BDC_FD_Byte26 "23.01.02";
BA_ "NetworkRequestHoldingTime" SG_ 2348810501 L_TP_L_WPC_FD_BDC_FD_Byte26 5000;
BA_ "NetworkRequest" SG_ 2348810501 L_TP_L_WPC_FD_BDC_FD_Byte26 0;
BA_ "UserSigValidity" SG_ 2348810501 L_TP_L_WPC_FD_BDC_FD_Byte26 0;
BA_ "UsrSigPurpose" SG_ 2348810501 L_TP_L_WPC_FD_BDC_FD_Byte26 9;
BA_ "Description" SG_ 2348810501 L_TP_L_WPC_FD_BDC_FD_Byte26 "TP Index : 272";
BA_ "GenSigSendType" SG_ 2348810501 L_TP_L_WPC_FD_BDC_FD_Byte27 2;
BA_ "Version" SG_ 2348810501 L_TP_L_WPC_FD_BDC_FD_Byte27 "23.01.02";
BA_ "NetworkRequestHoldingTime" SG_ 2348810501 L_TP_L_WPC_FD_BDC_FD_Byte27 5000;
BA_ "NetworkRequest" SG_ 2348810501 L_TP_L_WPC_FD_BDC_FD_Byte27 0;
BA_ "UserSigValidity" SG_ 2348810501 L_TP_L_WPC_FD_BDC_FD_Byte27 0;
BA_ "UsrSigPurpose" SG_ 2348810501 L_TP_L_WPC_FD_BDC_FD_Byte27 9;
BA_ "Description" SG_ 2348810501 L_TP_L_WPC_FD_BDC_FD_Byte27 "TP Index : 272";
BA_ "GenSigSendType" SG_ 2348810501 L_TP_L_WPC_FD_BDC_FD_Byte28 2;
BA_ "Version" SG_ 2348810501 L_TP_L_WPC_FD_BDC_FD_Byte28 "23.01.02";
BA_ "NetworkRequestHoldingTime" SG_ 2348810501 L_TP_L_WPC_FD_BDC_FD_Byte28 5000;
BA_ "NetworkRequest" SG_ 2348810501 L_TP_L_WPC_FD_BDC_FD_Byte28 0;
BA_ "UserSigValidity" SG_ 2348810501 L_TP_L_WPC_FD_BDC_FD_Byte28 0;
BA_ "UsrSigPurpose" SG_ 2348810501 L_TP_L_WPC_FD_BDC_FD_Byte28 9;
BA_ "Description" SG_ 2348810501 L_TP_L_WPC_FD_BDC_FD_Byte28 "TP Index : 272";
BA_ "GenSigSendType" SG_ 2348810501 L_TP_L_WPC_FD_BDC_FD_Byte29 2;
BA_ "Version" SG_ 2348810501 L_TP_L_WPC_FD_BDC_FD_Byte29 "23.01.02";
BA_ "NetworkRequestHoldingTime" SG_ 2348810501 L_TP_L_WPC_FD_BDC_FD_Byte29 5000;
BA_ "NetworkRequest" SG_ 2348810501 L_TP_L_WPC_FD_BDC_FD_Byte29 0;
BA_ "UserSigValidity" SG_ 2348810501 L_TP_L_WPC_FD_BDC_FD_Byte29 0;
BA_ "UsrSigPurpose" SG_ 2348810501 L_TP_L_WPC_FD_BDC_FD_Byte29 9;
BA_ "Description" SG_ 2348810501 L_TP_L_WPC_FD_BDC_FD_Byte29 "TP Index : 272";
BA_ "GenSigSendType" SG_ 2348810501 L_TP_L_WPC_FD_BDC_FD_Byte3 2;
BA_ "Version" SG_ 2348810501 L_TP_L_WPC_FD_BDC_FD_Byte3 "23.01.02";
BA_ "NetworkRequestHoldingTime" SG_ 2348810501 L_TP_L_WPC_FD_BDC_FD_Byte3 5000;
BA_ "NetworkRequest" SG_ 2348810501 L_TP_L_WPC_FD_BDC_FD_Byte3 0;
BA_ "UserSigValidity" SG_ 2348810501 L_TP_L_WPC_FD_BDC_FD_Byte3 0;
BA_ "UsrSigPurpose" SG_ 2348810501 L_TP_L_WPC_FD_BDC_FD_Byte3 9;
BA_ "Description" SG_ 2348810501 L_TP_L_WPC_FD_BDC_FD_Byte3 "TP Index : 272";
BA_ "GenSigSendType" SG_ 2348810501 L_TP_L_WPC_FD_BDC_FD_Byte30 2;
BA_ "Version" SG_ 2348810501 L_TP_L_WPC_FD_BDC_FD_Byte30 "23.01.02";
BA_ "NetworkRequestHoldingTime" SG_ 2348810501 L_TP_L_WPC_FD_BDC_FD_Byte30 5000;
BA_ "NetworkRequest" SG_ 2348810501 L_TP_L_WPC_FD_BDC_FD_Byte30 0;
BA_ "UserSigValidity" SG_ 2348810501 L_TP_L_WPC_FD_BDC_FD_Byte30 0;
BA_ "UsrSigPurpose" SG_ 2348810501 L_TP_L_WPC_FD_BDC_FD_Byte30 9;
BA_ "Description" SG_ 2348810501 L_TP_L_WPC_FD_BDC_FD_Byte30 "TP Index : 272";
BA_ "GenSigSendType" SG_ 2348810501 L_TP_L_WPC_FD_BDC_FD_Byte31 2;
BA_ "Version" SG_ 2348810501 L_TP_L_WPC_FD_BDC_FD_Byte31 "23.01.02";
BA_ "NetworkRequestHoldingTime" SG_ 2348810501 L_TP_L_WPC_FD_BDC_FD_Byte31 5000;
BA_ "NetworkRequest" SG_ 2348810501 L_TP_L_WPC_FD_BDC_FD_Byte31 0;
BA_ "UserSigValidity" SG_ 2348810501 L_TP_L_WPC_FD_BDC_FD_Byte31 0;
BA_ "UsrSigPurpose" SG_ 2348810501 L_TP_L_WPC_FD_BDC_FD_Byte31 9;
BA_ "Description" SG_ 2348810501 L_TP_L_WPC_FD_BDC_FD_Byte31 "TP Index : 272";
BA_ "GenSigSendType" SG_ 2348810501 L_TP_L_WPC_FD_BDC_FD_Byte4 2;
BA_ "Version" SG_ 2348810501 L_TP_L_WPC_FD_BDC_FD_Byte4 "23.01.02";
BA_ "NetworkRequestHoldingTime" SG_ 2348810501 L_TP_L_WPC_FD_BDC_FD_Byte4 5000;
BA_ "NetworkRequest" SG_ 2348810501 L_TP_L_WPC_FD_BDC_FD_Byte4 0;
BA_ "UserSigValidity" SG_ 2348810501 L_TP_L_WPC_FD_BDC_FD_Byte4 0;
BA_ "UsrSigPurpose" SG_ 2348810501 L_TP_L_WPC_FD_BDC_FD_Byte4 9;
BA_ "Description" SG_ 2348810501 L_TP_L_WPC_FD_BDC_FD_Byte4 "TP Index : 272";
BA_ "GenSigSendType" SG_ 2348810501 L_TP_L_WPC_FD_BDC_FD_Byte5 2;
BA_ "Version" SG_ 2348810501 L_TP_L_WPC_FD_BDC_FD_Byte5 "23.01.02";
BA_ "NetworkRequestHoldingTime" SG_ 2348810501 L_TP_L_WPC_FD_BDC_FD_Byte5 5000;
BA_ "NetworkRequest" SG_ 2348810501 L_TP_L_WPC_FD_BDC_FD_Byte5 0;
BA_ "UserSigValidity" SG_ 2348810501 L_TP_L_WPC_FD_BDC_FD_Byte5 0;
BA_ "UsrSigPurpose" SG_ 2348810501 L_TP_L_WPC_FD_BDC_FD_Byte5 9;
BA_ "Description" SG_ 2348810501 L_TP_L_WPC_FD_BDC_FD_Byte5 "TP Index : 272";
BA_ "GenSigSendType" SG_ 2348810501 L_TP_L_WPC_FD_BDC_FD_Byte6 2;
BA_ "Version" SG_ 2348810501 L_TP_L_WPC_FD_BDC_FD_Byte6 "23.01.02";
BA_ "NetworkRequestHoldingTime" SG_ 2348810501 L_TP_L_WPC_FD_BDC_FD_Byte6 5000;
BA_ "NetworkRequest" SG_ 2348810501 L_TP_L_WPC_FD_BDC_FD_Byte6 0;
BA_ "UserSigValidity" SG_ 2348810501 L_TP_L_WPC_FD_BDC_FD_Byte6 0;
BA_ "UsrSigPurpose" SG_ 2348810501 L_TP_L_WPC_FD_BDC_FD_Byte6 9;
BA_ "Description" SG_ 2348810501 L_TP_L_WPC_FD_BDC_FD_Byte6 "TP Index : 272";
BA_ "GenSigSendType" SG_ 2348810501 L_TP_L_WPC_FD_BDC_FD_Byte7 2;
BA_ "Version" SG_ 2348810501 L_TP_L_WPC_FD_BDC_FD_Byte7 "23.01.02";
BA_ "NetworkRequestHoldingTime" SG_ 2348810501 L_TP_L_WPC_FD_BDC_FD_Byte7 5000;
BA_ "NetworkRequest" SG_ 2348810501 L_TP_L_WPC_FD_BDC_FD_Byte7 0;
BA_ "UserSigValidity" SG_ 2348810501 L_TP_L_WPC_FD_BDC_FD_Byte7 0;
BA_ "UsrSigPurpose" SG_ 2348810501 L_TP_L_WPC_FD_BDC_FD_Byte7 9;
BA_ "Description" SG_ 2348810501 L_TP_L_WPC_FD_BDC_FD_Byte7 "TP Index : 272";
BA_ "GenSigSendType" SG_ 2348810501 L_TP_L_WPC_FD_BDC_FD_Byte8 2;
BA_ "Version" SG_ 2348810501 L_TP_L_WPC_FD_BDC_FD_Byte8 "23.01.02";
BA_ "NetworkRequestHoldingTime" SG_ 2348810501 L_TP_L_WPC_FD_BDC_FD_Byte8 5000;
BA_ "NetworkRequest" SG_ 2348810501 L_TP_L_WPC_FD_BDC_FD_Byte8 0;
BA_ "UserSigValidity" SG_ 2348810501 L_TP_L_WPC_FD_BDC_FD_Byte8 0;
BA_ "UsrSigPurpose" SG_ 2348810501 L_TP_L_WPC_FD_BDC_FD_Byte8 9;
BA_ "Description" SG_ 2348810501 L_TP_L_WPC_FD_BDC_FD_Byte8 "TP Index : 272";
BA_ "GenSigSendType" SG_ 2348810501 L_TP_L_WPC_FD_BDC_FD_Byte9 2;
BA_ "Version" SG_ 2348810501 L_TP_L_WPC_FD_BDC_FD_Byte9 "23.01.02";
BA_ "NetworkRequestHoldingTime" SG_ 2348810501 L_TP_L_WPC_FD_BDC_FD_Byte9 5000;
BA_ "NetworkRequest" SG_ 2348810501 L_TP_L_WPC_FD_BDC_FD_Byte9 0;
BA_ "UserSigValidity" SG_ 2348810501 L_TP_L_WPC_FD_BDC_FD_Byte9 0;
BA_ "UsrSigPurpose" SG_ 2348810501 L_TP_L_WPC_FD_BDC_FD_Byte9 9;
BA_ "Description" SG_ 2348810501 L_TP_L_WPC_FD_BDC_FD_Byte9 "TP Index : 272";
BA_ "GenSigSendType" SG_ 2348810501 L_TP_L_WPC_FD_BDC_FD_Byte1 2;
BA_ "Version" SG_ 2348810501 L_TP_L_WPC_FD_BDC_FD_Byte1 "23.01.02";
BA_ "NetworkRequestHoldingTime" SG_ 2348810501 L_TP_L_WPC_FD_BDC_FD_Byte1 5000;
BA_ "NetworkRequest" SG_ 2348810501 L_TP_L_WPC_FD_BDC_FD_Byte1 0;
BA_ "UserSigValidity" SG_ 2348810501 L_TP_L_WPC_FD_BDC_FD_Byte1 0;
BA_ "UsrSigPurpose" SG_ 2348810501 L_TP_L_WPC_FD_BDC_FD_Byte1 9;
BA_ "Description" SG_ 2348810501 L_TP_L_WPC_FD_BDC_FD_Byte1 "TP Index : 272";
BA_ "GenSigSendType" SG_ 2348810501 L_TP_L_WPC_FD_BDC_FD_Byte10 2;
BA_ "Version" SG_ 2348810501 L_TP_L_WPC_FD_BDC_FD_Byte10 "23.01.02";
BA_ "NetworkRequestHoldingTime" SG_ 2348810501 L_TP_L_WPC_FD_BDC_FD_Byte10 5000;
BA_ "NetworkRequest" SG_ 2348810501 L_TP_L_WPC_FD_BDC_FD_Byte10 0;
BA_ "UserSigValidity" SG_ 2348810501 L_TP_L_WPC_FD_BDC_FD_Byte10 0;
BA_ "UsrSigPurpose" SG_ 2348810501 L_TP_L_WPC_FD_BDC_FD_Byte10 9;
BA_ "Description" SG_ 2348810501 L_TP_L_WPC_FD_BDC_FD_Byte10 "TP Index : 272";
BA_ "GenSigSendType" SG_ 2348810501 L_TP_L_WPC_FD_BDC_FD_Byte11 2;
BA_ "Version" SG_ 2348810501 L_TP_L_WPC_FD_BDC_FD_Byte11 "23.01.02";
BA_ "NetworkRequestHoldingTime" SG_ 2348810501 L_TP_L_WPC_FD_BDC_FD_Byte11 5000;
BA_ "NetworkRequest" SG_ 2348810501 L_TP_L_WPC_FD_BDC_FD_Byte11 0;
BA_ "UserSigValidity" SG_ 2348810501 L_TP_L_WPC_FD_BDC_FD_Byte11 0;
BA_ "UsrSigPurpose" SG_ 2348810501 L_TP_L_WPC_FD_BDC_FD_Byte11 9;
BA_ "Description" SG_ 2348810501 L_TP_L_WPC_FD_BDC_FD_Byte11 "TP Index : 272";
BA_ "GenSigSendType" SG_ 2348810501 L_TP_L_WPC_FD_BDC_FD_Byte12 2;
BA_ "Version" SG_ 2348810501 L_TP_L_WPC_FD_BDC_FD_Byte12 "23.01.02";
BA_ "NetworkRequestHoldingTime" SG_ 2348810501 L_TP_L_WPC_FD_BDC_FD_Byte12 5000;
BA_ "NetworkRequest" SG_ 2348810501 L_TP_L_WPC_FD_BDC_FD_Byte12 0;
BA_ "UserSigValidity" SG_ 2348810501 L_TP_L_WPC_FD_BDC_FD_Byte12 0;
BA_ "UsrSigPurpose" SG_ 2348810501 L_TP_L_WPC_FD_BDC_FD_Byte12 9;
BA_ "Description" SG_ 2348810501 L_TP_L_WPC_FD_BDC_FD_Byte12 "TP Index : 272";
BA_ "Version" SG_ 2348810500 L_TP_BDC_FD_L_WPC_FD_Byte0 "23.01.02";
BA_ "NetworkRequestHoldingTime" SG_ 2348810500 L_TP_BDC_FD_L_WPC_FD_Byte0 5000;
BA_ "NetworkRequest" SG_ 2348810500 L_TP_BDC_FD_L_WPC_FD_Byte0 0;
BA_ "UserSigValidity" SG_ 2348810500 L_TP_BDC_FD_L_WPC_FD_Byte0 0;
BA_ "UsrSigPurpose" SG_ 2348810500 L_TP_BDC_FD_L_WPC_FD_Byte0 9;
BA_ "Description" SG_ 2348810500 L_TP_BDC_FD_L_WPC_FD_Byte0 "TP Index : 272";
BA_ "Version" SG_ 2348810500 L_TP_BDC_FD_L_WPC_FD_Byte13 "23.01.02";
BA_ "NetworkRequestHoldingTime" SG_ 2348810500 L_TP_BDC_FD_L_WPC_FD_Byte13 5000;
BA_ "NetworkRequest" SG_ 2348810500 L_TP_BDC_FD_L_WPC_FD_Byte13 0;
BA_ "UserSigValidity" SG_ 2348810500 L_TP_BDC_FD_L_WPC_FD_Byte13 0;
BA_ "UsrSigPurpose" SG_ 2348810500 L_TP_BDC_FD_L_WPC_FD_Byte13 9;
BA_ "Description" SG_ 2348810500 L_TP_BDC_FD_L_WPC_FD_Byte13 "TP Index : 272";
BA_ "Version" SG_ 2348810500 L_TP_BDC_FD_L_WPC_FD_Byte14 "23.01.02";
BA_ "NetworkRequestHoldingTime" SG_ 2348810500 L_TP_BDC_FD_L_WPC_FD_Byte14 5000;
BA_ "NetworkRequest" SG_ 2348810500 L_TP_BDC_FD_L_WPC_FD_Byte14 0;
BA_ "UserSigValidity" SG_ 2348810500 L_TP_BDC_FD_L_WPC_FD_Byte14 0;
BA_ "UsrSigPurpose" SG_ 2348810500 L_TP_BDC_FD_L_WPC_FD_Byte14 9;
BA_ "Description" SG_ 2348810500 L_TP_BDC_FD_L_WPC_FD_Byte14 "TP Index : 272";
BA_ "Version" SG_ 2348810500 L_TP_BDC_FD_L_WPC_FD_Byte15 "23.01.02";
BA_ "NetworkRequestHoldingTime" SG_ 2348810500 L_TP_BDC_FD_L_WPC_FD_Byte15 5000;
BA_ "NetworkRequest" SG_ 2348810500 L_TP_BDC_FD_L_WPC_FD_Byte15 0;
BA_ "UserSigValidity" SG_ 2348810500 L_TP_BDC_FD_L_WPC_FD_Byte15 0;
BA_ "UsrSigPurpose" SG_ 2348810500 L_TP_BDC_FD_L_WPC_FD_Byte15 9;
BA_ "Description" SG_ 2348810500 L_TP_BDC_FD_L_WPC_FD_Byte15 "TP Index : 272";
BA_ "Version" SG_ 2348810500 L_TP_BDC_FD_L_WPC_FD_Byte16 "23.01.02";
BA_ "NetworkRequestHoldingTime" SG_ 2348810500 L_TP_BDC_FD_L_WPC_FD_Byte16 5000;
BA_ "NetworkRequest" SG_ 2348810500 L_TP_BDC_FD_L_WPC_FD_Byte16 0;
BA_ "UserSigValidity" SG_ 2348810500 L_TP_BDC_FD_L_WPC_FD_Byte16 0;
BA_ "UsrSigPurpose" SG_ 2348810500 L_TP_BDC_FD_L_WPC_FD_Byte16 9;
BA_ "Description" SG_ 2348810500 L_TP_BDC_FD_L_WPC_FD_Byte16 "TP Index : 272";
BA_ "Version" SG_ 2348810500 L_TP_BDC_FD_L_WPC_FD_Byte17 "23.01.02";
BA_ "NetworkRequestHoldingTime" SG_ 2348810500 L_TP_BDC_FD_L_WPC_FD_Byte17 5000;
BA_ "NetworkRequest" SG_ 2348810500 L_TP_BDC_FD_L_WPC_FD_Byte17 0;
BA_ "UserSigValidity" SG_ 2348810500 L_TP_BDC_FD_L_WPC_FD_Byte17 0;
BA_ "UsrSigPurpose" SG_ 2348810500 L_TP_BDC_FD_L_WPC_FD_Byte17 9;
BA_ "Description" SG_ 2348810500 L_TP_BDC_FD_L_WPC_FD_Byte17 "TP Index : 272";
BA_ "Version" SG_ 2348810500 L_TP_BDC_FD_L_WPC_FD_Byte18 "23.01.02";
BA_ "NetworkRequestHoldingTime" SG_ 2348810500 L_TP_BDC_FD_L_WPC_FD_Byte18 5000;
BA_ "NetworkRequest" SG_ 2348810500 L_TP_BDC_FD_L_WPC_FD_Byte18 0;
BA_ "UserSigValidity" SG_ 2348810500 L_TP_BDC_FD_L_WPC_FD_Byte18 0;
BA_ "UsrSigPurpose" SG_ 2348810500 L_TP_BDC_FD_L_WPC_FD_Byte18 9;
BA_ "Description" SG_ 2348810500 L_TP_BDC_FD_L_WPC_FD_Byte18 "TP Index : 272";
BA_ "Version" SG_ 2348810500 L_TP_BDC_FD_L_WPC_FD_Byte19 "23.01.02";
BA_ "NetworkRequestHoldingTime" SG_ 2348810500 L_TP_BDC_FD_L_WPC_FD_Byte19 5000;
BA_ "NetworkRequest" SG_ 2348810500 L_TP_BDC_FD_L_WPC_FD_Byte19 0;
BA_ "UserSigValidity" SG_ 2348810500 L_TP_BDC_FD_L_WPC_FD_Byte19 0;
BA_ "UsrSigPurpose" SG_ 2348810500 L_TP_BDC_FD_L_WPC_FD_Byte19 9;
BA_ "Description" SG_ 2348810500 L_TP_BDC_FD_L_WPC_FD_Byte19 "TP Index : 272";
BA_ "Version" SG_ 2348810500 L_TP_BDC_FD_L_WPC_FD_Byte2 "23.01.02";
BA_ "NetworkRequestHoldingTime" SG_ 2348810500 L_TP_BDC_FD_L_WPC_FD_Byte2 5000;
BA_ "NetworkRequest" SG_ 2348810500 L_TP_BDC_FD_L_WPC_FD_Byte2 0;
BA_ "UserSigValidity" SG_ 2348810500 L_TP_BDC_FD_L_WPC_FD_Byte2 0;
BA_ "UsrSigPurpose" SG_ 2348810500 L_TP_BDC_FD_L_WPC_FD_Byte2 9;
BA_ "Description" SG_ 2348810500 L_TP_BDC_FD_L_WPC_FD_Byte2 "TP Index : 272";
BA_ "Version" SG_ 2348810500 L_TP_BDC_FD_L_WPC_FD_Byte20 "23.01.02";
BA_ "NetworkRequestHoldingTime" SG_ 2348810500 L_TP_BDC_FD_L_WPC_FD_Byte20 5000;
BA_ "NetworkRequest" SG_ 2348810500 L_TP_BDC_FD_L_WPC_FD_Byte20 0;
BA_ "UserSigValidity" SG_ 2348810500 L_TP_BDC_FD_L_WPC_FD_Byte20 0;
BA_ "UsrSigPurpose" SG_ 2348810500 L_TP_BDC_FD_L_WPC_FD_Byte20 9;
BA_ "Description" SG_ 2348810500 L_TP_BDC_FD_L_WPC_FD_Byte20 "TP Index : 272";
BA_ "Version" SG_ 2348810500 L_TP_BDC_FD_L_WPC_FD_Byte21 "23.01.02";
BA_ "NetworkRequestHoldingTime" SG_ 2348810500 L_TP_BDC_FD_L_WPC_FD_Byte21 5000;
BA_ "NetworkRequest" SG_ 2348810500 L_TP_BDC_FD_L_WPC_FD_Byte21 0;
BA_ "UserSigValidity" SG_ 2348810500 L_TP_BDC_FD_L_WPC_FD_Byte21 0;
BA_ "UsrSigPurpose" SG_ 2348810500 L_TP_BDC_FD_L_WPC_FD_Byte21 9;
BA_ "Description" SG_ 2348810500 L_TP_BDC_FD_L_WPC_FD_Byte21 "TP Index : 272";
BA_ "Version" SG_ 2348810500 L_TP_BDC_FD_L_WPC_FD_Byte22 "23.01.02";
BA_ "NetworkRequestHoldingTime" SG_ 2348810500 L_TP_BDC_FD_L_WPC_FD_Byte22 5000;
BA_ "NetworkRequest" SG_ 2348810500 L_TP_BDC_FD_L_WPC_FD_Byte22 0;
BA_ "UserSigValidity" SG_ 2348810500 L_TP_BDC_FD_L_WPC_FD_Byte22 0;
BA_ "UsrSigPurpose" SG_ 2348810500 L_TP_BDC_FD_L_WPC_FD_Byte22 9;
BA_ "Description" SG_ 2348810500 L_TP_BDC_FD_L_WPC_FD_Byte22 "TP Index : 272";
BA_ "Version" SG_ 2348810500 L_TP_BDC_FD_L_WPC_FD_Byte23 "23.01.02";
BA_ "NetworkRequestHoldingTime" SG_ 2348810500 L_TP_BDC_FD_L_WPC_FD_Byte23 5000;
BA_ "NetworkRequest" SG_ 2348810500 L_TP_BDC_FD_L_WPC_FD_Byte23 0;
BA_ "UserSigValidity" SG_ 2348810500 L_TP_BDC_FD_L_WPC_FD_Byte23 0;
BA_ "UsrSigPurpose" SG_ 2348810500 L_TP_BDC_FD_L_WPC_FD_Byte23 9;
BA_ "Description" SG_ 2348810500 L_TP_BDC_FD_L_WPC_FD_Byte23 "TP Index : 272";
BA_ "Version" SG_ 2348810500 L_TP_BDC_FD_L_WPC_FD_Byte24 "23.01.02";
BA_ "NetworkRequestHoldingTime" SG_ 2348810500 L_TP_BDC_FD_L_WPC_FD_Byte24 5000;
BA_ "NetworkRequest" SG_ 2348810500 L_TP_BDC_FD_L_WPC_FD_Byte24 0;
BA_ "UserSigValidity" SG_ 2348810500 L_TP_BDC_FD_L_WPC_FD_Byte24 0;
BA_ "UsrSigPurpose" SG_ 2348810500 L_TP_BDC_FD_L_WPC_FD_Byte24 9;
BA_ "Description" SG_ 2348810500 L_TP_BDC_FD_L_WPC_FD_Byte24 "TP Index : 272";
BA_ "Version" SG_ 2348810500 L_TP_BDC_FD_L_WPC_FD_Byte25 "23.01.02";
BA_ "NetworkRequestHoldingTime" SG_ 2348810500 L_TP_BDC_FD_L_WPC_FD_Byte25 5000;
BA_ "NetworkRequest" SG_ 2348810500 L_TP_BDC_FD_L_WPC_FD_Byte25 0;
BA_ "UserSigValidity" SG_ 2348810500 L_TP_BDC_FD_L_WPC_FD_Byte25 0;
BA_ "UsrSigPurpose" SG_ 2348810500 L_TP_BDC_FD_L_WPC_FD_Byte25 9;
BA_ "Description" SG_ 2348810500 L_TP_BDC_FD_L_WPC_FD_Byte25 "TP Index : 272";
BA_ "Version" SG_ 2348810500 L_TP_BDC_FD_L_WPC_FD_Byte26 "23.01.02";
BA_ "NetworkRequestHoldingTime" SG_ 2348810500 L_TP_BDC_FD_L_WPC_FD_Byte26 5000;
BA_ "NetworkRequest" SG_ 2348810500 L_TP_BDC_FD_L_WPC_FD_Byte26 0;
BA_ "UserSigValidity" SG_ 2348810500 L_TP_BDC_FD_L_WPC_FD_Byte26 0;
BA_ "UsrSigPurpose" SG_ 2348810500 L_TP_BDC_FD_L_WPC_FD_Byte26 9;
BA_ "Description" SG_ 2348810500 L_TP_BDC_FD_L_WPC_FD_Byte26 "TP Index : 272";
BA_ "Version" SG_ 2348810500 L_TP_BDC_FD_L_WPC_FD_Byte27 "23.01.02";
BA_ "NetworkRequestHoldingTime" SG_ 2348810500 L_TP_BDC_FD_L_WPC_FD_Byte27 5000;
BA_ "NetworkRequest" SG_ 2348810500 L_TP_BDC_FD_L_WPC_FD_Byte27 0;
BA_ "UserSigValidity" SG_ 2348810500 L_TP_BDC_FD_L_WPC_FD_Byte27 0;
BA_ "UsrSigPurpose" SG_ 2348810500 L_TP_BDC_FD_L_WPC_FD_Byte27 9;
BA_ "Description" SG_ 2348810500 L_TP_BDC_FD_L_WPC_FD_Byte27 "TP Index : 272";
BA_ "Version" SG_ 2348810500 L_TP_BDC_FD_L_WPC_FD_Byte28 "23.01.02";
BA_ "NetworkRequestHoldingTime" SG_ 2348810500 L_TP_BDC_FD_L_WPC_FD_Byte28 5000;
BA_ "NetworkRequest" SG_ 2348810500 L_TP_BDC_FD_L_WPC_FD_Byte28 0;
BA_ "UserSigValidity" SG_ 2348810500 L_TP_BDC_FD_L_WPC_FD_Byte28 0;
BA_ "UsrSigPurpose" SG_ 2348810500 L_TP_BDC_FD_L_WPC_FD_Byte28 9;
BA_ "Description" SG_ 2348810500 L_TP_BDC_FD_L_WPC_FD_Byte28 "TP Index : 272";
BA_ "Version" SG_ 2348810500 L_TP_BDC_FD_L_WPC_FD_Byte29 "23.01.02";
BA_ "NetworkRequestHoldingTime" SG_ 2348810500 L_TP_BDC_FD_L_WPC_FD_Byte29 5000;
BA_ "NetworkRequest" SG_ 2348810500 L_TP_BDC_FD_L_WPC_FD_Byte29 0;
BA_ "UserSigValidity" SG_ 2348810500 L_TP_BDC_FD_L_WPC_FD_Byte29 0;
BA_ "UsrSigPurpose" SG_ 2348810500 L_TP_BDC_FD_L_WPC_FD_Byte29 9;
BA_ "Description" SG_ 2348810500 L_TP_BDC_FD_L_WPC_FD_Byte29 "TP Index : 272";
BA_ "Version" SG_ 2348810500 L_TP_BDC_FD_L_WPC_FD_Byte3 "23.01.02";
BA_ "NetworkRequestHoldingTime" SG_ 2348810500 L_TP_BDC_FD_L_WPC_FD_Byte3 5000;
BA_ "NetworkRequest" SG_ 2348810500 L_TP_BDC_FD_L_WPC_FD_Byte3 0;
BA_ "UserSigValidity" SG_ 2348810500 L_TP_BDC_FD_L_WPC_FD_Byte3 0;
BA_ "UsrSigPurpose" SG_ 2348810500 L_TP_BDC_FD_L_WPC_FD_Byte3 9;
BA_ "Description" SG_ 2348810500 L_TP_BDC_FD_L_WPC_FD_Byte3 "TP Index : 272";
BA_ "Version" SG_ 2348810500 L_TP_BDC_FD_L_WPC_FD_Byte30 "23.01.02";
BA_ "NetworkRequestHoldingTime" SG_ 2348810500 L_TP_BDC_FD_L_WPC_FD_Byte30 5000;
BA_ "NetworkRequest" SG_ 2348810500 L_TP_BDC_FD_L_WPC_FD_Byte30 0;
BA_ "UserSigValidity" SG_ 2348810500 L_TP_BDC_FD_L_WPC_FD_Byte30 0;
BA_ "UsrSigPurpose" SG_ 2348810500 L_TP_BDC_FD_L_WPC_FD_Byte30 9;
BA_ "Description" SG_ 2348810500 L_TP_BDC_FD_L_WPC_FD_Byte30 "TP Index : 272";
BA_ "Version" SG_ 2348810500 L_TP_BDC_FD_L_WPC_FD_Byte31 "23.01.02";
BA_ "NetworkRequestHoldingTime" SG_ 2348810500 L_TP_BDC_FD_L_WPC_FD_Byte31 5000;
BA_ "NetworkRequest" SG_ 2348810500 L_TP_BDC_FD_L_WPC_FD_Byte31 0;
BA_ "UserSigValidity" SG_ 2348810500 L_TP_BDC_FD_L_WPC_FD_Byte31 0;
BA_ "UsrSigPurpose" SG_ 2348810500 L_TP_BDC_FD_L_WPC_FD_Byte31 9;
BA_ "Description" SG_ 2348810500 L_TP_BDC_FD_L_WPC_FD_Byte31 "TP Index : 272";
BA_ "Version" SG_ 2348810500 L_TP_BDC_FD_L_WPC_FD_Byte4 "23.01.02";
BA_ "NetworkRequestHoldingTime" SG_ 2348810500 L_TP_BDC_FD_L_WPC_FD_Byte4 5000;
BA_ "NetworkRequest" SG_ 2348810500 L_TP_BDC_FD_L_WPC_FD_Byte4 0;
BA_ "UserSigValidity" SG_ 2348810500 L_TP_BDC_FD_L_WPC_FD_Byte4 0;
BA_ "UsrSigPurpose" SG_ 2348810500 L_TP_BDC_FD_L_WPC_FD_Byte4 9;
BA_ "Description" SG_ 2348810500 L_TP_BDC_FD_L_WPC_FD_Byte4 "TP Index : 272";
BA_ "Version" SG_ 2348810500 L_TP_BDC_FD_L_WPC_FD_Byte5 "23.01.02";
BA_ "NetworkRequestHoldingTime" SG_ 2348810500 L_TP_BDC_FD_L_WPC_FD_Byte5 5000;
BA_ "NetworkRequest" SG_ 2348810500 L_TP_BDC_FD_L_WPC_FD_Byte5 0;
BA_ "UserSigValidity" SG_ 2348810500 L_TP_BDC_FD_L_WPC_FD_Byte5 0;
BA_ "UsrSigPurpose" SG_ 2348810500 L_TP_BDC_FD_L_WPC_FD_Byte5 9;
BA_ "Description" SG_ 2348810500 L_TP_BDC_FD_L_WPC_FD_Byte5 "TP Index : 272";
BA_ "Version" SG_ 2348810500 L_TP_BDC_FD_L_WPC_FD_Byte6 "23.01.02";
BA_ "NetworkRequestHoldingTime" SG_ 2348810500 L_TP_BDC_FD_L_WPC_FD_Byte6 5000;
BA_ "NetworkRequest" SG_ 2348810500 L_TP_BDC_FD_L_WPC_FD_Byte6 0;
BA_ "UserSigValidity" SG_ 2348810500 L_TP_BDC_FD_L_WPC_FD_Byte6 0;
BA_ "UsrSigPurpose" SG_ 2348810500 L_TP_BDC_FD_L_WPC_FD_Byte6 9;
BA_ "Description" SG_ 2348810500 L_TP_BDC_FD_L_WPC_FD_Byte6 "TP Index : 272";
BA_ "Version" SG_ 2348810500 L_TP_BDC_FD_L_WPC_FD_Byte7 "23.01.02";
BA_ "NetworkRequestHoldingTime" SG_ 2348810500 L_TP_BDC_FD_L_WPC_FD_Byte7 5000;
BA_ "NetworkRequest" SG_ 2348810500 L_TP_BDC_FD_L_WPC_FD_Byte7 0;
BA_ "UserSigValidity" SG_ 2348810500 L_TP_BDC_FD_L_WPC_FD_Byte7 0;
BA_ "UsrSigPurpose" SG_ 2348810500 L_TP_BDC_FD_L_WPC_FD_Byte7 9;
BA_ "Description" SG_ 2348810500 L_TP_BDC_FD_L_WPC_FD_Byte7 "TP Index : 272";
BA_ "Version" SG_ 2348810500 L_TP_BDC_FD_L_WPC_FD_Byte8 "23.01.02";
BA_ "NetworkRequestHoldingTime" SG_ 2348810500 L_TP_BDC_FD_L_WPC_FD_Byte8 5000;
BA_ "NetworkRequest" SG_ 2348810500 L_TP_BDC_FD_L_WPC_FD_Byte8 0;
BA_ "UserSigValidity" SG_ 2348810500 L_TP_BDC_FD_L_WPC_FD_Byte8 0;
BA_ "UsrSigPurpose" SG_ 2348810500 L_TP_BDC_FD_L_WPC_FD_Byte8 9;
BA_ "Description" SG_ 2348810500 L_TP_BDC_FD_L_WPC_FD_Byte8 "TP Index : 272";
BA_ "Version" SG_ 2348810500 L_TP_BDC_FD_L_WPC_FD_Byte9 "23.01.02";
BA_ "NetworkRequestHoldingTime" SG_ 2348810500 L_TP_BDC_FD_L_WPC_FD_Byte9 5000;
BA_ "NetworkRequest" SG_ 2348810500 L_TP_BDC_FD_L_WPC_FD_Byte9 0;
BA_ "UserSigValidity" SG_ 2348810500 L_TP_BDC_FD_L_WPC_FD_Byte9 0;
BA_ "UsrSigPurpose" SG_ 2348810500 L_TP_BDC_FD_L_WPC_FD_Byte9 9;
BA_ "Description" SG_ 2348810500 L_TP_BDC_FD_L_WPC_FD_Byte9 "TP Index : 272";
BA_ "Version" SG_ 2348810500 L_TP_BDC_FD_L_WPC_FD_Byte1 "23.01.02";
BA_ "NetworkRequestHoldingTime" SG_ 2348810500 L_TP_BDC_FD_L_WPC_FD_Byte1 5000;
BA_ "NetworkRequest" SG_ 2348810500 L_TP_BDC_FD_L_WPC_FD_Byte1 0;
BA_ "UserSigValidity" SG_ 2348810500 L_TP_BDC_FD_L_WPC_FD_Byte1 0;
BA_ "UsrSigPurpose" SG_ 2348810500 L_TP_BDC_FD_L_WPC_FD_Byte1 9;
BA_ "Description" SG_ 2348810500 L_TP_BDC_FD_L_WPC_FD_Byte1 "TP Index : 272";
BA_ "Version" SG_ 2348810500 L_TP_BDC_FD_L_WPC_FD_Byte10 "23.01.02";
BA_ "NetworkRequestHoldingTime" SG_ 2348810500 L_TP_BDC_FD_L_WPC_FD_Byte10 5000;
BA_ "NetworkRequest" SG_ 2348810500 L_TP_BDC_FD_L_WPC_FD_Byte10 0;
BA_ "UserSigValidity" SG_ 2348810500 L_TP_BDC_FD_L_WPC_FD_Byte10 0;
BA_ "UsrSigPurpose" SG_ 2348810500 L_TP_BDC_FD_L_WPC_FD_Byte10 9;
BA_ "Description" SG_ 2348810500 L_TP_BDC_FD_L_WPC_FD_Byte10 "TP Index : 272";
BA_ "Version" SG_ 2348810500 L_TP_BDC_FD_L_WPC_FD_Byte11 "23.01.02";
BA_ "NetworkRequestHoldingTime" SG_ 2348810500 L_TP_BDC_FD_L_WPC_FD_Byte11 5000;
BA_ "NetworkRequest" SG_ 2348810500 L_TP_BDC_FD_L_WPC_FD_Byte11 0;
BA_ "UserSigValidity" SG_ 2348810500 L_TP_BDC_FD_L_WPC_FD_Byte11 0;
BA_ "UsrSigPurpose" SG_ 2348810500 L_TP_BDC_FD_L_WPC_FD_Byte11 9;
BA_ "Description" SG_ 2348810500 L_TP_BDC_FD_L_WPC_FD_Byte11 "TP Index : 272";
BA_ "Version" SG_ 2348810500 L_TP_BDC_FD_L_WPC_FD_Byte12 "23.01.02";
BA_ "NetworkRequestHoldingTime" SG_ 2348810500 L_TP_BDC_FD_L_WPC_FD_Byte12 5000;
BA_ "NetworkRequest" SG_ 2348810500 L_TP_BDC_FD_L_WPC_FD_Byte12 0;
BA_ "UserSigValidity" SG_ 2348810500 L_TP_BDC_FD_L_WPC_FD_Byte12 0;
BA_ "UsrSigPurpose" SG_ 2348810500 L_TP_BDC_FD_L_WPC_FD_Byte12 9;
BA_ "Description" SG_ 2348810500 L_TP_BDC_FD_L_WPC_FD_Byte12 "TP Index : 272";
BA_ "Version" SG_ 2214592656 L_DHR_FD_Crc1Val "23.01.02";
BA_ "UserSigValidity" SG_ 2214592656 L_DHR_FD_Crc1Val 3;
BA_ "GenSigStartValue" SG_ 2214592656 L_DHR_FD_Crc1Val 65535;
BA_ "GenSigSendType" SG_ 2214592656 L_DHR_FD_Crc1Val 4;
BA_ "Description" SG_ 2214592656 L_DHR_FD_Crc1Val "The data area for CRC calculation is based on the data length (DLC) of the message DB.

The CRC shall be calculated over the entire data block (excluding the CRC bytes) including the user data, alive counter and Data ID



- CRC Polynomial (0x1021) , Ini";
BA_ "Version" SG_ 2214592656 L_DHR_FD_AlvCnt1Val "23.01.02";
BA_ "UserSigValidity" SG_ 2214592656 L_DHR_FD_AlvCnt1Val 3;
BA_ "GenSigSendType" SG_ 2214592656 L_DHR_FD_AlvCnt1Val 4;
BA_ "Description" SG_ 2214592656 L_DHR_FD_AlvCnt1Val "For the first transmission request for a data element the counter shall be initialized with 0 and shall be incremented by 1 for every subsequent send request. 

When the counter reaches the maximum value(0xFF), then it shall restart with 0 for the next s";
BA_ "Version" SG_ 2214592656 DHR_NFCDetected "23.01.02";
BA_ "UserSigValidity" SG_ 2214592656 DHR_NFCDetected 0;
BA_ "GenSigSendType" SG_ 2214592656 DHR_NFCDetected 4;
BA_ "Version" SG_ 2214592656 DHR_WlcmLt_Sta "23.01.02";
BA_ "UserSigValidity" SG_ 2214592656 DHR_WlcmLt_Sta 0;
BA_ "GenSigSendType" SG_ 2214592656 DHR_WlcmLt_Sta 4;
BA_ "Version" SG_ 2214592656 DHR_NFCReset_Sta "23.01.02";
BA_ "UserSigValidity" SG_ 2214592656 DHR_NFCReset_Sta 0;
BA_ "GenSigSendType" SG_ 2214592656 DHR_NFCReset_Sta 4;
BA_ "Version" SG_ 2348810499 L_TP_L_UWB_BLE_SLV_FD_BDC_FD_Byt "23.01.02";
BA_ "NetworkRequestHoldingTime" SG_ 2348810499 L_TP_L_UWB_BLE_SLV_FD_BDC_FD_Byt 5000;
BA_ "NetworkRequest" SG_ 2348810499 L_TP_L_UWB_BLE_SLV_FD_BDC_FD_Byt 0;
BA_ "UserSigValidity" SG_ 2348810499 L_TP_L_UWB_BLE_SLV_FD_BDC_FD_Byt 0;
BA_ "UsrSigPurpose" SG_ 2348810499 L_TP_L_UWB_BLE_SLV_FD_BDC_FD_Byt 9;
BA_ "Description" SG_ 2348810499 L_TP_L_UWB_BLE_SLV_FD_BDC_FD_Byt "TP Index : 271";
BA_ "SystemSignalLongSymbol" SG_ 2348810499 L_TP_L_UWB_BLE_SLV_FD_BDC_FD_Byt "L_TP_L_UWB_BLE_SLV_FD_BDC_FD_Byte0";
BA_ "Version" SG_ 2348810499 L_TP_L_UWB_BLE_SLV_FD_BDC_F_0000 "23.01.02";
BA_ "NetworkRequestHoldingTime" SG_ 2348810499 L_TP_L_UWB_BLE_SLV_FD_BDC_F_0000 5000;
BA_ "NetworkRequest" SG_ 2348810499 L_TP_L_UWB_BLE_SLV_FD_BDC_F_0000 0;
BA_ "UserSigValidity" SG_ 2348810499 L_TP_L_UWB_BLE_SLV_FD_BDC_F_0000 0;
BA_ "UsrSigPurpose" SG_ 2348810499 L_TP_L_UWB_BLE_SLV_FD_BDC_F_0000 9;
BA_ "Description" SG_ 2348810499 L_TP_L_UWB_BLE_SLV_FD_BDC_F_0000 "TP Index : 271";
BA_ "SystemSignalLongSymbol" SG_ 2348810499 L_TP_L_UWB_BLE_SLV_FD_BDC_F_0000 "L_TP_L_UWB_BLE_SLV_FD_BDC_FD_Byte13";
BA_ "Version" SG_ 2348810499 L_TP_L_UWB_BLE_SLV_FD_BDC_F_0001 "23.01.02";
BA_ "NetworkRequestHoldingTime" SG_ 2348810499 L_TP_L_UWB_BLE_SLV_FD_BDC_F_0001 5000;
BA_ "NetworkRequest" SG_ 2348810499 L_TP_L_UWB_BLE_SLV_FD_BDC_F_0001 0;
BA_ "UserSigValidity" SG_ 2348810499 L_TP_L_UWB_BLE_SLV_FD_BDC_F_0001 0;
BA_ "UsrSigPurpose" SG_ 2348810499 L_TP_L_UWB_BLE_SLV_FD_BDC_F_0001 9;
BA_ "Description" SG_ 2348810499 L_TP_L_UWB_BLE_SLV_FD_BDC_F_0001 "TP Index : 271";
BA_ "SystemSignalLongSymbol" SG_ 2348810499 L_TP_L_UWB_BLE_SLV_FD_BDC_F_0001 "L_TP_L_UWB_BLE_SLV_FD_BDC_FD_Byte14";
BA_ "Version" SG_ 2348810499 L_TP_L_UWB_BLE_SLV_FD_BDC_F_0002 "23.01.02";
BA_ "NetworkRequestHoldingTime" SG_ 2348810499 L_TP_L_UWB_BLE_SLV_FD_BDC_F_0002 5000;
BA_ "NetworkRequest" SG_ 2348810499 L_TP_L_UWB_BLE_SLV_FD_BDC_F_0002 0;
BA_ "UserSigValidity" SG_ 2348810499 L_TP_L_UWB_BLE_SLV_FD_BDC_F_0002 0;
BA_ "UsrSigPurpose" SG_ 2348810499 L_TP_L_UWB_BLE_SLV_FD_BDC_F_0002 9;
BA_ "Description" SG_ 2348810499 L_TP_L_UWB_BLE_SLV_FD_BDC_F_0002 "TP Index : 271";
BA_ "SystemSignalLongSymbol" SG_ 2348810499 L_TP_L_UWB_BLE_SLV_FD_BDC_F_0002 "L_TP_L_UWB_BLE_SLV_FD_BDC_FD_Byte15";
BA_ "Version" SG_ 2348810499 L_TP_L_UWB_BLE_SLV_FD_BDC_F_0003 "23.01.02";
BA_ "NetworkRequestHoldingTime" SG_ 2348810499 L_TP_L_UWB_BLE_SLV_FD_BDC_F_0003 5000;
BA_ "NetworkRequest" SG_ 2348810499 L_TP_L_UWB_BLE_SLV_FD_BDC_F_0003 0;
BA_ "UserSigValidity" SG_ 2348810499 L_TP_L_UWB_BLE_SLV_FD_BDC_F_0003 0;
BA_ "UsrSigPurpose" SG_ 2348810499 L_TP_L_UWB_BLE_SLV_FD_BDC_F_0003 9;
BA_ "Description" SG_ 2348810499 L_TP_L_UWB_BLE_SLV_FD_BDC_F_0003 "TP Index : 271";
BA_ "SystemSignalLongSymbol" SG_ 2348810499 L_TP_L_UWB_BLE_SLV_FD_BDC_F_0003 "L_TP_L_UWB_BLE_SLV_FD_BDC_FD_Byte16";
BA_ "Version" SG_ 2348810499 L_TP_L_UWB_BLE_SLV_FD_BDC_F_0004 "23.01.02";
BA_ "NetworkRequestHoldingTime" SG_ 2348810499 L_TP_L_UWB_BLE_SLV_FD_BDC_F_0004 5000;
BA_ "NetworkRequest" SG_ 2348810499 L_TP_L_UWB_BLE_SLV_FD_BDC_F_0004 0;
BA_ "UserSigValidity" SG_ 2348810499 L_TP_L_UWB_BLE_SLV_FD_BDC_F_0004 0;
BA_ "UsrSigPurpose" SG_ 2348810499 L_TP_L_UWB_BLE_SLV_FD_BDC_F_0004 9;
BA_ "Description" SG_ 2348810499 L_TP_L_UWB_BLE_SLV_FD_BDC_F_0004 "TP Index : 271";
BA_ "SystemSignalLongSymbol" SG_ 2348810499 L_TP_L_UWB_BLE_SLV_FD_BDC_F_0004 "L_TP_L_UWB_BLE_SLV_FD_BDC_FD_Byte17";
BA_ "Version" SG_ 2348810499 L_TP_L_UWB_BLE_SLV_FD_BDC_F_0005 "23.01.02";
BA_ "NetworkRequestHoldingTime" SG_ 2348810499 L_TP_L_UWB_BLE_SLV_FD_BDC_F_0005 5000;
BA_ "NetworkRequest" SG_ 2348810499 L_TP_L_UWB_BLE_SLV_FD_BDC_F_0005 0;
BA_ "UserSigValidity" SG_ 2348810499 L_TP_L_UWB_BLE_SLV_FD_BDC_F_0005 0;
BA_ "UsrSigPurpose" SG_ 2348810499 L_TP_L_UWB_BLE_SLV_FD_BDC_F_0005 9;
BA_ "Description" SG_ 2348810499 L_TP_L_UWB_BLE_SLV_FD_BDC_F_0005 "TP Index : 271";
BA_ "SystemSignalLongSymbol" SG_ 2348810499 L_TP_L_UWB_BLE_SLV_FD_BDC_F_0005 "L_TP_L_UWB_BLE_SLV_FD_BDC_FD_Byte18";
BA_ "Version" SG_ 2348810499 L_TP_L_UWB_BLE_SLV_FD_BDC_F_0006 "23.01.02";
BA_ "NetworkRequestHoldingTime" SG_ 2348810499 L_TP_L_UWB_BLE_SLV_FD_BDC_F_0006 5000;
BA_ "NetworkRequest" SG_ 2348810499 L_TP_L_UWB_BLE_SLV_FD_BDC_F_0006 0;
BA_ "UserSigValidity" SG_ 2348810499 L_TP_L_UWB_BLE_SLV_FD_BDC_F_0006 0;
BA_ "UsrSigPurpose" SG_ 2348810499 L_TP_L_UWB_BLE_SLV_FD_BDC_F_0006 9;
BA_ "Description" SG_ 2348810499 L_TP_L_UWB_BLE_SLV_FD_BDC_F_0006 "TP Index : 271";
BA_ "SystemSignalLongSymbol" SG_ 2348810499 L_TP_L_UWB_BLE_SLV_FD_BDC_F_0006 "L_TP_L_UWB_BLE_SLV_FD_BDC_FD_Byte19";
BA_ "Version" SG_ 2348810499 L_TP_L_UWB_BLE_SLV_FD_BDC_F_0007 "23.01.02";
BA_ "NetworkRequestHoldingTime" SG_ 2348810499 L_TP_L_UWB_BLE_SLV_FD_BDC_F_0007 5000;
BA_ "NetworkRequest" SG_ 2348810499 L_TP_L_UWB_BLE_SLV_FD_BDC_F_0007 0;
BA_ "UserSigValidity" SG_ 2348810499 L_TP_L_UWB_BLE_SLV_FD_BDC_F_0007 0;
BA_ "UsrSigPurpose" SG_ 2348810499 L_TP_L_UWB_BLE_SLV_FD_BDC_F_0007 9;
BA_ "Description" SG_ 2348810499 L_TP_L_UWB_BLE_SLV_FD_BDC_F_0007 "TP Index : 271";
BA_ "SystemSignalLongSymbol" SG_ 2348810499 L_TP_L_UWB_BLE_SLV_FD_BDC_F_0007 "L_TP_L_UWB_BLE_SLV_FD_BDC_FD_Byte2";
BA_ "Version" SG_ 2348810499 L_TP_L_UWB_BLE_SLV_FD_BDC_F_0008 "23.01.02";
BA_ "NetworkRequestHoldingTime" SG_ 2348810499 L_TP_L_UWB_BLE_SLV_FD_BDC_F_0008 5000;
BA_ "NetworkRequest" SG_ 2348810499 L_TP_L_UWB_BLE_SLV_FD_BDC_F_0008 0;
BA_ "UserSigValidity" SG_ 2348810499 L_TP_L_UWB_BLE_SLV_FD_BDC_F_0008 0;
BA_ "UsrSigPurpose" SG_ 2348810499 L_TP_L_UWB_BLE_SLV_FD_BDC_F_0008 9;
BA_ "Description" SG_ 2348810499 L_TP_L_UWB_BLE_SLV_FD_BDC_F_0008 "TP Index : 271";
BA_ "SystemSignalLongSymbol" SG_ 2348810499 L_TP_L_UWB_BLE_SLV_FD_BDC_F_0008 "L_TP_L_UWB_BLE_SLV_FD_BDC_FD_Byte20";
BA_ "Version" SG_ 2348810499 L_TP_L_UWB_BLE_SLV_FD_BDC_F_0009 "23.01.02";
BA_ "NetworkRequestHoldingTime" SG_ 2348810499 L_TP_L_UWB_BLE_SLV_FD_BDC_F_0009 5000;
BA_ "NetworkRequest" SG_ 2348810499 L_TP_L_UWB_BLE_SLV_FD_BDC_F_0009 0;
BA_ "UserSigValidity" SG_ 2348810499 L_TP_L_UWB_BLE_SLV_FD_BDC_F_0009 0;
BA_ "UsrSigPurpose" SG_ 2348810499 L_TP_L_UWB_BLE_SLV_FD_BDC_F_0009 9;
BA_ "Description" SG_ 2348810499 L_TP_L_UWB_BLE_SLV_FD_BDC_F_0009 "TP Index : 271";
BA_ "SystemSignalLongSymbol" SG_ 2348810499 L_TP_L_UWB_BLE_SLV_FD_BDC_F_0009 "L_TP_L_UWB_BLE_SLV_FD_BDC_FD_Byte21";
BA_ "Version" SG_ 2348810499 L_TP_L_UWB_BLE_SLV_FD_BDC_F_0010 "23.01.02";
BA_ "NetworkRequestHoldingTime" SG_ 2348810499 L_TP_L_UWB_BLE_SLV_FD_BDC_F_0010 5000;
BA_ "NetworkRequest" SG_ 2348810499 L_TP_L_UWB_BLE_SLV_FD_BDC_F_0010 0;
BA_ "UserSigValidity" SG_ 2348810499 L_TP_L_UWB_BLE_SLV_FD_BDC_F_0010 0;
BA_ "UsrSigPurpose" SG_ 2348810499 L_TP_L_UWB_BLE_SLV_FD_BDC_F_0010 9;
BA_ "Description" SG_ 2348810499 L_TP_L_UWB_BLE_SLV_FD_BDC_F_0010 "TP Index : 271";
BA_ "SystemSignalLongSymbol" SG_ 2348810499 L_TP_L_UWB_BLE_SLV_FD_BDC_F_0010 "L_TP_L_UWB_BLE_SLV_FD_BDC_FD_Byte22";
BA_ "Version" SG_ 2348810499 L_TP_L_UWB_BLE_SLV_FD_BDC_F_0011 "23.01.02";
BA_ "NetworkRequestHoldingTime" SG_ 2348810499 L_TP_L_UWB_BLE_SLV_FD_BDC_F_0011 5000;
BA_ "NetworkRequest" SG_ 2348810499 L_TP_L_UWB_BLE_SLV_FD_BDC_F_0011 0;
BA_ "UserSigValidity" SG_ 2348810499 L_TP_L_UWB_BLE_SLV_FD_BDC_F_0011 0;
BA_ "UsrSigPurpose" SG_ 2348810499 L_TP_L_UWB_BLE_SLV_FD_BDC_F_0011 9;
BA_ "Description" SG_ 2348810499 L_TP_L_UWB_BLE_SLV_FD_BDC_F_0011 "TP Index : 271";
BA_ "SystemSignalLongSymbol" SG_ 2348810499 L_TP_L_UWB_BLE_SLV_FD_BDC_F_0011 "L_TP_L_UWB_BLE_SLV_FD_BDC_FD_Byte23";
BA_ "Version" SG_ 2348810499 L_TP_L_UWB_BLE_SLV_FD_BDC_F_0012 "23.01.02";
BA_ "NetworkRequestHoldingTime" SG_ 2348810499 L_TP_L_UWB_BLE_SLV_FD_BDC_F_0012 5000;
BA_ "NetworkRequest" SG_ 2348810499 L_TP_L_UWB_BLE_SLV_FD_BDC_F_0012 0;
BA_ "UserSigValidity" SG_ 2348810499 L_TP_L_UWB_BLE_SLV_FD_BDC_F_0012 0;
BA_ "UsrSigPurpose" SG_ 2348810499 L_TP_L_UWB_BLE_SLV_FD_BDC_F_0012 9;
BA_ "Description" SG_ 2348810499 L_TP_L_UWB_BLE_SLV_FD_BDC_F_0012 "TP Index : 271";
BA_ "SystemSignalLongSymbol" SG_ 2348810499 L_TP_L_UWB_BLE_SLV_FD_BDC_F_0012 "L_TP_L_UWB_BLE_SLV_FD_BDC_FD_Byte24";
BA_ "Version" SG_ 2348810499 L_TP_L_UWB_BLE_SLV_FD_BDC_F_0013 "23.01.02";
BA_ "NetworkRequestHoldingTime" SG_ 2348810499 L_TP_L_UWB_BLE_SLV_FD_BDC_F_0013 5000;
BA_ "NetworkRequest" SG_ 2348810499 L_TP_L_UWB_BLE_SLV_FD_BDC_F_0013 0;
BA_ "UserSigValidity" SG_ 2348810499 L_TP_L_UWB_BLE_SLV_FD_BDC_F_0013 0;
BA_ "UsrSigPurpose" SG_ 2348810499 L_TP_L_UWB_BLE_SLV_FD_BDC_F_0013 9;
BA_ "Description" SG_ 2348810499 L_TP_L_UWB_BLE_SLV_FD_BDC_F_0013 "TP Index : 271";
BA_ "SystemSignalLongSymbol" SG_ 2348810499 L_TP_L_UWB_BLE_SLV_FD_BDC_F_0013 "L_TP_L_UWB_BLE_SLV_FD_BDC_FD_Byte25";
BA_ "Version" SG_ 2348810499 L_TP_L_UWB_BLE_SLV_FD_BDC_F_0014 "23.01.02";
BA_ "NetworkRequestHoldingTime" SG_ 2348810499 L_TP_L_UWB_BLE_SLV_FD_BDC_F_0014 5000;
BA_ "NetworkRequest" SG_ 2348810499 L_TP_L_UWB_BLE_SLV_FD_BDC_F_0014 0;
BA_ "UserSigValidity" SG_ 2348810499 L_TP_L_UWB_BLE_SLV_FD_BDC_F_0014 0;
BA_ "UsrSigPurpose" SG_ 2348810499 L_TP_L_UWB_BLE_SLV_FD_BDC_F_0014 9;
BA_ "Description" SG_ 2348810499 L_TP_L_UWB_BLE_SLV_FD_BDC_F_0014 "TP Index : 271";
BA_ "SystemSignalLongSymbol" SG_ 2348810499 L_TP_L_UWB_BLE_SLV_FD_BDC_F_0014 "L_TP_L_UWB_BLE_SLV_FD_BDC_FD_Byte26";
BA_ "Version" SG_ 2348810499 L_TP_L_UWB_BLE_SLV_FD_BDC_F_0015 "23.01.02";
BA_ "NetworkRequestHoldingTime" SG_ 2348810499 L_TP_L_UWB_BLE_SLV_FD_BDC_F_0015 5000;
BA_ "NetworkRequest" SG_ 2348810499 L_TP_L_UWB_BLE_SLV_FD_BDC_F_0015 0;
BA_ "UserSigValidity" SG_ 2348810499 L_TP_L_UWB_BLE_SLV_FD_BDC_F_0015 0;
BA_ "UsrSigPurpose" SG_ 2348810499 L_TP_L_UWB_BLE_SLV_FD_BDC_F_0015 9;
BA_ "Description" SG_ 2348810499 L_TP_L_UWB_BLE_SLV_FD_BDC_F_0015 "TP Index : 271";
BA_ "SystemSignalLongSymbol" SG_ 2348810499 L_TP_L_UWB_BLE_SLV_FD_BDC_F_0015 "L_TP_L_UWB_BLE_SLV_FD_BDC_FD_Byte27";
BA_ "Version" SG_ 2348810499 L_TP_L_UWB_BLE_SLV_FD_BDC_F_0016 "23.01.02";
BA_ "NetworkRequestHoldingTime" SG_ 2348810499 L_TP_L_UWB_BLE_SLV_FD_BDC_F_0016 5000;
BA_ "NetworkRequest" SG_ 2348810499 L_TP_L_UWB_BLE_SLV_FD_BDC_F_0016 0;
BA_ "UserSigValidity" SG_ 2348810499 L_TP_L_UWB_BLE_SLV_FD_BDC_F_0016 0;
BA_ "UsrSigPurpose" SG_ 2348810499 L_TP_L_UWB_BLE_SLV_FD_BDC_F_0016 9;
BA_ "Description" SG_ 2348810499 L_TP_L_UWB_BLE_SLV_FD_BDC_F_0016 "TP Index : 271";
BA_ "SystemSignalLongSymbol" SG_ 2348810499 L_TP_L_UWB_BLE_SLV_FD_BDC_F_0016 "L_TP_L_UWB_BLE_SLV_FD_BDC_FD_Byte28";
BA_ "Version" SG_ 2348810499 L_TP_L_UWB_BLE_SLV_FD_BDC_F_0017 "23.01.02";
BA_ "NetworkRequestHoldingTime" SG_ 2348810499 L_TP_L_UWB_BLE_SLV_FD_BDC_F_0017 5000;
BA_ "NetworkRequest" SG_ 2348810499 L_TP_L_UWB_BLE_SLV_FD_BDC_F_0017 0;
BA_ "UserSigValidity" SG_ 2348810499 L_TP_L_UWB_BLE_SLV_FD_BDC_F_0017 0;
BA_ "UsrSigPurpose" SG_ 2348810499 L_TP_L_UWB_BLE_SLV_FD_BDC_F_0017 9;
BA_ "Description" SG_ 2348810499 L_TP_L_UWB_BLE_SLV_FD_BDC_F_0017 "TP Index : 271";
BA_ "SystemSignalLongSymbol" SG_ 2348810499 L_TP_L_UWB_BLE_SLV_FD_BDC_F_0017 "L_TP_L_UWB_BLE_SLV_FD_BDC_FD_Byte29";
BA_ "Version" SG_ 2348810499 L_TP_L_UWB_BLE_SLV_FD_BDC_F_0018 "23.01.02";
BA_ "NetworkRequestHoldingTime" SG_ 2348810499 L_TP_L_UWB_BLE_SLV_FD_BDC_F_0018 5000;
BA_ "NetworkRequest" SG_ 2348810499 L_TP_L_UWB_BLE_SLV_FD_BDC_F_0018 0;
BA_ "UserSigValidity" SG_ 2348810499 L_TP_L_UWB_BLE_SLV_FD_BDC_F_0018 0;
BA_ "UsrSigPurpose" SG_ 2348810499 L_TP_L_UWB_BLE_SLV_FD_BDC_F_0018 9;
BA_ "Description" SG_ 2348810499 L_TP_L_UWB_BLE_SLV_FD_BDC_F_0018 "TP Index : 271";
BA_ "SystemSignalLongSymbol" SG_ 2348810499 L_TP_L_UWB_BLE_SLV_FD_BDC_F_0018 "L_TP_L_UWB_BLE_SLV_FD_BDC_FD_Byte3";
BA_ "Version" SG_ 2348810499 L_TP_L_UWB_BLE_SLV_FD_BDC_F_0019 "23.01.02";
BA_ "NetworkRequestHoldingTime" SG_ 2348810499 L_TP_L_UWB_BLE_SLV_FD_BDC_F_0019 5000;
BA_ "NetworkRequest" SG_ 2348810499 L_TP_L_UWB_BLE_SLV_FD_BDC_F_0019 0;
BA_ "UserSigValidity" SG_ 2348810499 L_TP_L_UWB_BLE_SLV_FD_BDC_F_0019 0;
BA_ "UsrSigPurpose" SG_ 2348810499 L_TP_L_UWB_BLE_SLV_FD_BDC_F_0019 9;
BA_ "Description" SG_ 2348810499 L_TP_L_UWB_BLE_SLV_FD_BDC_F_0019 "TP Index : 271";
BA_ "SystemSignalLongSymbol" SG_ 2348810499 L_TP_L_UWB_BLE_SLV_FD_BDC_F_0019 "L_TP_L_UWB_BLE_SLV_FD_BDC_FD_Byte30";
BA_ "Version" SG_ 2348810499 L_TP_L_UWB_BLE_SLV_FD_BDC_F_0020 "23.01.02";
BA_ "NetworkRequestHoldingTime" SG_ 2348810499 L_TP_L_UWB_BLE_SLV_FD_BDC_F_0020 5000;
BA_ "NetworkRequest" SG_ 2348810499 L_TP_L_UWB_BLE_SLV_FD_BDC_F_0020 0;
BA_ "UserSigValidity" SG_ 2348810499 L_TP_L_UWB_BLE_SLV_FD_BDC_F_0020 0;
BA_ "UsrSigPurpose" SG_ 2348810499 L_TP_L_UWB_BLE_SLV_FD_BDC_F_0020 9;
BA_ "Description" SG_ 2348810499 L_TP_L_UWB_BLE_SLV_FD_BDC_F_0020 "TP Index : 271";
BA_ "SystemSignalLongSymbol" SG_ 2348810499 L_TP_L_UWB_BLE_SLV_FD_BDC_F_0020 "L_TP_L_UWB_BLE_SLV_FD_BDC_FD_Byte31";
BA_ "Version" SG_ 2348810499 L_TP_L_UWB_BLE_SLV_FD_BDC_F_0021 "23.01.02";
BA_ "NetworkRequestHoldingTime" SG_ 2348810499 L_TP_L_UWB_BLE_SLV_FD_BDC_F_0021 5000;
BA_ "NetworkRequest" SG_ 2348810499 L_TP_L_UWB_BLE_SLV_FD_BDC_F_0021 0;
BA_ "UserSigValidity" SG_ 2348810499 L_TP_L_UWB_BLE_SLV_FD_BDC_F_0021 0;
BA_ "UsrSigPurpose" SG_ 2348810499 L_TP_L_UWB_BLE_SLV_FD_BDC_F_0021 9;
BA_ "Description" SG_ 2348810499 L_TP_L_UWB_BLE_SLV_FD_BDC_F_0021 "TP Index : 271";
BA_ "SystemSignalLongSymbol" SG_ 2348810499 L_TP_L_UWB_BLE_SLV_FD_BDC_F_0021 "L_TP_L_UWB_BLE_SLV_FD_BDC_FD_Byte4";
BA_ "Version" SG_ 2348810499 L_TP_L_UWB_BLE_SLV_FD_BDC_F_0022 "23.01.02";
BA_ "NetworkRequestHoldingTime" SG_ 2348810499 L_TP_L_UWB_BLE_SLV_FD_BDC_F_0022 5000;
BA_ "NetworkRequest" SG_ 2348810499 L_TP_L_UWB_BLE_SLV_FD_BDC_F_0022 0;
BA_ "UserSigValidity" SG_ 2348810499 L_TP_L_UWB_BLE_SLV_FD_BDC_F_0022 0;
BA_ "UsrSigPurpose" SG_ 2348810499 L_TP_L_UWB_BLE_SLV_FD_BDC_F_0022 9;
BA_ "Description" SG_ 2348810499 L_TP_L_UWB_BLE_SLV_FD_BDC_F_0022 "TP Index : 271";
BA_ "SystemSignalLongSymbol" SG_ 2348810499 L_TP_L_UWB_BLE_SLV_FD_BDC_F_0022 "L_TP_L_UWB_BLE_SLV_FD_BDC_FD_Byte5";
BA_ "Version" SG_ 2348810499 L_TP_L_UWB_BLE_SLV_FD_BDC_F_0023 "23.01.02";
BA_ "NetworkRequestHoldingTime" SG_ 2348810499 L_TP_L_UWB_BLE_SLV_FD_BDC_F_0023 5000;
BA_ "NetworkRequest" SG_ 2348810499 L_TP_L_UWB_BLE_SLV_FD_BDC_F_0023 0;
BA_ "UserSigValidity" SG_ 2348810499 L_TP_L_UWB_BLE_SLV_FD_BDC_F_0023 0;
BA_ "UsrSigPurpose" SG_ 2348810499 L_TP_L_UWB_BLE_SLV_FD_BDC_F_0023 9;
BA_ "Description" SG_ 2348810499 L_TP_L_UWB_BLE_SLV_FD_BDC_F_0023 "TP Index : 271";
BA_ "SystemSignalLongSymbol" SG_ 2348810499 L_TP_L_UWB_BLE_SLV_FD_BDC_F_0023 "L_TP_L_UWB_BLE_SLV_FD_BDC_FD_Byte6";
BA_ "Version" SG_ 2348810499 L_TP_L_UWB_BLE_SLV_FD_BDC_F_0024 "23.01.02";
BA_ "NetworkRequestHoldingTime" SG_ 2348810499 L_TP_L_UWB_BLE_SLV_FD_BDC_F_0024 5000;
BA_ "NetworkRequest" SG_ 2348810499 L_TP_L_UWB_BLE_SLV_FD_BDC_F_0024 0;
BA_ "UserSigValidity" SG_ 2348810499 L_TP_L_UWB_BLE_SLV_FD_BDC_F_0024 0;
BA_ "UsrSigPurpose" SG_ 2348810499 L_TP_L_UWB_BLE_SLV_FD_BDC_F_0024 9;
BA_ "Description" SG_ 2348810499 L_TP_L_UWB_BLE_SLV_FD_BDC_F_0024 "TP Index : 271";
BA_ "SystemSignalLongSymbol" SG_ 2348810499 L_TP_L_UWB_BLE_SLV_FD_BDC_F_0024 "L_TP_L_UWB_BLE_SLV_FD_BDC_FD_Byte7";
BA_ "Version" SG_ 2348810499 L_TP_L_UWB_BLE_SLV_FD_BDC_F_0025 "23.01.02";
BA_ "NetworkRequestHoldingTime" SG_ 2348810499 L_TP_L_UWB_BLE_SLV_FD_BDC_F_0025 5000;
BA_ "NetworkRequest" SG_ 2348810499 L_TP_L_UWB_BLE_SLV_FD_BDC_F_0025 0;
BA_ "UserSigValidity" SG_ 2348810499 L_TP_L_UWB_BLE_SLV_FD_BDC_F_0025 0;
BA_ "UsrSigPurpose" SG_ 2348810499 L_TP_L_UWB_BLE_SLV_FD_BDC_F_0025 9;
BA_ "Description" SG_ 2348810499 L_TP_L_UWB_BLE_SLV_FD_BDC_F_0025 "TP Index : 271";
BA_ "SystemSignalLongSymbol" SG_ 2348810499 L_TP_L_UWB_BLE_SLV_FD_BDC_F_0025 "L_TP_L_UWB_BLE_SLV_FD_BDC_FD_Byte8";
BA_ "Version" SG_ 2348810499 L_TP_L_UWB_BLE_SLV_FD_BDC_F_0026 "23.01.02";
BA_ "NetworkRequestHoldingTime" SG_ 2348810499 L_TP_L_UWB_BLE_SLV_FD_BDC_F_0026 5000;
BA_ "NetworkRequest" SG_ 2348810499 L_TP_L_UWB_BLE_SLV_FD_BDC_F_0026 0;
BA_ "UserSigValidity" SG_ 2348810499 L_TP_L_UWB_BLE_SLV_FD_BDC_F_0026 0;
BA_ "UsrSigPurpose" SG_ 2348810499 L_TP_L_UWB_BLE_SLV_FD_BDC_F_0026 9;
BA_ "Description" SG_ 2348810499 L_TP_L_UWB_BLE_SLV_FD_BDC_F_0026 "TP Index : 271";
BA_ "SystemSignalLongSymbol" SG_ 2348810499 L_TP_L_UWB_BLE_SLV_FD_BDC_F_0026 "L_TP_L_UWB_BLE_SLV_FD_BDC_FD_Byte9";
BA_ "Version" SG_ 2348810499 L_TP_L_UWB_BLE_SLV_FD_BDC_F_0027 "23.01.02";
BA_ "NetworkRequestHoldingTime" SG_ 2348810499 L_TP_L_UWB_BLE_SLV_FD_BDC_F_0027 5000;
BA_ "NetworkRequest" SG_ 2348810499 L_TP_L_UWB_BLE_SLV_FD_BDC_F_0027 0;
BA_ "UserSigValidity" SG_ 2348810499 L_TP_L_UWB_BLE_SLV_FD_BDC_F_0027 0;
BA_ "UsrSigPurpose" SG_ 2348810499 L_TP_L_UWB_BLE_SLV_FD_BDC_F_0027 9;
BA_ "Description" SG_ 2348810499 L_TP_L_UWB_BLE_SLV_FD_BDC_F_0027 "TP Index : 271";
BA_ "SystemSignalLongSymbol" SG_ 2348810499 L_TP_L_UWB_BLE_SLV_FD_BDC_F_0027 "L_TP_L_UWB_BLE_SLV_FD_BDC_FD_Byte1";
BA_ "Version" SG_ 2348810499 L_TP_L_UWB_BLE_SLV_FD_BDC_F_0028 "23.01.02";
BA_ "NetworkRequestHoldingTime" SG_ 2348810499 L_TP_L_UWB_BLE_SLV_FD_BDC_F_0028 5000;
BA_ "NetworkRequest" SG_ 2348810499 L_TP_L_UWB_BLE_SLV_FD_BDC_F_0028 0;
BA_ "UserSigValidity" SG_ 2348810499 L_TP_L_UWB_BLE_SLV_FD_BDC_F_0028 0;
BA_ "UsrSigPurpose" SG_ 2348810499 L_TP_L_UWB_BLE_SLV_FD_BDC_F_0028 9;
BA_ "Description" SG_ 2348810499 L_TP_L_UWB_BLE_SLV_FD_BDC_F_0028 "TP Index : 271";
BA_ "SystemSignalLongSymbol" SG_ 2348810499 L_TP_L_UWB_BLE_SLV_FD_BDC_F_0028 "L_TP_L_UWB_BLE_SLV_FD_BDC_FD_Byte10";
BA_ "Version" SG_ 2348810499 L_TP_L_UWB_BLE_SLV_FD_BDC_F_0029 "23.01.02";
BA_ "NetworkRequestHoldingTime" SG_ 2348810499 L_TP_L_UWB_BLE_SLV_FD_BDC_F_0029 5000;
BA_ "NetworkRequest" SG_ 2348810499 L_TP_L_UWB_BLE_SLV_FD_BDC_F_0029 0;
BA_ "UserSigValidity" SG_ 2348810499 L_TP_L_UWB_BLE_SLV_FD_BDC_F_0029 0;
BA_ "UsrSigPurpose" SG_ 2348810499 L_TP_L_UWB_BLE_SLV_FD_BDC_F_0029 9;
BA_ "Description" SG_ 2348810499 L_TP_L_UWB_BLE_SLV_FD_BDC_F_0029 "TP Index : 271";
BA_ "SystemSignalLongSymbol" SG_ 2348810499 L_TP_L_UWB_BLE_SLV_FD_BDC_F_0029 "L_TP_L_UWB_BLE_SLV_FD_BDC_FD_Byte11";
BA_ "Version" SG_ 2348810499 L_TP_L_UWB_BLE_SLV_FD_BDC_F_0030 "23.01.02";
BA_ "NetworkRequestHoldingTime" SG_ 2348810499 L_TP_L_UWB_BLE_SLV_FD_BDC_F_0030 5000;
BA_ "NetworkRequest" SG_ 2348810499 L_TP_L_UWB_BLE_SLV_FD_BDC_F_0030 0;
BA_ "UserSigValidity" SG_ 2348810499 L_TP_L_UWB_BLE_SLV_FD_BDC_F_0030 0;
BA_ "UsrSigPurpose" SG_ 2348810499 L_TP_L_UWB_BLE_SLV_FD_BDC_F_0030 9;
BA_ "Description" SG_ 2348810499 L_TP_L_UWB_BLE_SLV_FD_BDC_F_0030 "TP Index : 271";
BA_ "SystemSignalLongSymbol" SG_ 2348810499 L_TP_L_UWB_BLE_SLV_FD_BDC_F_0030 "L_TP_L_UWB_BLE_SLV_FD_BDC_FD_Byte12";
BA_REL_ "GenSigTimeoutTime" BU_SG_REL_ L_DHRL_FD SG_ 2348810506 TP_BDC_FD_L_DHRL_FD_Byte0 0;
BA_REL_ "GenSigTimeoutTime" BU_SG_REL_ L_DHRL_FD SG_ 2348810506 TP_BDC_FD_L_DHRL_FD_Byte13 0;
BA_REL_ "GenSigTimeoutTime" BU_SG_REL_ L_DHRL_FD SG_ 2348810506 TP_BDC_FD_L_DHRL_FD_Byte14 0;
BA_REL_ "GenSigTimeoutTime" BU_SG_REL_ L_DHRL_FD SG_ 2348810506 TP_BDC_FD_L_DHRL_FD_Byte15 0;
BA_REL_ "GenSigTimeoutTime" BU_SG_REL_ L_DHRL_FD SG_ 2348810506 TP_BDC_FD_L_DHRL_FD_Byte16 0;
BA_REL_ "GenSigTimeoutTime" BU_SG_REL_ L_DHRL_FD SG_ 2348810506 TP_BDC_FD_L_DHRL_FD_Byte17 0;
BA_REL_ "GenSigTimeoutTime" BU_SG_REL_ L_DHRL_FD SG_ 2348810506 TP_BDC_FD_L_DHRL_FD_Byte18 0;
BA_REL_ "GenSigTimeoutTime" BU_SG_REL_ L_DHRL_FD SG_ 2348810506 TP_BDC_FD_L_DHRL_FD_Byte19 0;
BA_REL_ "GenSigTimeoutTime" BU_SG_REL_ L_DHRL_FD SG_ 2348810506 TP_BDC_FD_L_DHRL_FD_Byte2 0;
BA_REL_ "GenSigTimeoutTime" BU_SG_REL_ L_DHRL_FD SG_ 2348810506 TP_BDC_FD_L_DHRL_FD_Byte20 0;
BA_REL_ "GenSigTimeoutTime" BU_SG_REL_ L_DHRL_FD SG_ 2348810506 TP_BDC_FD_L_DHRL_FD_Byte21 0;
BA_REL_ "GenSigTimeoutTime" BU_SG_REL_ L_DHRL_FD SG_ 2348810506 TP_BDC_FD_L_DHRL_FD_Byte22 0;
BA_REL_ "GenSigTimeoutTime" BU_SG_REL_ L_DHRL_FD SG_ 2348810506 TP_BDC_FD_L_DHRL_FD_Byte23 0;
BA_REL_ "GenSigTimeoutTime" BU_SG_REL_ L_DHRL_FD SG_ 2348810506 TP_BDC_FD_L_DHRL_FD_Byte24 0;
BA_REL_ "GenSigTimeoutTime" BU_SG_REL_ L_DHRL_FD SG_ 2348810506 TP_BDC_FD_L_DHRL_FD_Byte25 0;
BA_REL_ "GenSigTimeoutTime" BU_SG_REL_ L_DHRL_FD SG_ 2348810506 TP_BDC_FD_L_DHRL_FD_Byte26 0;
BA_REL_ "GenSigTimeoutTime" BU_SG_REL_ L_DHRL_FD SG_ 2348810506 TP_BDC_FD_L_DHRL_FD_Byte27 0;
BA_REL_ "GenSigTimeoutTime" BU_SG_REL_ L_DHRL_FD SG_ 2348810506 TP_BDC_FD_L_DHRL_FD_Byte28 0;
BA_REL_ "GenSigTimeoutTime" BU_SG_REL_ L_DHRL_FD SG_ 2348810506 TP_BDC_FD_L_DHRL_FD_Byte29 0;
BA_REL_ "GenSigTimeoutTime" BU_SG_REL_ L_DHRL_FD SG_ 2348810506 TP_BDC_FD_L_DHRL_FD_Byte3 0;
BA_REL_ "GenSigTimeoutTime" BU_SG_REL_ L_DHRL_FD SG_ 2348810506 TP_BDC_FD_L_DHRL_FD_Byte30 0;
BA_REL_ "GenSigTimeoutTime" BU_SG_REL_ L_DHRL_FD SG_ 2348810506 TP_BDC_FD_L_DHRL_FD_Byte31 0;
BA_REL_ "GenSigTimeoutTime" BU_SG_REL_ L_DHRL_FD SG_ 2348810506 TP_BDC_FD_L_DHRL_FD_Byte4 0;
BA_REL_ "GenSigTimeoutTime" BU_SG_REL_ L_DHRL_FD SG_ 2348810506 TP_BDC_FD_L_DHRL_FD_Byte5 0;
BA_REL_ "GenSigTimeoutTime" BU_SG_REL_ L_DHRL_FD SG_ 2348810506 TP_BDC_FD_L_DHRL_FD_Byte6 0;
BA_REL_ "GenSigTimeoutTime" BU_SG_REL_ L_DHRL_FD SG_ 2348810506 TP_BDC_FD_L_DHRL_FD_Byte7 0;
BA_REL_ "GenSigTimeoutTime" BU_SG_REL_ L_DHRL_FD SG_ 2348810506 TP_BDC_FD_L_DHRL_FD_Byte8 0;
BA_REL_ "GenSigTimeoutTime" BU_SG_REL_ L_DHRL_FD SG_ 2348810506 TP_BDC_FD_L_DHRL_FD_Byte9 0;
BA_REL_ "GenSigTimeoutTime" BU_SG_REL_ L_DHRL_FD SG_ 2348810506 TP_BDC_FD_L_DHRL_FD_Byte1 0;
BA_REL_ "GenSigTimeoutTime" BU_SG_REL_ L_DHRL_FD SG_ 2348810506 TP_BDC_FD_L_DHRL_FD_Byte10 0;
BA_REL_ "GenSigTimeoutTime" BU_SG_REL_ L_DHRL_FD SG_ 2348810506 TP_BDC_FD_L_DHRL_FD_Byte11 0;
BA_REL_ "GenSigTimeoutTime" BU_SG_REL_ L_DHRL_FD SG_ 2348810506 TP_BDC_FD_L_DHRL_FD_Byte12 0;
BA_REL_ "GenSigTimeoutTime" BU_SG_REL_ GW_BDC_FD SG_ 2348810505 L_TP_L_DHR_FD_BDC_FD_Byte0 0;
BA_REL_ "GenSigTimeoutTime" BU_SG_REL_ GW_BDC_FD SG_ 2348810505 L_TP_L_DHR_FD_BDC_FD_Byte13 0;
BA_REL_ "GenSigTimeoutTime" BU_SG_REL_ GW_BDC_FD SG_ 2348810505 L_TP_L_DHR_FD_BDC_FD_Byte14 0;
BA_REL_ "GenSigTimeoutTime" BU_SG_REL_ GW_BDC_FD SG_ 2348810505 L_TP_L_DHR_FD_BDC_FD_Byte15 0;
BA_REL_ "GenSigTimeoutTime" BU_SG_REL_ GW_BDC_FD SG_ 2348810505 L_TP_L_DHR_FD_BDC_FD_Byte16 0;
BA_REL_ "GenSigTimeoutTime" BU_SG_REL_ GW_BDC_FD SG_ 2348810505 L_TP_L_DHR_FD_BDC_FD_Byte17 0;
BA_REL_ "GenSigTimeoutTime" BU_SG_REL_ GW_BDC_FD SG_ 2348810505 L_TP_L_DHR_FD_BDC_FD_Byte18 0;
BA_REL_ "GenSigTimeoutTime" BU_SG_REL_ GW_BDC_FD SG_ 2348810505 L_TP_L_DHR_FD_BDC_FD_Byte19 0;
BA_REL_ "GenSigTimeoutTime" BU_SG_REL_ GW_BDC_FD SG_ 2348810505 L_TP_L_DHR_FD_BDC_FD_Byte2 0;
BA_REL_ "GenSigTimeoutTime" BU_SG_REL_ GW_BDC_FD SG_ 2348810505 L_TP_L_DHR_FD_BDC_FD_Byte20 0;
BA_REL_ "GenSigTimeoutTime" BU_SG_REL_ GW_BDC_FD SG_ 2348810505 L_TP_L_DHR_FD_BDC_FD_Byte21 0;
BA_REL_ "GenSigTimeoutTime" BU_SG_REL_ GW_BDC_FD SG_ 2348810505 L_TP_L_DHR_FD_BDC_FD_Byte22 0;
BA_REL_ "GenSigTimeoutTime" BU_SG_REL_ GW_BDC_FD SG_ 2348810505 L_TP_L_DHR_FD_BDC_FD_Byte23 0;
BA_REL_ "GenSigTimeoutTime" BU_SG_REL_ GW_BDC_FD SG_ 2348810505 L_TP_L_DHR_FD_BDC_FD_Byte24 0;
BA_REL_ "GenSigTimeoutTime" BU_SG_REL_ GW_BDC_FD SG_ 2348810505 L_TP_L_DHR_FD_BDC_FD_Byte25 0;
BA_REL_ "GenSigTimeoutTime" BU_SG_REL_ GW_BDC_FD SG_ 2348810505 L_TP_L_DHR_FD_BDC_FD_Byte26 0;
BA_REL_ "GenSigTimeoutTime" BU_SG_REL_ GW_BDC_FD SG_ 2348810505 L_TP_L_DHR_FD_BDC_FD_Byte27 0;
BA_REL_ "GenSigTimeoutTime" BU_SG_REL_ GW_BDC_FD SG_ 2348810505 L_TP_L_DHR_FD_BDC_FD_Byte28 0;
BA_REL_ "GenSigTimeoutTime" BU_SG_REL_ GW_BDC_FD SG_ 2348810505 L_TP_L_DHR_FD_BDC_FD_Byte29 0;
BA_REL_ "GenSigTimeoutTime" BU_SG_REL_ GW_BDC_FD SG_ 2348810505 L_TP_L_DHR_FD_BDC_FD_Byte3 0;
BA_REL_ "GenSigTimeoutTime" BU_SG_REL_ GW_BDC_FD SG_ 2348810505 L_TP_L_DHR_FD_BDC_FD_Byte30 0;
BA_REL_ "GenSigTimeoutTime" BU_SG_REL_ GW_BDC_FD SG_ 2348810505 L_TP_L_DHR_FD_BDC_FD_Byte31 0;
BA_REL_ "GenSigTimeoutTime" BU_SG_REL_ GW_BDC_FD SG_ 2348810505 L_TP_L_DHR_FD_BDC_FD_Byte4 0;
BA_REL_ "GenSigTimeoutTime" BU_SG_REL_ GW_BDC_FD SG_ 2348810505 L_TP_L_DHR_FD_BDC_FD_Byte5 0;
BA_REL_ "GenSigTimeoutTime" BU_SG_REL_ GW_BDC_FD SG_ 2348810505 L_TP_L_DHR_FD_BDC_FD_Byte6 0;
BA_REL_ "GenSigTimeoutTime" BU_SG_REL_ GW_BDC_FD SG_ 2348810505 L_TP_L_DHR_FD_BDC_FD_Byte7 0;
BA_REL_ "GenSigTimeoutTime" BU_SG_REL_ GW_BDC_FD SG_ 2348810505 L_TP_L_DHR_FD_BDC_FD_Byte8 0;
BA_REL_ "GenSigTimeoutTime" BU_SG_REL_ GW_BDC_FD SG_ 2348810505 L_TP_L_DHR_FD_BDC_FD_Byte9 0;
BA_REL_ "GenSigTimeoutTime" BU_SG_REL_ GW_BDC_FD SG_ 2348810505 L_TP_L_DHR_FD_BDC_FD_Byte1 0;
BA_REL_ "GenSigTimeoutTime" BU_SG_REL_ GW_BDC_FD SG_ 2348810505 L_TP_L_DHR_FD_BDC_FD_Byte10 0;
BA_REL_ "GenSigTimeoutTime" BU_SG_REL_ GW_BDC_FD SG_ 2348810505 L_TP_L_DHR_FD_BDC_FD_Byte11 0;
BA_REL_ "GenSigTimeoutTime" BU_SG_REL_ GW_BDC_FD SG_ 2348810505 L_TP_L_DHR_FD_BDC_FD_Byte12 0;
BA_REL_ "GenSigTimeoutTime" BU_SG_REL_ L_DHR_FD SG_ 2348810504 L_TP_BDC_FD_L_DHR_FD_Byte0 0;
BA_REL_ "GenSigTimeoutTime" BU_SG_REL_ L_DHR_FD SG_ 2348810504 L_TP_BDC_FD_L_DHR_FD_Byte13 0;
BA_REL_ "GenSigTimeoutTime" BU_SG_REL_ L_DHR_FD SG_ 2348810504 L_TP_BDC_FD_L_DHR_FD_Byte14 0;
BA_REL_ "GenSigTimeoutTime" BU_SG_REL_ L_DHR_FD SG_ 2348810504 L_TP_BDC_FD_L_DHR_FD_Byte15 0;
BA_REL_ "GenSigTimeoutTime" BU_SG_REL_ L_DHR_FD SG_ 2348810504 L_TP_BDC_FD_L_DHR_FD_Byte16 0;
BA_REL_ "GenSigTimeoutTime" BU_SG_REL_ L_DHR_FD SG_ 2348810504 L_TP_BDC_FD_L_DHR_FD_Byte17 0;
BA_REL_ "GenSigTimeoutTime" BU_SG_REL_ L_DHR_FD SG_ 2348810504 L_TP_BDC_FD_L_DHR_FD_Byte18 0;
BA_REL_ "GenSigTimeoutTime" BU_SG_REL_ L_DHR_FD SG_ 2348810504 L_TP_BDC_FD_L_DHR_FD_Byte19 0;
BA_REL_ "GenSigTimeoutTime" BU_SG_REL_ L_DHR_FD SG_ 2348810504 L_TP_BDC_FD_L_DHR_FD_Byte2 0;
BA_REL_ "GenSigTimeoutTime" BU_SG_REL_ L_DHR_FD SG_ 2348810504 L_TP_BDC_FD_L_DHR_FD_Byte20 0;
BA_REL_ "GenSigTimeoutTime" BU_SG_REL_ L_DHR_FD SG_ 2348810504 L_TP_BDC_FD_L_DHR_FD_Byte21 0;
BA_REL_ "GenSigTimeoutTime" BU_SG_REL_ L_DHR_FD SG_ 2348810504 L_TP_BDC_FD_L_DHR_FD_Byte22 0;
BA_REL_ "GenSigTimeoutTime" BU_SG_REL_ L_DHR_FD SG_ 2348810504 L_TP_BDC_FD_L_DHR_FD_Byte23 0;
BA_REL_ "GenSigTimeoutTime" BU_SG_REL_ L_DHR_FD SG_ 2348810504 L_TP_BDC_FD_L_DHR_FD_Byte24 0;
BA_REL_ "GenSigTimeoutTime" BU_SG_REL_ L_DHR_FD SG_ 2348810504 L_TP_BDC_FD_L_DHR_FD_Byte25 0;
BA_REL_ "GenSigTimeoutTime" BU_SG_REL_ L_DHR_FD SG_ 2348810504 L_TP_BDC_FD_L_DHR_FD_Byte26 0;
BA_REL_ "GenSigTimeoutTime" BU_SG_REL_ L_DHR_FD SG_ 2348810504 L_TP_BDC_FD_L_DHR_FD_Byte27 0;
BA_REL_ "GenSigTimeoutTime" BU_SG_REL_ L_DHR_FD SG_ 2348810504 L_TP_BDC_FD_L_DHR_FD_Byte28 0;
BA_REL_ "GenSigTimeoutTime" BU_SG_REL_ L_DHR_FD SG_ 2348810504 L_TP_BDC_FD_L_DHR_FD_Byte29 0;
BA_REL_ "GenSigTimeoutTime" BU_SG_REL_ L_DHR_FD SG_ 2348810504 L_TP_BDC_FD_L_DHR_FD_Byte3 0;
BA_REL_ "GenSigTimeoutTime" BU_SG_REL_ L_DHR_FD SG_ 2348810504 L_TP_BDC_FD_L_DHR_FD_Byte30 0;
BA_REL_ "GenSigTimeoutTime" BU_SG_REL_ L_DHR_FD SG_ 2348810504 L_TP_BDC_FD_L_DHR_FD_Byte31 0;
BA_REL_ "GenSigTimeoutTime" BU_SG_REL_ L_DHR_FD SG_ 2348810504 L_TP_BDC_FD_L_DHR_FD_Byte4 0;
BA_REL_ "GenSigTimeoutTime" BU_SG_REL_ L_DHR_FD SG_ 2348810504 L_TP_BDC_FD_L_DHR_FD_Byte5 0;
BA_REL_ "GenSigTimeoutTime" BU_SG_REL_ L_DHR_FD SG_ 2348810504 L_TP_BDC_FD_L_DHR_FD_Byte6 0;
BA_REL_ "GenSigTimeoutTime" BU_SG_REL_ L_DHR_FD SG_ 2348810504 L_TP_BDC_FD_L_DHR_FD_Byte7 0;
BA_REL_ "GenSigTimeoutTime" BU_SG_REL_ L_DHR_FD SG_ 2348810504 L_TP_BDC_FD_L_DHR_FD_Byte8 0;
BA_REL_ "GenSigTimeoutTime" BU_SG_REL_ L_DHR_FD SG_ 2348810504 L_TP_BDC_FD_L_DHR_FD_Byte9 0;
BA_REL_ "GenSigTimeoutTime" BU_SG_REL_ L_DHR_FD SG_ 2348810504 L_TP_BDC_FD_L_DHR_FD_Byte1 0;
BA_REL_ "GenSigTimeoutTime" BU_SG_REL_ L_DHR_FD SG_ 2348810504 L_TP_BDC_FD_L_DHR_FD_Byte10 0;
BA_REL_ "GenSigTimeoutTime" BU_SG_REL_ L_DHR_FD SG_ 2348810504 L_TP_BDC_FD_L_DHR_FD_Byte11 0;
BA_REL_ "GenSigTimeoutTime" BU_SG_REL_ L_DHR_FD SG_ 2348810504 L_TP_BDC_FD_L_DHR_FD_Byte12 0;
BA_REL_ "GenSigTimeoutTime" BU_SG_REL_ GW_BDC_FD SG_ 2348810503 L_TP_L_DHL_FD_BDC_FD_Byte0 0;
BA_REL_ "GenSigTimeoutTime" BU_SG_REL_ GW_BDC_FD SG_ 2348810503 L_TP_L_DHL_FD_BDC_FD_Byte13 0;
BA_REL_ "GenSigTimeoutTime" BU_SG_REL_ GW_BDC_FD SG_ 2348810503 L_TP_L_DHL_FD_BDC_FD_Byte14 0;
BA_REL_ "GenSigTimeoutTime" BU_SG_REL_ GW_BDC_FD SG_ 2348810503 L_TP_L_DHL_FD_BDC_FD_Byte15 0;
BA_REL_ "GenSigTimeoutTime" BU_SG_REL_ GW_BDC_FD SG_ 2348810503 L_TP_L_DHL_FD_BDC_FD_Byte16 0;
BA_REL_ "GenSigTimeoutTime" BU_SG_REL_ GW_BDC_FD SG_ 2348810503 L_TP_L_DHL_FD_BDC_FD_Byte17 0;
BA_REL_ "GenSigTimeoutTime" BU_SG_REL_ GW_BDC_FD SG_ 2348810503 L_TP_L_DHL_FD_BDC_FD_Byte18 0;
BA_REL_ "GenSigTimeoutTime" BU_SG_REL_ GW_BDC_FD SG_ 2348810503 L_TP_L_DHL_FD_BDC_FD_Byte19 0;
BA_REL_ "GenSigTimeoutTime" BU_SG_REL_ GW_BDC_FD SG_ 2348810503 L_TP_L_DHL_FD_BDC_FD_Byte2 0;
BA_REL_ "GenSigTimeoutTime" BU_SG_REL_ GW_BDC_FD SG_ 2348810503 L_TP_L_DHL_FD_BDC_FD_Byte20 0;
BA_REL_ "GenSigTimeoutTime" BU_SG_REL_ GW_BDC_FD SG_ 2348810503 L_TP_L_DHL_FD_BDC_FD_Byte21 0;
BA_REL_ "GenSigTimeoutTime" BU_SG_REL_ GW_BDC_FD SG_ 2348810503 L_TP_L_DHL_FD_BDC_FD_Byte22 0;
BA_REL_ "GenSigTimeoutTime" BU_SG_REL_ GW_BDC_FD SG_ 2348810503 L_TP_L_DHL_FD_BDC_FD_Byte23 0;
BA_REL_ "GenSigTimeoutTime" BU_SG_REL_ GW_BDC_FD SG_ 2348810503 L_TP_L_DHL_FD_BDC_FD_Byte24 0;
BA_REL_ "GenSigTimeoutTime" BU_SG_REL_ GW_BDC_FD SG_ 2348810503 L_TP_L_DHL_FD_BDC_FD_Byte25 0;
BA_REL_ "GenSigTimeoutTime" BU_SG_REL_ GW_BDC_FD SG_ 2348810503 L_TP_L_DHL_FD_BDC_FD_Byte26 0;
BA_REL_ "GenSigTimeoutTime" BU_SG_REL_ GW_BDC_FD SG_ 2348810503 L_TP_L_DHL_FD_BDC_FD_Byte27 0;
BA_REL_ "GenSigTimeoutTime" BU_SG_REL_ GW_BDC_FD SG_ 2348810503 L_TP_L_DHL_FD_BDC_FD_Byte28 0;
BA_REL_ "GenSigTimeoutTime" BU_SG_REL_ GW_BDC_FD SG_ 2348810503 L_TP_L_DHL_FD_BDC_FD_Byte29 0;
BA_REL_ "GenSigTimeoutTime" BU_SG_REL_ GW_BDC_FD SG_ 2348810503 L_TP_L_DHL_FD_BDC_FD_Byte3 0;
BA_REL_ "GenSigTimeoutTime" BU_SG_REL_ GW_BDC_FD SG_ 2348810503 L_TP_L_DHL_FD_BDC_FD_Byte30 0;
BA_REL_ "GenSigTimeoutTime" BU_SG_REL_ GW_BDC_FD SG_ 2348810503 L_TP_L_DHL_FD_BDC_FD_Byte31 0;
BA_REL_ "GenSigTimeoutTime" BU_SG_REL_ GW_BDC_FD SG_ 2348810503 L_TP_L_DHL_FD_BDC_FD_Byte4 0;
BA_REL_ "GenSigTimeoutTime" BU_SG_REL_ GW_BDC_FD SG_ 2348810503 L_TP_L_DHL_FD_BDC_FD_Byte5 0;
BA_REL_ "GenSigTimeoutTime" BU_SG_REL_ GW_BDC_FD SG_ 2348810503 L_TP_L_DHL_FD_BDC_FD_Byte6 0;
BA_REL_ "GenSigTimeoutTime" BU_SG_REL_ GW_BDC_FD SG_ 2348810503 L_TP_L_DHL_FD_BDC_FD_Byte7 0;
BA_REL_ "GenSigTimeoutTime" BU_SG_REL_ GW_BDC_FD SG_ 2348810503 L_TP_L_DHL_FD_BDC_FD_Byte8 0;
BA_REL_ "GenSigTimeoutTime" BU_SG_REL_ GW_BDC_FD SG_ 2348810503 L_TP_L_DHL_FD_BDC_FD_Byte9 0;
BA_REL_ "GenSigTimeoutTime" BU_SG_REL_ GW_BDC_FD SG_ 2348810503 L_TP_L_DHL_FD_BDC_FD_Byte1 0;
BA_REL_ "GenSigTimeoutTime" BU_SG_REL_ GW_BDC_FD SG_ 2348810503 L_TP_L_DHL_FD_BDC_FD_Byte10 0;
BA_REL_ "GenSigTimeoutTime" BU_SG_REL_ GW_BDC_FD SG_ 2348810503 L_TP_L_DHL_FD_BDC_FD_Byte11 0;
BA_REL_ "GenSigTimeoutTime" BU_SG_REL_ GW_BDC_FD SG_ 2348810503 L_TP_L_DHL_FD_BDC_FD_Byte12 0;
BA_REL_ "GenSigTimeoutTime" BU_SG_REL_ L_EDT_FD SG_ 2214592660 DHR_Dvp_Msg 0;
BA_REL_ "GenSigTimeoutTime" BU_SG_REL_ L_DHL_FD SG_ 2348810502 L_TP_BDC_FD_L_DHL_FD_Byte0 0;
BA_REL_ "GenSigTimeoutTime" BU_SG_REL_ L_DHL_FD SG_ 2348810502 L_TP_BDC_FD_L_DHL_FD_Byte13 0;
BA_REL_ "GenSigTimeoutTime" BU_SG_REL_ L_DHL_FD SG_ 2348810502 L_TP_BDC_FD_L_DHL_FD_Byte14 0;
BA_REL_ "GenSigTimeoutTime" BU_SG_REL_ L_DHL_FD SG_ 2348810502 L_TP_BDC_FD_L_DHL_FD_Byte15 0;
BA_REL_ "GenSigTimeoutTime" BU_SG_REL_ L_DHL_FD SG_ 2348810502 L_TP_BDC_FD_L_DHL_FD_Byte16 0;
BA_REL_ "GenSigTimeoutTime" BU_SG_REL_ L_DHL_FD SG_ 2348810502 L_TP_BDC_FD_L_DHL_FD_Byte17 0;
BA_REL_ "GenSigTimeoutTime" BU_SG_REL_ L_DHL_FD SG_ 2348810502 L_TP_BDC_FD_L_DHL_FD_Byte18 0;
BA_REL_ "GenSigTimeoutTime" BU_SG_REL_ L_DHL_FD SG_ 2348810502 L_TP_BDC_FD_L_DHL_FD_Byte19 0;
BA_REL_ "GenSigTimeoutTime" BU_SG_REL_ L_DHL_FD SG_ 2348810502 L_TP_BDC_FD_L_DHL_FD_Byte2 0;
BA_REL_ "GenSigTimeoutTime" BU_SG_REL_ L_DHL_FD SG_ 2348810502 L_TP_BDC_FD_L_DHL_FD_Byte20 0;
BA_REL_ "GenSigTimeoutTime" BU_SG_REL_ L_DHL_FD SG_ 2348810502 L_TP_BDC_FD_L_DHL_FD_Byte21 0;
BA_REL_ "GenSigTimeoutTime" BU_SG_REL_ L_DHL_FD SG_ 2348810502 L_TP_BDC_FD_L_DHL_FD_Byte22 0;
BA_REL_ "GenSigTimeoutTime" BU_SG_REL_ L_DHL_FD SG_ 2348810502 L_TP_BDC_FD_L_DHL_FD_Byte23 0;
BA_REL_ "GenSigTimeoutTime" BU_SG_REL_ L_DHL_FD SG_ 2348810502 L_TP_BDC_FD_L_DHL_FD_Byte24 0;
BA_REL_ "GenSigTimeoutTime" BU_SG_REL_ L_DHL_FD SG_ 2348810502 L_TP_BDC_FD_L_DHL_FD_Byte25 0;
BA_REL_ "GenSigTimeoutTime" BU_SG_REL_ L_DHL_FD SG_ 2348810502 L_TP_BDC_FD_L_DHL_FD_Byte26 0;
BA_REL_ "GenSigTimeoutTime" BU_SG_REL_ L_DHL_FD SG_ 2348810502 L_TP_BDC_FD_L_DHL_FD_Byte27 0;
BA_REL_ "GenSigTimeoutTime" BU_SG_REL_ L_DHL_FD SG_ 2348810502 L_TP_BDC_FD_L_DHL_FD_Byte28 0;
BA_REL_ "GenSigTimeoutTime" BU_SG_REL_ L_DHL_FD SG_ 2348810502 L_TP_BDC_FD_L_DHL_FD_Byte29 0;
BA_REL_ "GenSigTimeoutTime" BU_SG_REL_ L_DHL_FD SG_ 2348810502 L_TP_BDC_FD_L_DHL_FD_Byte3 0;
BA_REL_ "GenSigTimeoutTime" BU_SG_REL_ L_DHL_FD SG_ 2348810502 L_TP_BDC_FD_L_DHL_FD_Byte30 0;
BA_REL_ "GenSigTimeoutTime" BU_SG_REL_ L_DHL_FD SG_ 2348810502 L_TP_BDC_FD_L_DHL_FD_Byte31 0;
BA_REL_ "GenSigTimeoutTime" BU_SG_REL_ L_DHL_FD SG_ 2348810502 L_TP_BDC_FD_L_DHL_FD_Byte4 0;
BA_REL_ "GenSigTimeoutTime" BU_SG_REL_ L_DHL_FD SG_ 2348810502 L_TP_BDC_FD_L_DHL_FD_Byte5 0;
BA_REL_ "GenSigTimeoutTime" BU_SG_REL_ L_DHL_FD SG_ 2348810502 L_TP_BDC_FD_L_DHL_FD_Byte6 0;
BA_REL_ "GenSigTimeoutTime" BU_SG_REL_ L_DHL_FD SG_ 2348810502 L_TP_BDC_FD_L_DHL_FD_Byte7 0;
BA_REL_ "GenSigTimeoutTime" BU_SG_REL_ L_DHL_FD SG_ 2348810502 L_TP_BDC_FD_L_DHL_FD_Byte8 0;
BA_REL_ "GenSigTimeoutTime" BU_SG_REL_ L_DHL_FD SG_ 2348810502 L_TP_BDC_FD_L_DHL_FD_Byte9 0;
BA_REL_ "GenSigTimeoutTime" BU_SG_REL_ L_DHL_FD SG_ 2348810502 L_TP_BDC_FD_L_DHL_FD_Byte1 0;
BA_REL_ "GenSigTimeoutTime" BU_SG_REL_ L_DHL_FD SG_ 2348810502 L_TP_BDC_FD_L_DHL_FD_Byte10 0;
BA_REL_ "GenSigTimeoutTime" BU_SG_REL_ L_DHL_FD SG_ 2348810502 L_TP_BDC_FD_L_DHL_FD_Byte11 0;
BA_REL_ "GenSigTimeoutTime" BU_SG_REL_ L_DHL_FD SG_ 2348810502 L_TP_BDC_FD_L_DHL_FD_Byte12 0;
BA_REL_ "GenSigTimeoutTime" BU_SG_REL_ L_EDT_FD SG_ 2214592661 DHRR_Dvp_Msg 0;
BA_REL_ "GenSigTimeoutTime" BU_SG_REL_ GW_BDC_FD SG_ 2348810501 L_TP_L_WPC_FD_BDC_FD_Byte0 0;
BA_REL_ "GenSigTimeoutTime" BU_SG_REL_ GW_BDC_FD SG_ 2348810501 L_TP_L_WPC_FD_BDC_FD_Byte13 0;
BA_REL_ "GenSigTimeoutTime" BU_SG_REL_ GW_BDC_FD SG_ 2348810501 L_TP_L_WPC_FD_BDC_FD_Byte14 0;
BA_REL_ "GenSigTimeoutTime" BU_SG_REL_ GW_BDC_FD SG_ 2348810501 L_TP_L_WPC_FD_BDC_FD_Byte15 0;
BA_REL_ "GenSigTimeoutTime" BU_SG_REL_ GW_BDC_FD SG_ 2348810501 L_TP_L_WPC_FD_BDC_FD_Byte16 0;
BA_REL_ "GenSigTimeoutTime" BU_SG_REL_ GW_BDC_FD SG_ 2348810501 L_TP_L_WPC_FD_BDC_FD_Byte17 0;
BA_REL_ "GenSigTimeoutTime" BU_SG_REL_ GW_BDC_FD SG_ 2348810501 L_TP_L_WPC_FD_BDC_FD_Byte18 0;
BA_REL_ "GenSigTimeoutTime" BU_SG_REL_ GW_BDC_FD SG_ 2348810501 L_TP_L_WPC_FD_BDC_FD_Byte19 0;
BA_REL_ "GenSigTimeoutTime" BU_SG_REL_ GW_BDC_FD SG_ 2348810501 L_TP_L_WPC_FD_BDC_FD_Byte2 0;
BA_REL_ "GenSigTimeoutTime" BU_SG_REL_ GW_BDC_FD SG_ 2348810501 L_TP_L_WPC_FD_BDC_FD_Byte20 0;
BA_REL_ "GenSigTimeoutTime" BU_SG_REL_ GW_BDC_FD SG_ 2348810501 L_TP_L_WPC_FD_BDC_FD_Byte21 0;
BA_REL_ "GenSigTimeoutTime" BU_SG_REL_ GW_BDC_FD SG_ 2348810501 L_TP_L_WPC_FD_BDC_FD_Byte22 0;
BA_REL_ "GenSigTimeoutTime" BU_SG_REL_ GW_BDC_FD SG_ 2348810501 L_TP_L_WPC_FD_BDC_FD_Byte23 0;
BA_REL_ "GenSigTimeoutTime" BU_SG_REL_ GW_BDC_FD SG_ 2348810501 L_TP_L_WPC_FD_BDC_FD_Byte24 0;
BA_REL_ "GenSigTimeoutTime" BU_SG_REL_ GW_BDC_FD SG_ 2348810501 L_TP_L_WPC_FD_BDC_FD_Byte25 0;
BA_REL_ "GenSigTimeoutTime" BU_SG_REL_ GW_BDC_FD SG_ 2348810501 L_TP_L_WPC_FD_BDC_FD_Byte26 0;
BA_REL_ "GenSigTimeoutTime" BU_SG_REL_ GW_BDC_FD SG_ 2348810501 L_TP_L_WPC_FD_BDC_FD_Byte27 0;
BA_REL_ "GenSigTimeoutTime" BU_SG_REL_ GW_BDC_FD SG_ 2348810501 L_TP_L_WPC_FD_BDC_FD_Byte28 0;
BA_REL_ "GenSigTimeoutTime" BU_SG_REL_ GW_BDC_FD SG_ 2348810501 L_TP_L_WPC_FD_BDC_FD_Byte29 0;
BA_REL_ "GenSigTimeoutTime" BU_SG_REL_ GW_BDC_FD SG_ 2348810501 L_TP_L_WPC_FD_BDC_FD_Byte3 0;
BA_REL_ "GenSigTimeoutTime" BU_SG_REL_ GW_BDC_FD SG_ 2348810501 L_TP_L_WPC_FD_BDC_FD_Byte30 0;
BA_REL_ "GenSigTimeoutTime" BU_SG_REL_ GW_BDC_FD SG_ 2348810501 L_TP_L_WPC_FD_BDC_FD_Byte31 0;
BA_REL_ "GenSigTimeoutTime" BU_SG_REL_ GW_BDC_FD SG_ 2348810501 L_TP_L_WPC_FD_BDC_FD_Byte4 0;
BA_REL_ "GenSigTimeoutTime" BU_SG_REL_ GW_BDC_FD SG_ 2348810501 L_TP_L_WPC_FD_BDC_FD_Byte5 0;
BA_REL_ "GenSigTimeoutTime" BU_SG_REL_ GW_BDC_FD SG_ 2348810501 L_TP_L_WPC_FD_BDC_FD_Byte6 0;
BA_REL_ "GenSigTimeoutTime" BU_SG_REL_ GW_BDC_FD SG_ 2348810501 L_TP_L_WPC_FD_BDC_FD_Byte7 0;
BA_REL_ "GenSigTimeoutTime" BU_SG_REL_ GW_BDC_FD SG_ 2348810501 L_TP_L_WPC_FD_BDC_FD_Byte8 0;
BA_REL_ "GenSigTimeoutTime" BU_SG_REL_ GW_BDC_FD SG_ 2348810501 L_TP_L_WPC_FD_BDC_FD_Byte9 0;
BA_REL_ "GenSigTimeoutTime" BU_SG_REL_ GW_BDC_FD SG_ 2348810501 L_TP_L_WPC_FD_BDC_FD_Byte1 0;
BA_REL_ "GenSigTimeoutTime" BU_SG_REL_ GW_BDC_FD SG_ 2348810501 L_TP_L_WPC_FD_BDC_FD_Byte10 0;
BA_REL_ "GenSigTimeoutTime" BU_SG_REL_ GW_BDC_FD SG_ 2348810501 L_TP_L_WPC_FD_BDC_FD_Byte11 0;
BA_REL_ "GenSigTimeoutTime" BU_SG_REL_ GW_BDC_FD SG_ 2348810501 L_TP_L_WPC_FD_BDC_FD_Byte12 0;
BA_REL_ "GenSigTimeoutTime" BU_SG_REL_ L_WPC_FD SG_ 2348810500 L_TP_BDC_FD_L_WPC_FD_Byte0 0;
BA_REL_ "GenSigTimeoutTime" BU_SG_REL_ L_WPC_FD SG_ 2348810500 L_TP_BDC_FD_L_WPC_FD_Byte13 0;
BA_REL_ "GenSigTimeoutTime" BU_SG_REL_ L_WPC_FD SG_ 2348810500 L_TP_BDC_FD_L_WPC_FD_Byte14 0;
BA_REL_ "GenSigTimeoutTime" BU_SG_REL_ L_WPC_FD SG_ 2348810500 L_TP_BDC_FD_L_WPC_FD_Byte15 0;
BA_REL_ "GenSigTimeoutTime" BU_SG_REL_ L_WPC_FD SG_ 2348810500 L_TP_BDC_FD_L_WPC_FD_Byte16 0;
BA_REL_ "GenSigTimeoutTime" BU_SG_REL_ L_WPC_FD SG_ 2348810500 L_TP_BDC_FD_L_WPC_FD_Byte17 0;
BA_REL_ "GenSigTimeoutTime" BU_SG_REL_ L_WPC_FD SG_ 2348810500 L_TP_BDC_FD_L_WPC_FD_Byte18 0;
BA_REL_ "GenSigTimeoutTime" BU_SG_REL_ L_WPC_FD SG_ 2348810500 L_TP_BDC_FD_L_WPC_FD_Byte19 0;
BA_REL_ "GenSigTimeoutTime" BU_SG_REL_ L_WPC_FD SG_ 2348810500 L_TP_BDC_FD_L_WPC_FD_Byte2 0;
BA_REL_ "GenSigTimeoutTime" BU_SG_REL_ L_WPC_FD SG_ 2348810500 L_TP_BDC_FD_L_WPC_FD_Byte20 0;
BA_REL_ "GenSigTimeoutTime" BU_SG_REL_ L_WPC_FD SG_ 2348810500 L_TP_BDC_FD_L_WPC_FD_Byte21 0;
BA_REL_ "GenSigTimeoutTime" BU_SG_REL_ L_WPC_FD SG_ 2348810500 L_TP_BDC_FD_L_WPC_FD_Byte22 0;
BA_REL_ "GenSigTimeoutTime" BU_SG_REL_ L_WPC_FD SG_ 2348810500 L_TP_BDC_FD_L_WPC_FD_Byte23 0;
BA_REL_ "GenSigTimeoutTime" BU_SG_REL_ L_WPC_FD SG_ 2348810500 L_TP_BDC_FD_L_WPC_FD_Byte24 0;
BA_REL_ "GenSigTimeoutTime" BU_SG_REL_ L_WPC_FD SG_ 2348810500 L_TP_BDC_FD_L_WPC_FD_Byte25 0;
BA_REL_ "GenSigTimeoutTime" BU_SG_REL_ L_WPC_FD SG_ 2348810500 L_TP_BDC_FD_L_WPC_FD_Byte26 0;
BA_REL_ "GenSigTimeoutTime" BU_SG_REL_ L_WPC_FD SG_ 2348810500 L_TP_BDC_FD_L_WPC_FD_Byte27 0;
BA_REL_ "GenSigTimeoutTime" BU_SG_REL_ L_WPC_FD SG_ 2348810500 L_TP_BDC_FD_L_WPC_FD_Byte28 0;
BA_REL_ "GenSigTimeoutTime" BU_SG_REL_ L_WPC_FD SG_ 2348810500 L_TP_BDC_FD_L_WPC_FD_Byte29 0;
BA_REL_ "GenSigTimeoutTime" BU_SG_REL_ L_WPC_FD SG_ 2348810500 L_TP_BDC_FD_L_WPC_FD_Byte3 0;
BA_REL_ "GenSigTimeoutTime" BU_SG_REL_ L_WPC_FD SG_ 2348810500 L_TP_BDC_FD_L_WPC_FD_Byte30 0;
BA_REL_ "GenSigTimeoutTime" BU_SG_REL_ L_WPC_FD SG_ 2348810500 L_TP_BDC_FD_L_WPC_FD_Byte31 0;
BA_REL_ "GenSigTimeoutTime" BU_SG_REL_ L_WPC_FD SG_ 2348810500 L_TP_BDC_FD_L_WPC_FD_Byte4 0;
BA_REL_ "GenSigTimeoutTime" BU_SG_REL_ L_WPC_FD SG_ 2348810500 L_TP_BDC_FD_L_WPC_FD_Byte5 0;
BA_REL_ "GenSigTimeoutTime" BU_SG_REL_ L_WPC_FD SG_ 2348810500 L_TP_BDC_FD_L_WPC_FD_Byte6 0;
BA_REL_ "GenSigTimeoutTime" BU_SG_REL_ L_WPC_FD SG_ 2348810500 L_TP_BDC_FD_L_WPC_FD_Byte7 0;
BA_REL_ "GenSigTimeoutTime" BU_SG_REL_ L_WPC_FD SG_ 2348810500 L_TP_BDC_FD_L_WPC_FD_Byte8 0;
BA_REL_ "GenSigTimeoutTime" BU_SG_REL_ L_WPC_FD SG_ 2348810500 L_TP_BDC_FD_L_WPC_FD_Byte9 0;
BA_REL_ "GenSigTimeoutTime" BU_SG_REL_ L_WPC_FD SG_ 2348810500 L_TP_BDC_FD_L_WPC_FD_Byte1 0;
BA_REL_ "GenSigTimeoutTime" BU_SG_REL_ L_WPC_FD SG_ 2348810500 L_TP_BDC_FD_L_WPC_FD_Byte10 0;
BA_REL_ "GenSigTimeoutTime" BU_SG_REL_ L_WPC_FD SG_ 2348810500 L_TP_BDC_FD_L_WPC_FD_Byte11 0;
BA_REL_ "GenSigTimeoutTime" BU_SG_REL_ L_WPC_FD SG_ 2348810500 L_TP_BDC_FD_L_WPC_FD_Byte12 0;
BA_REL_ "GenSigTimeoutTime" BU_SG_REL_ GW_BDC_FD SG_ 2214592656 DHR_NFCDetected 0;
BA_REL_ "GenSigTimeoutTime" BU_SG_REL_ GW_BDC_FD SG_ 2214592656 DHR_WlcmLt_Sta 0;
BA_REL_ "GenSigTimeoutTime" BU_SG_REL_ GW_BDC_FD SG_ 2214592656 DHR_NFCReset_Sta 0;
BA_REL_ "GenSigTimeoutTime" BU_SG_REL_ GW_BDC_FD SG_ 2348810499 L_TP_L_UWB_BLE_SLV_FD_BDC_FD_Byt 0;
BA_REL_ "GenSigTimeoutTime" BU_SG_REL_ GW_BDC_FD SG_ 2348810499 L_TP_L_UWB_BLE_SLV_FD_BDC_F_0000 0;
BA_REL_ "GenSigTimeoutTime" BU_SG_REL_ GW_BDC_FD SG_ 2348810499 L_TP_L_UWB_BLE_SLV_FD_BDC_F_0001 0;
BA_REL_ "GenSigTimeoutTime" BU_SG_REL_ GW_BDC_FD SG_ 2348810499 L_TP_L_UWB_BLE_SLV_FD_BDC_F_0002 0;
BA_REL_ "GenSigTimeoutTime" BU_SG_REL_ GW_BDC_FD SG_ 2348810499 L_TP_L_UWB_BLE_SLV_FD_BDC_F_0003 0;
BA_REL_ "GenSigTimeoutTime" BU_SG_REL_ GW_BDC_FD SG_ 2348810499 L_TP_L_UWB_BLE_SLV_FD_BDC_F_0004 0;
BA_REL_ "GenSigTimeoutTime" BU_SG_REL_ GW_BDC_FD SG_ 2348810499 L_TP_L_UWB_BLE_SLV_FD_BDC_F_0005 0;
BA_REL_ "GenSigTimeoutTime" BU_SG_REL_ GW_BDC_FD SG_ 2348810499 L_TP_L_UWB_BLE_SLV_FD_BDC_F_0006 0;
BA_REL_ "GenSigTimeoutTime" BU_SG_REL_ GW_BDC_FD SG_ 2348810499 L_TP_L_UWB_BLE_SLV_FD_BDC_F_0007 0;
BA_REL_ "GenSigTimeoutTime" BU_SG_REL_ GW_BDC_FD SG_ 2348810499 L_TP_L_UWB_BLE_SLV_FD_BDC_F_0008 0;
BA_REL_ "GenSigTimeoutTime" BU_SG_REL_ GW_BDC_FD SG_ 2348810499 L_TP_L_UWB_BLE_SLV_FD_BDC_F_0009 0;
BA_REL_ "GenSigTimeoutTime" BU_SG_REL_ GW_BDC_FD SG_ 2348810499 L_TP_L_UWB_BLE_SLV_FD_BDC_F_0010 0;
BA_REL_ "GenSigTimeoutTime" BU_SG_REL_ GW_BDC_FD SG_ 2348810499 L_TP_L_UWB_BLE_SLV_FD_BDC_F_0011 0;
BA_REL_ "GenSigTimeoutTime" BU_SG_REL_ GW_BDC_FD SG_ 2348810499 L_TP_L_UWB_BLE_SLV_FD_BDC_F_0012 0;
BA_REL_ "GenSigTimeoutTime" BU_SG_REL_ GW_BDC_FD SG_ 2348810499 L_TP_L_UWB_BLE_SLV_FD_BDC_F_0013 0;
BA_REL_ "GenSigTimeoutTime" BU_SG_REL_ GW_BDC_FD SG_ 2348810499 L_TP_L_UWB_BLE_SLV_FD_BDC_F_0014 0;
BA_REL_ "GenSigTimeoutTime" BU_SG_REL_ GW_BDC_FD SG_ 2348810499 L_TP_L_UWB_BLE_SLV_FD_BDC_F_0015 0;
BA_REL_ "GenSigTimeoutTime" BU_SG_REL_ GW_BDC_FD SG_ 2348810499 L_TP_L_UWB_BLE_SLV_FD_BDC_F_0016 0;
BA_REL_ "GenSigTimeoutTime" BU_SG_REL_ GW_BDC_FD SG_ 2348810499 L_TP_L_UWB_BLE_SLV_FD_BDC_F_0017 0;
BA_REL_ "GenSigTimeoutTime" BU_SG_REL_ GW_BDC_FD SG_ 2348810499 L_TP_L_UWB_BLE_SLV_FD_BDC_F_0018 0;
BA_REL_ "GenSigTimeoutTime" BU_SG_REL_ GW_BDC_FD SG_ 2348810499 L_TP_L_UWB_BLE_SLV_FD_BDC_F_0019 0;
BA_REL_ "GenSigTimeoutTime" BU_SG_REL_ GW_BDC_FD SG_ 2348810499 L_TP_L_UWB_BLE_SLV_FD_BDC_F_0020 0;
BA_REL_ "GenSigTimeoutTime" BU_SG_REL_ GW_BDC_FD SG_ 2348810499 L_TP_L_UWB_BLE_SLV_FD_BDC_F_0021 0;
BA_REL_ "GenSigTimeoutTime" BU_SG_REL_ GW_BDC_FD SG_ 2348810499 L_TP_L_UWB_BLE_SLV_FD_BDC_F_0022 0;
BA_REL_ "GenSigTimeoutTime" BU_SG_REL_ GW_BDC_FD SG_ 2348810499 L_TP_L_UWB_BLE_SLV_FD_BDC_F_0023 0;
BA_REL_ "GenSigTimeoutTime" BU_SG_REL_ GW_BDC_FD SG_ 2348810499 L_TP_L_UWB_BLE_SLV_FD_BDC_F_0024 0;
BA_REL_ "GenSigTimeoutTime" BU_SG_REL_ GW_BDC_FD SG_ 2348810499 L_TP_L_UWB_BLE_SLV_FD_BDC_F_0025 0;
BA_REL_ "GenSigTimeoutTime" BU_SG_REL_ GW_BDC_FD SG_ 2348810499 L_TP_L_UWB_BLE_SLV_FD_BDC_F_0026 0;
BA_REL_ "GenSigTimeoutTime" BU_SG_REL_ GW_BDC_FD SG_ 2348810499 L_TP_L_UWB_BLE_SLV_FD_BDC_F_0027 0;
BA_REL_ "GenSigTimeoutTime" BU_SG_REL_ GW_BDC_FD SG_ 2348810499 L_TP_L_UWB_BLE_SLV_FD_BDC_F_0028 0;
BA_REL_ "GenSigTimeoutTime" BU_SG_REL_ GW_BDC_FD SG_ 2348810499 L_TP_L_UWB_BLE_SLV_FD_BDC_F_0029 0;
BA_REL_ "GenSigTimeoutTime" BU_SG_REL_ GW_BDC_FD SG_ 2348810499 L_TP_L_UWB_BLE_SLV_FD_BDC_F_0030 0;
VAL_ 2214592656 L_DHR_FD_Crc1Val 0 "0x0x0~0xFFFF:CRCValue" 65535 "0x0x0~0xFFFF:CRCValue" ;
VAL_ 2214592656 L_DHR_FD_AlvCnt1Val 0 "0x0x0~0xFF:AlvCntValue" 255 "0x0x0~0xFF:AlvCntValue" ;
VAL_ 2214592656 DHR_NFCDetected 0 "Off" 1 "Detected" ;
VAL_ 2214592656 DHR_WlcmLt_Sta 0 "Off" 1 "On" ;
VAL_ 2214592656 DHR_NFCReset_Sta 0 "Default" 1 "Reset Complete" ;
